VERSION ""

NS_ :

BS_:

BU_: ACC GW LAS BDC mADC FC APA HPP

BO_ 652 GW_28C: 8 GW
 SG_ GW_MFS_HODCalibratedStatus : 29|1@0+ (1,0) [0|1] ""  FC,mADC
 SG_ GW_MFS_HODLinStatus : 28|1@0+ (1,0) [0|1] ""  FC,mADC
 SG_ GW_MFS_HODAppStatus : 27|1@0+ (1,0) [0|1] ""  FC,mADC
 SG_ GW_MFS_HODSenserStatus : 47|1@0+ (1,0) [0|1] ""  FC,mADC
 SG_ GW_MFS_HODSystemStatus : 23|3@0+ (1,0) [0|7] ""  FC,mADC
 SG_ GW_MFS_handsoffAbilityDetect : 26|3@0+ (1,0) [0|7] ""  FC,mADC
 SG_ GW_MFS_handsoffDetectResult : 20|3@0+ (1,0) [0|7] ""  ACC,LAS,FC,mADC
 SG_ GW_MFS_CRCCheck_28C : 63|8@0+ (1,0) [0|255] ""  ACC,FC,LAS,mADC
 SG_ GW_MFS_RollingCounter_28C : 51|4@0+ (1,0) [0|15] ""  ACC,FC,LAS,mADC
 SG_ GW_MFS_DiagInfoSW_28C : 42|3@0+ (1,0) [0|7] ""  ACC,LAS,FC,mADC
 SG_ GW_MFS_GearshiftReduce_switch : 53|2@0+ (1,0) [0|3] "" Vector__XXX
 SG_ GW_MFS_GearshiftPlus_switch : 55|2@0+ (1,0) [0|3] "" Vector__XXX
 SG_ GW_MFS_EPS_switch : 15|2@0+ (1,0) [0|3] "" Vector__XXX
 SG_ GW_MFS_ERSReduce_switch : 46|2@0+ (1,0) [0|3] "" Vector__XXX
 SG_ GW_MFS_ERSPlus_switch : 44|2@0+ (1,0) [0|3] "" Vector__XXX
 SG_ GW_MFS_IACCenable_switch_signal : 13|2@0+ (1,0) [0|3] ""  ACC,FC,LAS,mADC
 SG_ GW_MFS_LIM_switch_signal : 11|2@0+ (1,0) [0|3] ""  FC,mADC
 SG_ GW_MFS_DIST_switch_signal : 9|2@0+ (1,0) [0|3] ""  ACC,LAS,FC,mADC
 SG_ GW_MFS_SETReduce_switch_signal : 7|2@0+ (1,0) [0|3] ""  ACC,LAS,FC,mADC
 SG_ GW_MFS_RESPlus_switch_signal : 5|2@0+ (1,0) [0|3] ""  ACC,LAS,FC,mADC
 SG_ GW_MFS_Cancle_switch_signal : 3|2@0+ (1,0) [0|3] ""  ACC,LAS,FC,mADC
 SG_ GW_MFS_Crusie_switch_signal : 1|2@0+ (1,0) [0|3] ""  ACC,LAS,FC,mADC
 SG_ GW_MFS_DISTReduce_switch_signal : 31|2@0+ (1,0) [0|3] ""  LAS,FC,ACC
 SG_ GW_MFS_DISTPlus_switch_signal : 17|2@0+ (1,0) [0|3] ""  LAS,FC,ACC

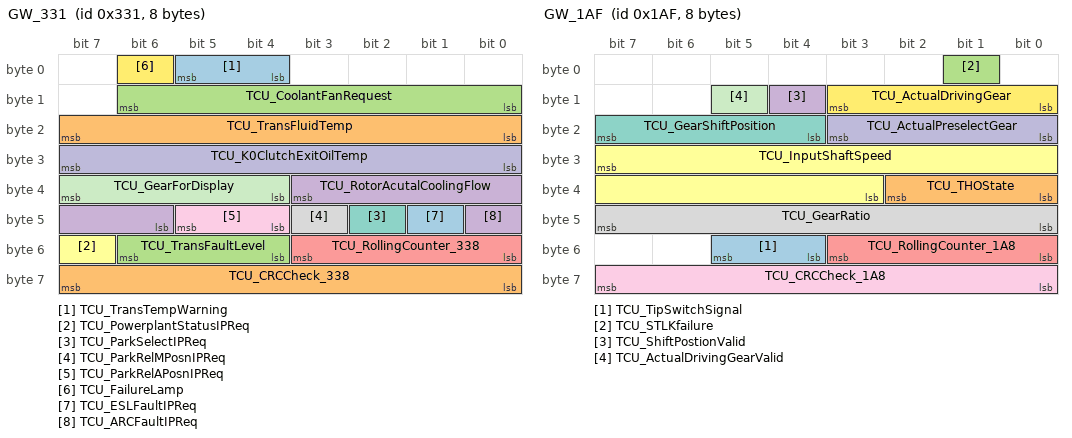
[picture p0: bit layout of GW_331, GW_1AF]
BO_ 817 GW_331: 8 GW
 SG_ TCU_TransTempWarning : 5|2@0+ (1,0) [0|3] "" Vector__XXX
 SG_ TCU_TransFluidTemp : 23|8@0+ (1,-40) [-40|214] "deg C" Vector__XXX
 SG_ TCU_TransFaultLevel : 54|3@0+ (1,0) [0|7] ""  ACC,LAS,APA,HPP
 SG_ TCU_RotorAcutalCoolingFlow : 35|6@0+ (0.1,0) [0|5] "L/min" Vector__XXX
 SG_ TCU_RollingCounter_338 : 51|4@0+ (1,0) [0|15] ""  APA
 SG_ TCU_PowerplantStatusIPReq : 55|1@0+ (1,0) [0|1] "" Vector__XXX
 SG_ TCU_ParkSelectIPReq : 42|1@0+ (1,0) [0|1] "" Vector__XXX
 SG_ TCU_ParkRelMPosnIPReq : 43|1@0+ (1,0) [0|1] "" Vector__XXX
 SG_ TCU_ParkRelAPosnIPReq : 45|2@0+ (1,0) [0|3] "" Vector__XXX
 SG_ TCU_K0ClutchExitOilTemp : 31|8@0+ (1,-40) [-40|214] "deg C" Vector__XXX
 SG_ TCU_GearForDisplay : 39|4@0+ (1,0) [0|15] "" Vector__XXX
 SG_ TCU_FailureLamp : 6|1@0+ (1,0) [0|1] "" Vector__XXX
 SG_ TCU_ESLFaultIPReq : 41|1@0+ (1,0) [0|1] "" Vector__XXX
 SG_ TCU_CRCCheck_338 : 63|8@0+ (1,0) [0|255] ""  APA
 SG_ TCU_CoolantFanRequest : 14|7@0+ (1,0) [0|100] "%" Vector__XXX
 SG_ TCU_ARCFaultIPReq : 40|1@0+ (1,0) [0|1] "" Vector__XXX

BO_ 431 GW_1AF: 8 GW
 SG_ TCU_TipSwitchSignal : 53|2@0+ (1,0) [0|3] "" Vector__XXX
 SG_ TCU_THOState : 34|3@0+ (1,0) [0|7] "" Vector__XXX
 SG_ TCU_STLKfailure : 1|1@0+ (1,0) [0|1] "" Vector__XXX
 SG_ TCU_ShiftPostionValid : 12|1@0+ (1,0) [0|1] ""  ACC,LAS,FC,APA,mADC
 SG_ TCU_RollingCounter_1A8 : 51|4@0+ (1,0) [0|15] ""  mADC,APA,ACC,LAS,FC,HPP
 SG_ TCU_InputShaftSpeed : 31|13@0+ (2.5,-10235) [-10235|10240] "Rpm" Vector__XXX
 SG_ TCU_GearShiftPosition : 23|4@0+ (1,0) [0|15] ""  APA,ACC,LAS,FC,HPP,mADC
 SG_ TCU_GearRatio : 47|8@0+ (0.1,0) [0|25.4] "" Vector__XXX
 SG_ TCU_CRCCheck_1A8 : 63|8@0+ (1,0) [0|255] ""  mADC,APA,ACC,LAS,FC,HPP
 SG_ TCU_ActualPreselectGear : 19|4@0+ (1,0) [0|15] "" Vector__XXX
 SG_ TCU_ActualDrivingGearValid : 13|1@0+ (1,0) [0|1] ""  APA,ACC,LAS,FC,HPP
 SG_ TCU_ActualDrivingGear : 11|4@0+ (1,0) [0|15] ""  APA,ACC,LAS,FC,HPP

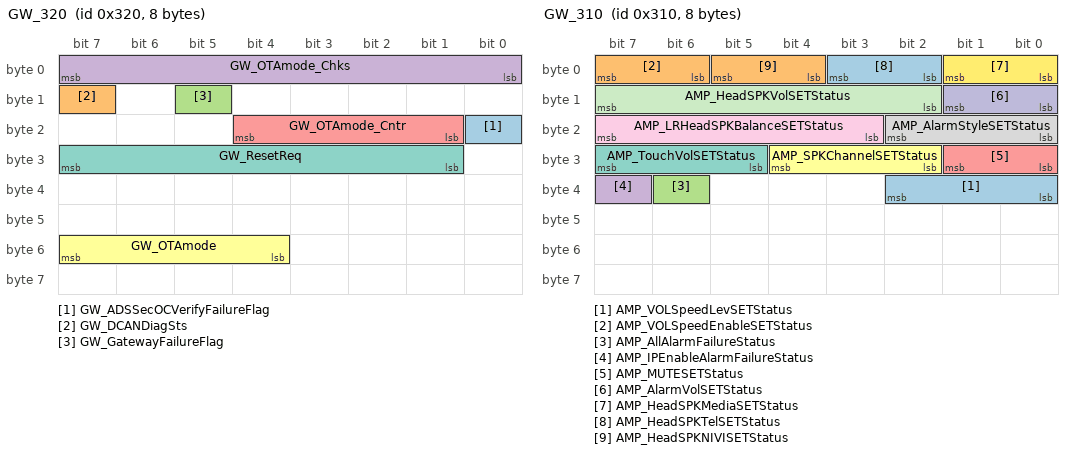
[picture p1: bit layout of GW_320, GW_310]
BO_ 800 GW_320: 8 GW
 SG_ GW_ADSSecOCVerifyFailureFlag : 16|1@0+ (1,0) [0|1] ""  mADC
 SG_ GW_DCANDiagSts : 15|1@0+ (1,0) [0|1] ""  mADC
 SG_ GW_GatewayFailureFlag : 13|1@0+ (1,0) [0|1] ""  mADC
 SG_ GW_OTAmode_Chks : 7|8@0+ (1,0) [0|255] ""  mADC
 SG_ GW_OTAmode_Cntr : 20|4@0+ (1,0) [0|15] ""  mADC
 SG_ GW_OTAmode : 55|4@0+ (1,0) [0|15] ""  mADC
 SG_ GW_ResetReq : 31|7@0+ (1,0) [0|127] ""  ACC,FC,LAS,APA,mADC

BO_ 922 LAS_39A: 64 LAS
 SG_ LAS_RoadFeature : 395|4@0+ (1,0) [0|15] ""  GW,mADC
 SG_ LAS_RD4LongDistence : 407|8@0+ (1,0) [0|255] ""  GW,mADC
 SG_ LAS_RD3LongDistence : 415|8@0+ (1,0) [0|255] ""  GW,mADC
 SG_ LAS_RD2LongDistence : 423|8@0+ (1,0) [0|255] ""  GW,mADC
 SG_ LAS_RD1LongDistence : 431|8@0+ (1,0) [0|255] ""  GW,mADC
 SG_ LAS_RD4RoadInforAvailable : 399|2@0+ (1,0) [0|3] ""  GW,mADC
 SG_ LAS_RD3RoadInforAvailable : 439|2@0+ (1,0) [0|3] ""  GW,mADC
 SG_ LAS_RD2RoadInforAvailable : 397|2@0+ (1,0) [0|3] ""  GW,mADC
 SG_ LAS_RD1RoadInforAvailable : 437|2@0+ (1,0) [0|3] ""  GW,mADC
 SG_ LAS_RollingCounter_579 : 435|4@0+ (1,0) [0|15] ""  GW,mADC
 SG_ LAS_CRCCheck_579 : 447|8@0+ (1,0) [0|255] ""  GW,mADC
 SG_ LAS_TSRSpeedLimitType : 7|2@0+ (1,0) [0|3] ""  GW
 SG_ ACC_RollingCounter_39A : 491|4@0+ (1,0) [0|15] ""  GW,mADC
 SG_ ACC_CRCCheck_39A : 503|16@0+ (1,0) [0|65535] ""  GW,mADC
 SG_ LAS_CRCCheck_3C0 : 191|8@0+ (1,0) [0|255] ""  GW,mADC
 SG_ LAS_RollingCounter_3C0 : 179|4@0+ (1,0) [0|15] ""  GW,mADC
 SG_ LAS_CRCCheck_3D4 : 127|8@0+ (1,0) [0|255] ""  GW,mADC
 SG_ LAS_RollingCounter_3D4 : 115|4@0+ (1,0) [0|15] ""  GW,mADC
 SG_ LAS_CRCCheck_332 : 63|8@0+ (1,0) [0|255] ""  GW,mADC
 SG_ LAS_RollingCounter_332 : 51|4@0+ (1,0) [0|15] ""  GW,mADC
 SG_ LAS_OverspeedSoundWarningEnSt : 27|1@0+ (1,0) [0|1] ""  GW,mADC
 SG_ LAS_TSREnable : 30|1@0+ (1,0) [0|1] ""  GW,mADC
 SG_ LAS_HMAEnableStatus : 22|1@0+ (1,0) [0|1] ""  GW,mADC
 SG_ LAS_HMALightDistribution : 8|1@0+ (1,0) [0|1] ""  GW,mADC
 SG_ LAS_HMAStatus : 44|2@0+ (1,0) [0|3] ""  GW,mADC
 SG_ LAS_TSRHostSpdLimitUnits : 41|2@0+ (1,0) [0|3] ""  GW,mADC
 SG_ LAS_TSRHostSpdLimit : 39|8@0+ (1,0) [0|255] ""  GW,mADC
 SG_ LAS_TSRStatus : 26|3@0+ (1,0) [0|7] ""  GW,mADC
 SG_ LAS_FrontCameraCalibrationStatus : 20|2@0+ (1,0) [0|3] ""  GW,mADC
 SG_ LAS_FrontCameraFailureStatus : 17|2@0+ (1,0) [0|3] ""  GW,mADC
 SG_ LAS_OverspeedWarningOffset : 14|6@0+ (1,-10) [-10|47] "km/h"  GW,mADC
 SG_ LAS_OverspeedWarningEnableStatus : 15|1@0+ (1,0) [0|1] ""  GW,mADC
 SG_ LAS_OverspeedSoundWarning : 2|1@0+ (1,0) [0|1] ""  GW,mADC
 SG_ LAS_OverspeedVisualWarning : 5|1@0+ (1,0) [0|1] ""  GW,mADC
 SG_ LAS_CRCCheck_37D : 255|8@0+ (1,0) [0|255] ""  GW,mADC
 SG_ LAS_RollingCounter_37D : 243|4@0+ (1,0) [0|15] ""  GW,mADC
 SG_ LAS_CrosswalkLngRange_HLane : 263|8@0+ (1,0) [0|255] ""  GW,mADC

BO_ 784 GW_310: 8 GW
 SG_ AMP_VOLSpeedLevSETStatus : 34|3@0+ (1,0) [0|7] "" Vector__XXX
 SG_ AMP_VOLSpeedEnableSETStatus : 7|2@0+ (1,0) [0|3] "" Vector__XXX
 SG_ AMP_AllAlarmFailureStatus : 38|1@0+ (1,0) [0|1] ""  ACC,LAS
 SG_ AMP_IPEnableAlarmFailureStatus : 39|1@0+ (1,0) [0|1] ""  ACC,LAS
 SG_ AMP_MUTESETStatus : 25|2@0+ (1,0) [0|3] "" Vector__XXX
 SG_ AMP_SPKChannelSETStatus : 28|3@0+ (1,0) [0|7] "" Vector__XXX
 SG_ AMP_TouchVolSETStatus : 31|3@0+ (1,0) [0|7] "" Vector__XXX
 SG_ AMP_AlarmStyleSETStatus : 18|3@0+ (1,0) [0|7] "" Vector__XXX
 SG_ AMP_LRHeadSPKBalanceSETStatus : 23|5@0+ (1,-16) [-16|15] "" Vector__XXX
 SG_ AMP_AlarmVolSETStatus : 9|2@0+ (1,0) [0|3] "" Vector__XXX
 SG_ AMP_HeadSPKVolSETStatus : 15|6@0+ (1,0) [0|63] "" Vector__XXX
 SG_ AMP_HeadSPKMediaSETStatus : 1|2@0+ (1,0) [0|3] "" Vector__XXX
 SG_ AMP_HeadSPKTelSETStatus : 3|2@0+ (1,0) [0|3] "" Vector__XXX
 SG_ AMP_HeadSPKNIVISETStatus : 5|2@0+ (1,0) [0|3] "" Vector__XXX

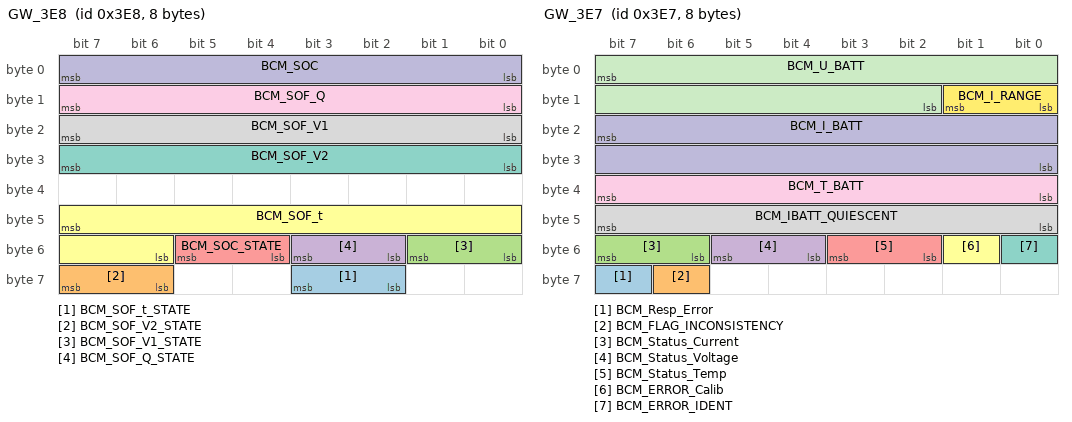
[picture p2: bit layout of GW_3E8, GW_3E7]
BO_ 1000 GW_3E8: 8 GW
 SG_ BCM_SOF_t_STATE : 59|2@0+ (1,0) [0|3] "" Vector__XXX
 SG_ BCM_SOF_V2_STATE : 63|2@0+ (1,0) [0|3] "" Vector__XXX
 SG_ BCM_SOF_V1_STATE : 49|2@0+ (1,0) [0|3] "" Vector__XXX
 SG_ BCM_SOF_Q_STATE : 51|2@0+ (1,0) [0|3] ""  ACC,LAS,FC
 SG_ BCM_SOC_STATE : 53|2@0+ (1,0) [0|3] "" Vector__XXX
 SG_ BCM_SOF_t : 47|10@0+ (1,0) [0|1023] "min" Vector__XXX
 SG_ BCM_SOF_V2 : 31|8@0+ (0.0625,0) [0|15.9375] "V" Vector__XXX
 SG_ BCM_SOF_V1 : 23|8@0+ (0.0625,0) [0|15.9375] "V" Vector__XXX
 SG_ BCM_SOF_Q : 15|8@0+ (0.5,0) [0|127.5] "Ah"  ACC,LAS,FC,APA
 SG_ BCM_SOC : 7|8@0+ (1,0) [0|255] "%"  APA

BO_ 999 GW_3E7: 8 GW
 SG_ BCM_Resp_Error : 63|1@0+ (1,0) [0|1] "" Vector__XXX
 SG_ BCM_FLAG_INCONSISTENCY : 62|1@0+ (1,0) [0|1] "" Vector__XXX
 SG_ BCM_Status_Current : 55|2@0+ (1,0) [0|3] "" Vector__XXX
 SG_ BCM_Status_Voltage : 53|2@0+ (1,0) [0|3] "" Vector__XXX
 SG_ BCM_Status_Temp : 51|2@0+ (1,0) [0|3] ""  ACC,LAS,FC
 SG_ BCM_ERROR_Calib : 49|1@0+ (1,0) [0|1] "" Vector__XXX
 SG_ BCM_ERROR_IDENT : 48|1@0+ (1,0) [0|1] "" Vector__XXX
 SG_ BCM_IBATT_QUIESCENT : 47|8@0+ (0.00390625,0) [0|0.99609375] "A" Vector__XXX
 SG_ BCM_T_BATT : 39|8@0+ (1,-40) [-40|215] "°C"  ACC,LAS,FC
 SG_ BCM_I_BATT : 23|16@0+ (1,0) [7168|65535] "A" Vector__XXX
 SG_ BCM_U_BATT : 7|14@0+ (0.0009765625,3) [3|18] "V" Vector__XXX
 SG_ BCM_I_RANGE : 9|2@0+ (1,0) [0|3] "" Vector__XXX

BO_ 906 GW_38A: 8 GW
 SG_ GW_MFS_WeChat_switch_signal : 39|2@0+ (1,0) [0|3] "" Vector__XXX
 SG_ GW_MFS_AVM_switch : 44|2@0+ (1,0) [0|3] ""  APA
 SG_ GW_MFS_DiagInfoSW_38A : 42|3@0+ (1,0) [0|7] "" Vector__XXX
 SG_ GW_MFS_Cust_switch : 17|2@0+ (1,0) [0|3] "" Vector__XXX
 SG_ GW_MFS_DVR_switch : 15|2@0+ (1,0) [0|3] ""  APA
 SG_ GW_MFS_Mode_switch : 13|2@0+ (1,0) [0|3] "" Vector__XXX
 SG_ GW_MFS_VolReduce_switch : 21|2@0+ (1,0) [0|3] ""  LAS,ACC
 SG_ GW_MFS_VolPlus_switch : 19|2@0+ (1,0) [0|3] ""  LAS,ACC
 SG_ GW_MFS_UP_switch : 5|2@0+ (1,0) [0|3] ""  LAS,ACC
 SG_ GW_MFS_Speech_switch : 11|2@0+ (1,0) [0|3] ""  LAS,ACC
 SG_ GW_MFS_SeekPlus_switch : 25|2@0+ (1,0) [0|3] ""  LAS,ACC
 SG_ GW_MFS_Right_switch : 3|2@0+ (1,0) [0|3] ""  LAS,ACC
 SG_ GW_MFS_OK_switch : 9|2@0+ (1,0) [0|3] ""  LAS,ACC
 SG_ GW_MFS_Mute_switch : 23|2@0+ (1,0) [0|3] ""  LAS,ACC
 SG_ GW_MFS_Left_switch : 1|2@0+ (1,0) [0|3] ""  LAS,ACC
 SG_ GW_MFS_Hungup_switch_signal : 29|2@0+ (1,0) [0|3] ""  LAS,ACC
 SG_ GW_MFS_Down_switch : 7|2@0+ (1,0) [0|3] ""  LAS,ACC
 SG_ GW_MFS_Answer_switch_signal : 31|2@0+ (1,0) [0|3] ""  LAS,ACC
 SG_ GW_MFS_SeekReduce_switch : 27|2@0+ (1,0) [0|3] ""  LAS,ACC

BO_ 585 GW_249: 8 GW

BO_ 610 GW_262: 8 GW
 SG_ PEPS_RemoteStartKeyStatus : 43|2@0+ (1,0) [0|3] ""  APA
 SG_ PEPS_APA_PowerMirrorFoldFeedback : 26|2@0+ (1,0) [0|3] ""  APA,mADC
 SG_ PEPS_APARemoteParkingOff : 53|1@0+ (1,0) [0|1] ""  APA,mADC
 SG_ PEPS_KeyStandbyPositionIndicator : 54|1@0+ (1,0) [0|1] "" Vector__XXX
 SG_ PEPS_CRCCheck_262 : 63|8@0+ (1,0) [0|255] ""  APA,mADC
 SG_ PEPS_RollingCounter_262 : 51|4@0+ (1,0) [0|15] ""  APA,mADC
 SG_ PEPS_PEPSFailStatus : 55|1@0+ (1,0) [0|1] ""  APA,mADC
 SG_ PEPS_PowerDistributionFaultBit : 47|1@0+ (1,0) [0|1] "" Vector__XXX
 SG_ PEPS_IMMOFeedback : 45|2@0+ (1,0) [0|3] "" Vector__XXX
 SG_ PEPS_EngineStartupInhibitFB : 46|1@0+ (1,0) [0|1] "" Vector__XXX
 SG_ PEPS_RemoteStartFeedback : 31|5@0+ (1,0) [0|31] ""  mADC
 SG_ PEPS_EngineStartupInhibitSts : 24|1@0+ (1,0) [0|1] "" Vector__XXX
 SG_ PEPS_PowerDistributionStatus : 23|2@0+ (1,0) [0|3] "" Vector__XXX
 SG_ PEPS_UnallowStartSignal_Not_PN : 19|1@0+ (1,0) [0|1] "" Vector__XXX
 SG_ PEPS_IMMOFailedAlarmsignal : 18|1@0+ (1,0) [0|1] "" Vector__XXX
 SG_ PEPS_UnallowStart_ESCL_LOCK : 21|1@0+ (1,0) [0|1] "" Vector__XXX
 SG_ PEPS_UnallowStart_ESCL_Error : 15|1@0+ (1,0) [0|1] "" Vector__XXX
 SG_ PEPS_StartIndicatorSignal : 7|1@0+ (1,0) [0|1] "" Vector__XXX
 SG_ PEPS_StartupButtonSignal : 17|2@0+ (1,0) [0|3] "" Vector__XXX
 SG_ PEPS_APA_CloseWinFeedback : 11|2@0+ (1,0) [0|3] ""  APA,mADC
 SG_ PEPS_RemoteControlACReq : 9|2@0+ (1,0) [0|3] "" Vector__XXX
 SG_ PEPS_RemoteAPADoneKeyOffReq : 6|2@0+ (1,0) [0|3] ""  APA,mADC
 SG_ PEPS_APA_Engine0ffFeedback : 4|2@0+ (1,0) [0|3] ""  APA,mADC
 SG_ PEPS_APA_LockFeedback : 2|2@0+ (1,0) [0|3] ""  APA,mADC
 SG_ PEPS_APARemoteParkingOn : 0|1@0+ (1,0) [0|1] ""  APA,mADC

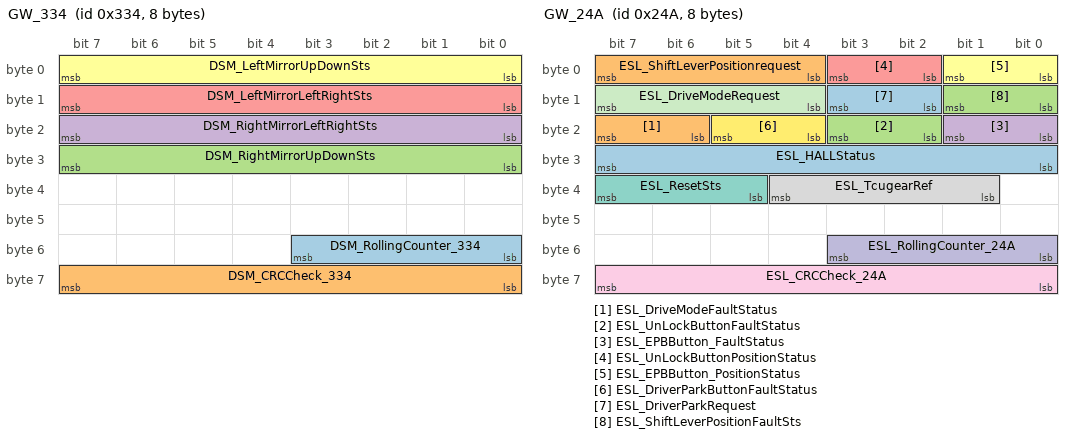
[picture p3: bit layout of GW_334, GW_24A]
BO_ 820 GW_334: 8 GW
 SG_ DSM_RollingCounter_334 : 51|4@0+ (1,0) [0|15] ""  APA
 SG_ DSM_CRCCheck_334 : 63|8@0+ (1,0) [0|255] ""  APA
 SG_ DSM_RightMirrorUpDownSts : 31|8@0+ (0.5,0) [0|127.5] "%"  APA
 SG_ DSM_RightMirrorLeftRightSts : 23|8@0+ (0.5,0) [0|127.5] "%"  APA
 SG_ DSM_LeftMirrorLeftRightSts : 15|8@0+ (0.5,0) [0|127.5] "%"  APA
 SG_ DSM_LeftMirrorUpDownSts : 7|8@0+ (0.5,0) [0|127.5] "%"  APA

BO_ 917 GW_395: 64 GW
 SG_ TBOX_EseUpdataHUWakeUpReq : 11|1@0+ (1,0) [0|1] "" Vector__XXX
 SG_ TBOX_RemoteInstallReq : 57|2@0+ (1,0) [0|3] "" Vector__XXX
 SG_ TBOX_RemotePaVentilatieReq : 60|3@0+ (1,0) [0|7] "" Vector__XXX
 SG_ TBOX_RemoteDrVentilatieReq : 63|3@0+ (1,0) [0|7] "" Vector__XXX
 SG_ TBOX_BCallStatus : 23|3@0+ (1,0) [0|7] "" Vector__XXX
 SG_ TBOX_AudioRequest : 14|2@0+ (1,0) [0|3] "" Vector__XXX
 SG_ TBOX_ChangePartStatus : 12|1@0+ (1,0) [0|1] "" Vector__XXX
 SG_ TBOX_CallStatus : 10|3@0+ (1,0) [0|7] "" Vector__XXX
 SG_ TBOX_RemoteAirCleanReq : 53|2@0+ (1,0) [0|3] "" Vector__XXX
 SG_ TBOX_RemoteAirQualityInquire : 49|2@0+ (1,0) [0|3] "" Vector__XXX
 SG_ TBOX_RemoteSteerWheelHotReq : 47|2@0+ (1,0) [0|3] "" Vector__XXX
 SG_ TBOX_RemoteDriverSeatHotReq : 45|3@0+ (1,0) [0|7] "" Vector__XXX
 SG_ TBOX_RemotePassangerSeatHotReq : 42|3@0+ (1,0) [0|7] "" Vector__XXX
 SG_ TBOX_SearchCarReq : 39|2@0+ (1,0) [0|3] "" Vector__XXX
 SG_ TBOX_RmoteTrunk : 37|2@0+ (1,0) [0|3] "" Vector__XXX
 SG_ TBOX_RmoteRoof : 35|2@0+ (1,0) [0|3] "" Vector__XXX
 SG_ TBOX_RemoteACStartupReq : 33|2@0+ (1,0) [0|3] "" Vector__XXX
 SG_ TBOX_VehicleStatusDemandReq : 31|1@0+ (1,0) [0|1] "" Vector__XXX
 SG_ TBOX_RemoteStartRunTime : 30|3@0+ (1,0) [0|7] "" Vector__XXX
 SG_ TBOX_VINMatchStatus : 27|2@0+ (1,0) [0|3] "" Vector__XXX
 SG_ TBOX_VINReq : 25|2@0+ (1,0) [0|3] "" Vector__XXX
 SG_ TBOX_ACTempValueReq : 20|5@0+ (1,0) [0|31] "degreeC" Vector__XXX
 SG_ TBOX_CarRemind : 15|1@0+ (1,0) [0|1] "" Vector__XXX
 SG_ TBOX_RemoteEngineStartupReq : 7|2@0+ (1,0) [0|3] "" Vector__XXX
 SG_ TBOX_EngineStartupInhibit : 5|2@0+ (1,0) [0|3] "" Vector__XXX
 SG_ TBOX_LockCommand : 3|2@0+ (1,0) [0|3] "" Vector__XXX
 SG_ TBox_ResetFlag_395 : 489|2@0+ (1,0) [0|3] ""  APA
 SG_ TBox_MesssageCounter_395 : 495|6@0+ (1,0) [0|63] ""  APA
 SG_ TBox_Authenticator_395 : 503|16@0+ (1,0) [0|0] ""  APA
 SG_ TBOX_APARemoteDriveReq : 95|3@0+ (1,0) [0|7] ""  APA
 SG_ TBOX_HZPFunctionReq : 102|3@0+ (1,0) [0|7] ""  APA
 SG_ TBOX_HZPControlEnable : 99|4@0+ (1,0) [0|15] ""  APA
 SG_ TBOX_SignalStrength : 89|3@0+ (1,0) [0|7] ""  APA,mADC
 SG_ TBOX_SignalType : 92|3@0+ (1,0) [0|7] ""  APA,mADC
 SG_ TBOX_APA_SignalDelay : 87|4@0+ (1,0) [0|15] ""  APA,mADC
 SG_ TBOX_APA_VideoDelay : 75|4@0+ (1,0) [0|15] ""  APA
 SG_ TBOX_AVM_DisplayForm : 111|3@0+ (1,0) [0|7] ""  APA
 SG_ TBOX_TurnRight : 81|1@0+ (1,0) [0|1] ""  APA
 SG_ TBOX_TurnLeft : 80|1@0+ (1,0) [0|1] ""  APA
 SG_ TBOX_Verticalforward : 76|1@0+ (1,0) [0|1] ""  APA
 SG_ TBOX_Verticalbackward : 77|1@0+ (1,0) [0|1] ""  APA
 SG_ TBOX_APAPOCModeSelect : 66|3@0+ (1,0) [0|7] ""  APA
 SG_ TBOX_APAFuctionSelection : 79|2@0+ (1,0) [0|3] ""  APA
 SG_ TBOX_APAManeuverSuspend : 67|1@0+ (1,0) [0|1] ""  APA
 SG_ TBOX_APAManeuverStart : 68|1@0+ (1,0) [0|1] ""  APA
 SG_ TBOX_APAManeuverCancel : 69|1@0+ (1,0) [0|1] ""  APA
 SG_ TBOX_APAmoduleEnable : 71|2@0+ (1,0) [0|3] ""  APA,mADC
 SG_ TBOX_RemoteDisReq : 50|1@0+ (1,0) [0|1] ""  APA,mADC
 SG_ TBOX_VehicleVedioDetectReq : 1|2@0+ (1,0) [0|3] ""  APA,mADC
 SG_ TBOX_RemoteDetectReq : 55|2@0+ (1,0) [0|3] ""  APA,mADC

BO_ 394 GW_18A: 8 GW
 SG_ TCU_APAShiftGearRequestEnable : 2|2@0+ (1,0) [0|3] ""  APA,BDC
 SG_ TCU_APAdriverInterruption : 4|2@0+ (1,0) [0|3] ""  APA,mADC

BO_ 586 GW_24A: 8 GW
 SG_ ESL_HALLStatus : 31|8@0+ (1,0) [0|255] ""  BDC
 SG_ ESL_DriveModeFaultStatus : 23|2@0+ (1,0) [0|3] ""  BDC
 SG_ ESL_UnLockButtonFaultStatus : 19|2@0+ (1,0) [0|3] ""  BDC
 SG_ ESL_EPBButton_FaultStatus : 17|2@0+ (1,0) [0|3] ""  BDC
 SG_ ESL_UnLockButtonPositionStatus : 3|2@0+ (1,0) [0|3] ""  BDC
 SG_ ESL_EPBButton_PositionStatus : 1|2@0+ (1,0) [0|3] ""  BDC
 SG_ ESL_ResetSts : 39|3@0+ (1,0) [0|7] ""  BDC
 SG_ ESL_TcugearRef : 36|4@0+ (1,0) [0|15] ""  BDC
 SG_ ESL_CRCCheck_24A : 63|8@0+ (1,0) [0|255] ""  BDC,APA,mADC
 SG_ ESL_RollingCounter_24A : 51|4@0+ (1,0) [0|15] ""  BDC,APA,mADC
 SG_ ESL_DriveModeRequest : 15|4@0+ (1,0) [0|15] ""  BDC,APA,mADC
 SG_ ESL_DriverParkButtonFaultStatus : 21|2@0+ (1,0) [0|3] ""  BDC,APA,mADC
 SG_ ESL_DriverParkRequest : 11|2@0+ (1,0) [0|3] ""  BDC,APA,mADC
 SG_ ESL_ShiftLeverPositionrequest : 7|4@0+ (1,0) [0|15] ""  BDC,APA,ACC,LAS,mADC
 SG_ ESL_ShiftLeverPositionFaultSts : 9|2@0+ (1,0) [0|3] ""  BDC,APA,ACC,LAS,mADC

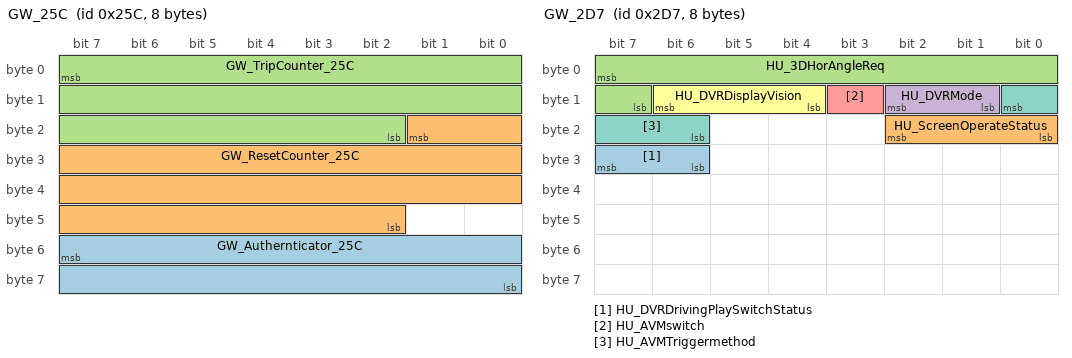
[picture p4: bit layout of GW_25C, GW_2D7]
BO_ 604 GW_25C: 8 GW
 SG_ GW_Authernticator_25C : 55|16@0+ (1,0) [0|65535] ""  APA,mADC
 SG_ GW_ResetCounter_25C : 17|24@0+ (1,0) [0|16777215] ""  APA,mADC
 SG_ GW_TripCounter_25C : 7|22@0+ (1,0) [0|4194303] ""  APA,mADC

BO_ 727 GW_2D7: 8 GW
 SG_ HU_DVRDrivingPlaySwitchStatus : 31|2@0+ (1,0) [0|3] ""  APA
 SG_ HU_ScreenOperateStatus : 18|3@0+ (1,0) [0|7] ""  APA
 SG_ HU_3DHorAngleReq : 7|9@0+ (1,0) [0|360] "°"  APA
 SG_ HU_DVRMode : 10|2@0+ (1,0) [0|3] ""  APA
 SG_ HU_AVMswitch : 11|1@0+ (1,0) [0|1] ""  APA
 SG_ HU_DVRDisplayVision : 14|3@0+ (1,0) [0|7] ""  APA
 SG_ HU_AVMTriggermethod : 8|3@0+ (1,0) [0|7] ""  APA

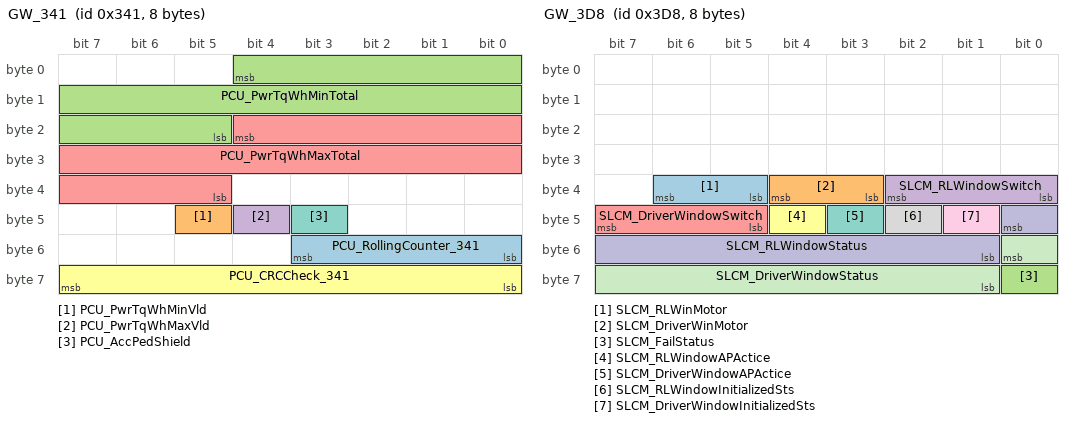
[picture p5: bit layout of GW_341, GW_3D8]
BO_ 833 GW_341: 8 GW
 SG_ PCU_RollingCounter_341 : 51|4@0+ (1,0) [0|15] ""  APA
 SG_ PCU_PwrTqWhMinVld : 45|1@0+ (1,0) [0|1] ""  APA,ACC,LAS,FC,mADC
 SG_ PCU_PwrTqWhMinTotal : 4|16@0+ (1,-32768) [-32768|32767] "Nm"  APA,ACC,LAS,FC,mADC
 SG_ PCU_PwrTqWhMaxVld : 44|1@0+ (1,0) [0|1] ""  APA,ACC,LAS,FC,mADC
 SG_ PCU_PwrTqWhMaxTotal : 20|16@0+ (1,-32768) [-32768|32767] "Nm"  APA,ACC,LAS,FC,mADC
 SG_ PCU_CRCCheck_341 : 63|8@0+ (1,0) [0|255] ""  APA
 SG_ PCU_AccPedShield : 43|1@0+ (1,0) [0|1] ""  mADC,APA

BO_ 982 GW_3D6: 8 GW
 SG_ SLCM_RRWindowStatus : 40|8@0+ (0.5,0) [0|127.5] "%"  APA,mADC
 SG_ SLCM_FRWindowStatus : 48|8@0+ (0.5,0) [0|127.5] "%"  APA,mADC

BO_ 984 GW_3D8: 8 GW
 SG_ SLCM_RLWinMotor : 38|2@0+ (1,0) [0|3] "" Vector__XXX
 SG_ SLCM_DriverWinMotor : 36|2@0+ (1,0) [0|3] "" Vector__XXX
 SG_ SLCM_FailStatus : 56|1@0+ (1,0) [0|1] "" Vector__XXX
 SG_ SLCM_RLWindowSwitch : 34|3@0+ (1,0) [0|7] "" Vector__XXX
 SG_ SLCM_DriverWindowSwitch : 47|3@0+ (1,0) [0|7] "" Vector__XXX
 SG_ SLCM_RLWindowAPActice : 44|1@0+ (1,0) [0|1] "" Vector__XXX
 SG_ SLCM_DriverWindowAPActice : 43|1@0+ (1,0) [0|1] "" Vector__XXX
 SG_ SLCM_RLWindowInitializedSts : 42|1@0+ (1,0) [0|1] "" Vector__XXX
 SG_ SLCM_DriverWindowInitializedSts : 41|1@0+ (1,0) [0|1] "" Vector__XXX
 SG_ SLCM_RLWindowStatus : 40|8@0+ (0.5,0) [0|127.5] "%"  APA,mADC
 SG_ SLCM_DriverWindowStatus : 48|8@0+ (0.5,0) [0|127.5] "%"  APA,mADC

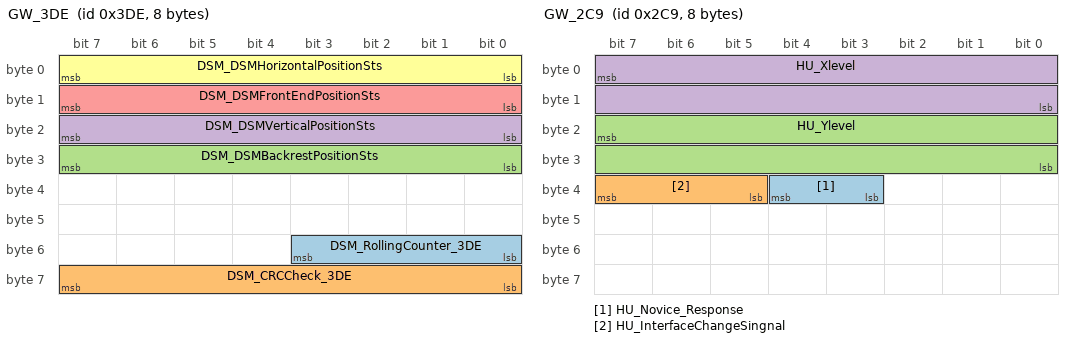
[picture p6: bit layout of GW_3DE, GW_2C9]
BO_ 990 GW_3DE: 8 GW
 SG_ DSM_RollingCounter_3DE : 51|4@0+ (1,0) [0|15] ""  APA
 SG_ DSM_CRCCheck_3DE : 63|8@0+ (1,0) [0|255] ""  APA
 SG_ DSM_DSMBackrestPositionSts : 31|8@0+ (0.5,0) [0|127.5] "%"  APA
 SG_ DSM_DSMVerticalPositionSts : 23|8@0+ (0.5,0) [0|127.5] "%"  APA
 SG_ DSM_DSMFrontEndPositionSts : 15|8@0+ (0.5,0) [0|127.5] "%"  APA
 SG_ DSM_DSMHorizontalPositionSts : 7|8@0+ (0.5,0) [0|127.5] "%"  APA

BO_ 1006 GW_3EE: 8 GW
 SG_ GW_SafCertSts : 7|2@0+ (1,0) [0|3] ""  APA

BO_ 1712 GW_6B0: 8 GW
 SG_ GW_APA_AuthenticationStatus : 7|64@0+ (1,0) [0|0] ""  APA

BO_ 723 ACC_2D3: 64 ACC
 SG_ ACC_CRCCheck_283 : 127|8@0+ (1,0) [0|255] ""  GW,ACC,LAS
 SG_ ACC_RollingCounter_283 : 115|4@0+ (1,0) [0|15] ""  GW,ACC,LAS
 SG_ ACC_AEBTargetLatRelSpeed_for_SRS : 77|10@0+ (0.125,-64) [-64|63.875] "m/s"  GW,ACC,LAS,mADC
 SG_ ACC_AEBTargetLatRange_for_SRS : 71|10@0+ (0.1,-50) [-50|50] "m"  GW,ACC,LAS,mADC
 SG_ ACC_CRCCheckr_282 : 63|8@0+ (1,0) [0|255] ""  GW,ACC,LAS
 SG_ ACC_RollingCounter_282 : 51|4@0+ (1,0) [0|15] ""  GW,ACC,LAS
 SG_ ACC_AEBTargetProb_for_SRS : 38|7@0+ (1,0) [0|100] "%"  GW,ACC,LAS,mADC
 SG_ ACC_AEBTargetType_for_SRS : 26|4@0+ (1,0) [0|15] ""  GW,ACC,LAS,mADC
 SG_ ACC_AEBTargetTTC_for_SRS : 18|8@0+ (0.01,0.01) [0.01|2.5] "s"  GW,ACC,LAS,mADC
 SG_ ACC_AEBTargetRelSpeed_for_SRS : 11|9@0+ (1,-250) [-250|250] "km/h"  GW,ACC,LAS,mADC
 SG_ ACC_AEBTargetLngRange_for_SRS : 4|9@0+ (0.5,-70) [-70|180] "m"  GW,ACC,LAS,mADC
 SG_ ACC_AEBActive_for_SRS : 5|1@0+ (1,0) [0|1] ""  GW,ACC,LAS,mADC
 SG_ ACC_AEBStatus_for_SRS : 7|2@0+ (1,0) [0|3] ""  GW,ACC,LAS,mADC

BO_ 769 ACC_301: 8 ACC
 SG_ ACC_ResetSts : 7|3@0+ (1,0) [0|7] ""  GW

BO_ 780 LAS_30C: 8 LAS
 SG_ LAS_ResetSts : 7|3@0+ (1,0) [0|7] ""  FC,GW

BO_ 738 GW_2E2: 64 GW
 SG_ RLR_CRCCheck_2E2 : 503|16@0+ (1,0) [0|65535] ""  LAS
 SG_ RLR_RollingCounter_2E2 : 491|4@0+ (1,0) [0|15] ""  LAS
 SG_ RLR_ElkOBJ2_Measured : 313|2@0+ (1,0) [0|3] ""  LAS
 SG_ RLR_ElkOBJ2_ExistProb : 319|6@0+ (2,0) [0|100] "%"  LAS
 SG_ RLR_ElkOBJ2_Location : 305|2@0+ (1,0) [0|3] ""  LAS
 SG_ RLR_ElkOBJ2_RelAx : 298|9@0+ (0.0625,-16) [-16|15.9375] "m/s2"  LAS
 SG_ RLR_ElkOBJ2_RelAy : 292|10@0+ (0.03125,-16) [-16|15.9688] "m/s2"  LAS
 SG_ RLR_ElkOBJ2_RelVx : 272|12@0+ (0.0625,-128) [-128|127.938] "m/s"  LAS
 SG_ RLR_ElkOBJ2_RelVy : 266|10@0+ (0.125,-64) [-64|63.875] "m/s"  LAS
 SG_ RLR_ElkOBJ2_Dx : 263|13@0+ (0.0625,-256) [-256|255.938] "m"  LAS
 SG_ RLR_ElkOBJ2_RefPointLoc : 251|3@0+ (1,0) [0|7] ""  LAS
 SG_ RLR_ElkOBJ2_Dy : 246|11@0+ (0.125,-128) [-128|127.875] "m"  LAS
 SG_ RLR_ElkOBJ2_HeadingAngle : 224|10@0+ (0.01,-3.14) [-3.14|3.14] "rad"  LAS
 SG_ RLR_ElkOBJ2_Length : 217|9@0+ (0.05,0) [0|25.5] "m"  LAS
 SG_ RLR_ElkOBJ2_Height : 210|9@0+ (0.01,0) [0|5.11] "m"  LAS
 SG_ RLR_ElkOBJ2_Width : 205|11@0+ (0.01,0) [0|12] "m"  LAS
 SG_ RLR_ElkOBJ2_Type : 192|3@0+ (1,0) [0|7] ""  LAS
 SG_ RLR_ElkOBJ2_Track_ID : 199|7@0+ (1,0) [0|127] ""  LAS
 SG_ RLR_ElkOBJ2_RefPointDx : 168|13@0+ (0.0625,-256) [-256|255.938] "m"  LAS
 SG_ RLR_ElkOBJ2_RefPointDy : 163|11@0+ (0.125,-128) [-128|127.875] "m"  LAS
 SG_ RLR_ElkOBJ2_ObstacleProb : 153|6@0+ (2,0) [0|100] "%"  LAS
 SG_ RLR_ElkOBJ1_RefPointDx : 150|13@0+ (0.0625,-256) [-256|255.938] "m"  LAS
 SG_ RLR_ElkOBJ1_RefPointDy : 129|11@0+ (0.125,-128) [-128|127.875] "m"  LAS
 SG_ RLR_ElkOBJ1_ObstacleProb : 135|6@0+ (2,0) [0|100] "%"  LAS
 SG_ RLR_ElkOBJ1_Measured : 121|2@0+ (1,0) [0|3] ""  LAS
 SG_ RLR_ElkOBJ1_ExistProb : 127|6@0+ (2,0) [0|100] "%"  LAS
 SG_ RLR_ElkOBJ1_Location : 113|2@0+ (1,0) [0|3] ""  LAS
 SG_ RLR_ElkOBJ1_RelAx : 106|9@0+ (0.0625,-16) [-16|15.9375] "m/s2"  LAS
 SG_ RLR_ElkOBJ1_RelAy : 100|10@0+ (0.03125,-16) [-16|15.9688] "m/s2"  LAS
 SG_ RLR_ElkOBJ1_RelVx : 80|12@0+ (0.0625,-128) [-128|127.938] "m/s"  LAS
 SG_ RLR_ElkOBJ1_RelVy : 74|10@0+ (0.125,-64) [-64|63.875] "m/s"  LAS
 SG_ RLR_ElkOBJ1_Dx : 71|13@0+ (0.0625,-256) [-256|255.938] "m"  LAS
 SG_ RLR_ElkOBJ1_RefPointLoc : 59|3@0+ (1,0) [0|7] ""  LAS
 SG_ RLR_ElkOBJ1_Dy : 54|11@0+ (0.125,-128) [-128|127.875] "m"  LAS
 SG_ RLR_ElkOBJ1_HeadingAngle : 32|10@0+ (0.01,-3.14) [-3.14|3.14] "rad"  LAS
 SG_ RLR_ElkOBJ1_Length : 25|9@0+ (0.05,0) [0|25.5] "m"  LAS
 SG_ RLR_ElkOBJ1_Height : 18|9@0+ (0.01,0) [0|5.11] "m"  LAS
 SG_ RLR_ElkOBJ1_Width : 13|11@0+ (0.01,0) [0|12] "m"  LAS
 SG_ RLR_ElkOBJ1_Type : 0|3@0+ (1,0) [0|7] ""  LAS
 SG_ RLR_ElkOBJ1_Track_ID : 7|7@0+ (1,0) [0|127] ""  LAS

BO_ 739 GW_2E3: 64 GW
 SG_ RLR_CRCCheck_2E3 : 503|16@0+ (1,0) [0|65535] ""  LAS
 SG_ RLR_RollingCounter_2E3 : 491|4@0+ (1,0) [0|15] ""  LAS
 SG_ RLR_ElkOBJ4_Measured : 313|2@0+ (1,0) [0|3] ""  LAS
 SG_ RLR_ElkOBJ4_ExistProb : 319|6@0+ (2,0) [0|100] "%"  LAS
 SG_ RLR_ElkOBJ4_Location : 305|2@0+ (1,0) [0|3] ""  LAS
 SG_ RLR_ElkOBJ4_RelAx : 298|9@0+ (0.0625,-16) [-16|15.9375] "m/s2"  LAS
 SG_ RLR_ElkOBJ4_RelAy : 292|10@0+ (0.03125,-16) [-16|15.9688] "m/s2"  LAS
 SG_ RLR_ElkOBJ4_RelVx : 272|12@0+ (0.0625,-128) [-128|127.938] "m/s"  LAS
 SG_ RLR_ElkOBJ4_RelVy : 266|10@0+ (0.125,-64) [-64|63.875] "m/s"  LAS
 SG_ RLR_ElkOBJ4_Dx : 263|13@0+ (0.0625,-256) [-256|255.938] "m"  LAS
 SG_ RLR_ElkOBJ4_RefPointLoc : 251|3@0+ (1,0) [0|7] ""  LAS
 SG_ RLR_ElkOBJ4_Dy : 246|11@0+ (0.125,-128) [-128|127.875] "m"  LAS
 SG_ RLR_ElkOBJ4_HeadingAngle : 224|10@0+ (0.01,-3.14) [-3.14|3.14] "rad"  LAS
 SG_ RLR_ElkOBJ4_Length : 217|9@0+ (0.05,0) [0|25.5] "m"  LAS
 SG_ RLR_ElkOBJ4_Height : 210|9@0+ (0.01,0) [0|5.11] "m"  LAS
 SG_ RLR_ElkOBJ4_Width : 205|11@0+ (0.01,0) [0|12] "m"  LAS
 SG_ RLR_ElkOBJ4_Type : 192|3@0+ (1,0) [0|7] ""  LAS
 SG_ RLR_ElkOBJ4_Track_ID : 199|7@0+ (1,0) [0|127] ""  LAS
 SG_ RLR_ElkOBJ4_RefPointDx : 168|13@0+ (0.0625,-256) [-256|255.938] "m"  LAS
 SG_ RLR_ElkOBJ4_RefPointDy : 163|11@0+ (0.125,-128) [-128|127.875] "m"  LAS
 SG_ RLR_ElkOBJ4_ObstacleProb : 153|6@0+ (2,0) [0|100] "%"  LAS
 SG_ RLR_ElkOBJ3_RefPointDx : 150|13@0+ (0.0625,-256) [-256|255.938] "m"  LAS
 SG_ RLR_ElkOBJ3_RefPointDy : 129|11@0+ (0.125,-128) [-128|127.875] "m"  LAS
 SG_ RLR_ElkOBJ3_ObstacleProb : 135|6@0+ (2,0) [0|100] "%"  LAS
 SG_ RLR_ElkOBJ3_Measured : 121|2@0+ (1,0) [0|3] ""  LAS
 SG_ RLR_ElkOBJ3_ExistProb : 127|6@0+ (2,0) [0|100] "%"  LAS
 SG_ RLR_ElkOBJ3_Location : 113|2@0+ (1,0) [0|3] ""  LAS
 SG_ RLR_ElkOBJ3_RelAx : 106|9@0+ (0.0625,-16) [-16|15.9375] "m/s2"  LAS
 SG_ RLR_ElkOBJ3_RelAy : 100|10@0+ (0.03125,-16) [-16|15.9688] "m/s2"  LAS
 SG_ RLR_ElkOBJ3_RelVx : 80|12@0+ (0.0625,-128) [-128|127.938] "m/s"  LAS
 SG_ RLR_ElkOBJ3_RelVy : 74|10@0+ (0.125,-64) [-64|63.875] "m/s"  LAS
 SG_ RLR_ElkOBJ3_Dx : 71|13@0+ (0.0625,-256) [-256|255.938] "m"  LAS
 SG_ RLR_ElkOBJ3_RefPointLoc : 59|3@0+ (1,0) [0|7] ""  LAS
 SG_ RLR_ElkOBJ3_Dy : 54|11@0+ (0.125,-128) [-128|127.875] "m"  LAS
 SG_ RLR_ElkOBJ3_HeadingAngle : 32|10@0+ (0.01,-3.14) [-3.14|3.14] "rad"  LAS
 SG_ RLR_ElkOBJ3_Length : 25|9@0+ (0.05,0) [0|25.5] "m"  LAS
 SG_ RLR_ElkOBJ3_Height : 18|9@0+ (0.01,0) [0|5.11] "m"  LAS
 SG_ RLR_ElkOBJ3_Width : 13|11@0+ (0.01,0) [0|12] "m"  LAS
 SG_ RLR_ElkOBJ3_Type : 0|3@0+ (1,0) [0|7] ""  LAS
 SG_ RLR_ElkOBJ3_Track_ID : 7|7@0+ (1,0) [0|127] ""  LAS

BO_ 713 GW_2C9: 8 GW
 SG_ HU_Novice_Response : 36|2@0+ (1,0) [0|3] ""  APA
 SG_ HU_InterfaceChangeSingnal : 39|3@0+ (1,0) [0|7] ""  APA
 SG_ HU_Ylevel : 23|16@0+ (1,0) [0|1920] ""  APA,mADC
 SG_ HU_Xlevel : 7|16@0+ (1,0) [0|1920] ""  APA,mADC

BO_ 1889 GW_761: 64 GW
 SG_ Diagnose_message761 : 0|1@0+ (1,0) [1|1] ""  APA

BO_ 1405 GW_57D: 8 GW
 SG_ HU_APAOnOff : 1|2@0+ (1,0) [0|3] ""  APA

BO_ 1304 GW_518: 8 GW
 SG_ BCM_CarMode : 11|2@0+ (1,0) [0|3] ""  ACC,LAS,APA,FC

BO_ 686 GW_2AE: 8 GW
 SG_ LCDAL_SystemStatus : 6|3@0+ (1,0) [0|7] ""  LAS,FC

BO_ 985 LAS_3D9: 64 LAS
 SG_ ACC_ObsTarget10ID : 306|5@0+ (1,0) [0|31] ""  FC,GW
 SG_ ACC_ObsTarget10Type : 309|3@0+ (1,0) [0|7] ""  FC,GW
 SG_ ACC_ObsTarget10LatRange : 303|10@0+ (0.1,-50) [-50|50] "m"  FC,GW
 SG_ ACC_ObsTarget10LngRange : 282|11@0+ (0.1,-20) [-20|120] "m"  FC,GW
 SG_ ACC_ObsTarget9ID : 287|5@0+ (1,0) [0|31] ""  FC,GW
 SG_ ACC_ObsTarget9Type : 274|3@0+ (1,0) [0|7] ""  FC,GW
 SG_ ACC_ObsTarget9LatRange : 268|10@0+ (0.1,-50) [-50|50] "m"  FC,GW
 SG_ ACC_ObsTarget9LngRange : 263|11@0+ (0.1,-20) [-20|120] "m"  FC,GW
 SG_ ACC_ObsTarget8ID : 242|5@0+ (1,0) [0|31] ""  FC,GW
 SG_ ACC_ObsTarget8Type : 245|3@0+ (1,0) [0|7] ""  FC,GW
 SG_ ACC_ObsTarget8LatRange : 239|10@0+ (0.1,-50) [-50|50] "m"  FC,GW
 SG_ ACC_ObsTarget8LngRange : 218|11@0+ (0.1,-20) [-20|120] "m"  FC,GW
 SG_ ACC_ObsTarget7ID : 223|5@0+ (1,0) [0|31] ""  FC,GW
 SG_ ACC_ObsTarget7Type : 210|3@0+ (1,0) [0|7] ""  FC,GW
 SG_ ACC_ObsTarget7LatRange : 204|10@0+ (0.1,-50) [-50|50] "m"  FC,GW
 SG_ ACC_ObsTarget7LngRange : 199|11@0+ (0.1,-20) [-20|120] "m"  FC,GW
 SG_ ACC_ObsTarget6ID : 178|5@0+ (1,0) [0|31] ""  FC,GW
 SG_ ACC_ObsTarget6Type : 181|3@0+ (1,0) [0|7] ""  FC,GW
 SG_ ACC_ObsTarget6LatRange : 175|10@0+ (0.1,-50) [-50|50] "m"  FC,GW
 SG_ ACC_ObsTarget6LngRange : 154|11@0+ (0.1,-20) [-20|120] "m"  FC,GW
 SG_ ACC_ObsTarget5ID : 159|5@0+ (1,0) [0|31] ""  FC,GW
 SG_ ACC_ObsTarget5Type : 146|3@0+ (1,0) [0|7] ""  FC,GW
 SG_ ACC_ObsTarget5LatRange : 140|10@0+ (0.1,-50) [-50|50] "m"  FC,GW
 SG_ ACC_ObsTarget5LngRange : 135|11@0+ (0.1,-20) [-20|120] "m"  FC,GW
 SG_ ACC_ObsTarget4ID : 114|5@0+ (1,0) [0|31] ""  FC,GW
 SG_ ACC_ObsTarget4Type : 117|3@0+ (1,0) [0|7] ""  FC,GW
 SG_ ACC_ObsTarget4LatRange : 111|10@0+ (0.1,-50) [-50|50] "m"  FC,GW
 SG_ ACC_ObsTarget4LngRange : 90|11@0+ (0.1,-20) [-20|120] "m"  FC,GW
 SG_ ACC_ObsTarget3ID : 95|5@0+ (1,0) [0|31] ""  FC,GW
 SG_ ACC_ObsTarget3Type : 82|3@0+ (1,0) [0|7] ""  FC,GW
 SG_ ACC_ObsTarget3LatRange : 76|10@0+ (0.1,-50) [-50|50] "m"  FC,GW
 SG_ ACC_ObsTarget3LngRange : 71|11@0+ (0.1,-20) [-20|120] "m"  FC,GW
 SG_ ACC_ObsTarget2ID : 50|5@0+ (1,0) [0|31] ""  FC,GW
 SG_ ACC_ObsTarget2Type : 53|3@0+ (1,0) [0|7] ""  FC,GW
 SG_ ACC_ObsTarget2LatRange : 47|10@0+ (0.1,-50) [-50|50] "m"  FC,GW
 SG_ ACC_ObsTarget2LngRange : 26|11@0+ (0.1,-20) [-20|120] "m"  FC,GW
 SG_ ACC_ObsTarget1ID : 31|5@0+ (1,0) [0|31] ""  FC,GW
 SG_ ACC_ObsTarget1Type : 18|3@0+ (1,0) [0|7] ""  FC,GW
 SG_ ACC_ObsTarget1LatRange : 12|10@0+ (0.1,-50) [-50|50] "m"  FC,GW
 SG_ ACC_ObsTarget1LngRange : 7|11@0+ (0.1,-20) [-20|120] "m"  FC,GW

BO_ 987 LAS_3DB: 64 LAS
 SG_ ACC_ObsTarget20ID : 306|5@0+ (1,0) [0|31] ""  FC,GW
 SG_ ACC_ObsTarget20Type : 309|3@0+ (1,0) [0|7] ""  FC,GW
 SG_ ACC_ObsTarget20LatRange : 303|10@0+ (0.1,-50) [-50|50] "m"  FC,GW
 SG_ ACC_ObsTarget20LngRange : 282|11@0+ (0.1,-20) [-20|120] "m"  FC,GW
 SG_ ACC_ObsTarget19ID : 287|5@0+ (1,0) [0|31] ""  FC,GW
 SG_ ACC_ObsTarget19Type : 274|3@0+ (1,0) [0|7] ""  FC,GW
 SG_ ACC_ObsTarget19LatRange : 268|10@0+ (0.1,-50) [-50|50] "m"  FC,GW
 SG_ ACC_ObsTarget19LngRange : 263|11@0+ (0.1,-20) [-20|120] "m"  FC,GW
 SG_ ACC_ObsTarget18ID : 242|5@0+ (1,0) [0|31] ""  FC,GW
 SG_ ACC_ObsTarget18Type : 245|3@0+ (1,0) [0|7] ""  FC,GW
 SG_ ACC_ObsTarget18LatRange : 239|10@0+ (0.1,-50) [-50|50] "m"  FC,GW
 SG_ ACC_ObsTarget18LngRange : 218|11@0+ (0.1,-20) [-20|120] "m"  FC,GW
 SG_ ACC_ObsTarget17ID : 223|5@0+ (1,0) [0|31] ""  FC,GW
 SG_ ACC_ObsTarget17Type : 210|3@0+ (1,0) [0|7] ""  FC,GW
 SG_ ACC_ObsTarget17LatRange : 204|10@0+ (0.1,-50) [-50|50] "m"  FC,GW
 SG_ ACC_ObsTarget17LngRange : 199|11@0+ (0.1,-20) [-20|120] "m"  FC,GW
 SG_ ACC_ObsTarget16ID : 178|5@0+ (1,0) [0|31] ""  FC,GW
 SG_ ACC_ObsTarget16Type : 181|3@0+ (1,0) [0|7] ""  FC,GW
 SG_ ACC_ObsTarget16LatRange : 175|10@0+ (0.1,-50) [-50|50] "m"  FC,GW
 SG_ ACC_ObsTarget16LngRange : 154|11@0+ (0.1,-20) [-20|120] "m"  FC,GW
 SG_ ACC_ObsTarget15ID : 159|5@0+ (1,0) [0|31] ""  FC,GW
 SG_ ACC_ObsTarget15Type : 146|3@0+ (1,0) [0|7] ""  FC,GW
 SG_ ACC_ObsTarget15LatRange : 140|10@0+ (0.1,-50) [-50|50] "m"  FC,GW
 SG_ ACC_ObsTarget15LngRange : 135|11@0+ (0.1,-20) [-20|120] "m"  FC,GW
 SG_ ACC_ObsTarget14ID : 114|5@0+ (1,0) [0|31] ""  FC,GW
 SG_ ACC_ObsTarget14Type : 117|3@0+ (1,0) [0|7] ""  FC,GW
 SG_ ACC_ObsTarget14LatRange : 111|10@0+ (0.1,-50) [-50|50] "m"  FC,GW
 SG_ ACC_ObsTarget14LngRange : 90|11@0+ (0.1,-20) [-20|120] "m"  FC,GW
 SG_ ACC_ObsTarget13ID : 95|5@0+ (1,0) [0|31] ""  FC,GW
 SG_ ACC_ObsTarget13Type : 82|3@0+ (1,0) [0|7] ""  FC,GW
 SG_ ACC_ObsTarget13LatRange : 76|10@0+ (0.1,-50) [-50|50] "m"  FC,GW
 SG_ ACC_ObsTarget13LngRange : 71|11@0+ (0.1,-20) [-20|120] "m"  FC,GW
 SG_ ACC_ObsTarget12ID : 50|5@0+ (1,0) [0|31] ""  FC,GW
 SG_ ACC_ObsTarget12Type : 53|3@0+ (1,0) [0|7] ""  FC,GW
 SG_ ACC_ObsTarget12LatRange : 47|10@0+ (0.1,-50) [-50|50] "m"  FC,GW
 SG_ ACC_ObsTarget12LngRange : 26|11@0+ (0.1,-20) [-20|120] "m"  FC,GW
 SG_ ACC_ObsTarget11ID : 31|5@0+ (1,0) [0|31] ""  FC,GW
 SG_ ACC_ObsTarget11Type : 18|3@0+ (1,0) [0|7] ""  FC,GW
 SG_ ACC_ObsTarget11LatRange : 12|10@0+ (0.1,-50) [-50|50] "m"  FC,GW
 SG_ ACC_ObsTarget11LngRange : 7|11@0+ (0.1,-20) [-20|120] "m"  FC,GW

BO_ 881 GW_371: 8 GW
 SG_ PCU_DrvMod2 : 31|3@0+ (1,0) [0|7] ""  ACC,LAS,mADC
 SG_ PCU_SpecialModeSetFB : 25|3@0+ (1,0) [0|7] ""  ACC,LAS,FC,APA

BO_ 796 GW_31C: 8 GW
 SG_ PCU_VcuRdySts : 16|1@0+ (1,0) [0|1] ""  APA,ACC,LAS,mADC
 SG_ PCU_PowerOutputSts : 19|3@0+ (1,0) [0|7] ""  ACC,LAS

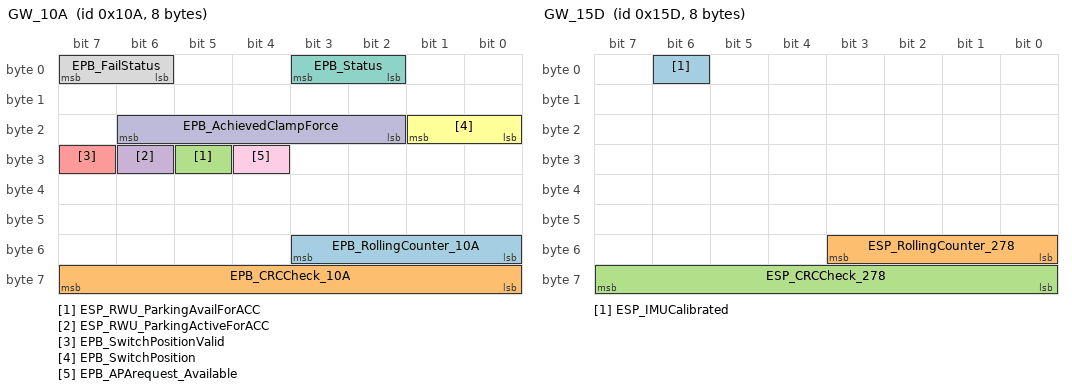
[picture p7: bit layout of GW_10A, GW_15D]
BO_ 266 GW_10A: 8 GW
 SG_ EPB_RollingCounter_10A : 51|4@0+ (1,0) [0|15] ""  mADC,ACC,APA
 SG_ EPB_CRCCheck_10A : 63|8@0+ (1,0) [0|255] ""  mADC,ACC,APA
 SG_ ESP_RWU_ParkingAvailForACC : 29|1@0+ (1,0) [0|1] "" Vector__XXX
 SG_ ESP_RWU_ParkingActiveForACC : 30|1@0+ (1,0) [0|1] "" Vector__XXX
 SG_ EPB_SwitchPositionValid : 31|1@0+ (1,0) [0|1] ""  ACC,LAS,APA,mADC
 SG_ EPB_SwitchPosition : 17|2@0+ (1,0) [0|3] ""  ACC,LAS,APA,mADC
 SG_ EPB_Status : 3|2@0+ (1,0) [0|3] ""  ACC,LAS,APA,mADC
 SG_ EPB_FailStatus : 7|2@0+ (1,0) [0|3] ""  ACC,LAS,APA,mADC
 SG_ EPB_APArequest_Available : 28|1@0+ (1,0) [0|1] ""  APA,mADC
 SG_ EPB_AchievedClampForce : 22|5@0+ (1,0) [0|31] "KN"  ACC,LAS,APA,mADC

BO_ 1024 BDC_400: 8 BDC
 SG_ NM_message400 : 0|1@0+ (1,0) [1|1] ""  GW

BO_ 1107 ACC_453: 8 ACC
 SG_ NM_message453 : 0|1@0+ (1,0) [1|1] ""  GW,BDC

BO_ 2015 GW_7DF: 8 GW
 SG_ Diagnose_message7DF : 0|1@0+ (1,0) [1|1] "" Vector__XXX

BO_ 349 GW_15D: 8 GW
 SG_ ESP_IMUCalibrated : 6|1@0+ (1,0) [0|1] ""  mADC
 SG_ ESP_RollingCounter_278 : 51|4@0+ (1,0) [0|15] ""  mADC
 SG_ ESP_CRCCheck_278 : 63|8@0+ (1,0) [0|255] ""  mADC

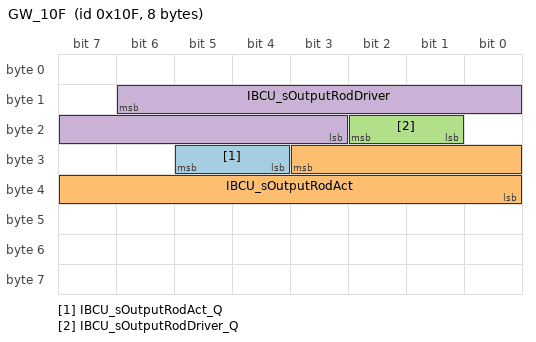
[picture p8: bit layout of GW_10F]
BO_ 271 GW_10F: 8 GW
 SG_ IBCU_sOutputRodAct_Q : 29|2@0+ (1,0) [0|3] ""  ACC,LAS,FC,mADC
 SG_ IBCU_sOutputRodAct : 27|12@0+ (0.015625,-5) [-5|47] "mm"  ACC,LAS,FC,mADC
 SG_ IBCU_sOutputRodDriver_Q : 18|2@0+ (1,0) [0|2] ""  ACC,LAS,FC
 SG_ IBCU_sOutputRodDriver : 14|12@0+ (0.015625,-5) [-5|47] "mm"  ACC,LAS,FC

BO_ 810 GW_32A: 8 GW
 SG_ TRM_ConnectSts : 52|1@0+ (1,0) [0|1] ""  ACC,LAS

BO_ 958 GW_3BE: 8 GW
 SG_ ATS_CurrentDrivingMode : 34|3@0+ (1,0) [0|6] ""  ACC,LAS,mADC

BO_ 890 GW_37A: 64 GW
 SG_ VMC_RollingCounter_37A : 491|4@0+ (1,0) [0|15] ""  ACC,LAS,mADC
 SG_ VMC_CRCCheck_37A : 503|16@0+ (1,0) [0|65535] ""  ACC,LAS,mADC
 SG_ VMC_CtrlLevelRRValid : 115|1@0+ (1,0) [0|1] ""  ACC,LAS,mADC
 SG_ VMC_CtrlLevelRLyValid : 114|1@0+ (1,0) [0|1] ""  ACC,LAS,mADC
 SG_ VMC_CtrlLevelFRValid : 111|1@0+ (1,0) [0|1] ""  ACC,LAS,mADC
 SG_ VMC_CtrlLevelFLValid : 110|1@0+ (1,0) [0|1] ""  ACC,LAS,mADC
 SG_ VMC_LvlTarRR : 183|16@0+ (0.01,-327.67) [-327.67|327.67] ""  ACC,LAS,mADC
 SG_ VMC_LvlTarRL : 167|16@0+ (0.01,-327.67) [-327.67|327.67] ""  ACC,LAS,mADC
 SG_ VMC_LvlTarFR : 247|16@0+ (0.01,-327.67) [-327.67|327.67] ""  ACC,LAS,mADC
 SG_ VMC_LvlTarFL : 231|16@0+ (0.01,-327.67) [-327.67|327.67] ""  ACC,LAS,mADC
 SG_ VMC_EcasModeRELSts : 106|2@0+ (1,0) [0|3] ""  ACC,LAS,mADC
 SG_ VMC_EcasModeFRTSts : 108|2@0+ (1,0) [0|3] ""  ACC,LAS,mADC
 SG_ VMC_EcasModeCHASts : 9|2@0+ (1,0) [0|3] ""  ACC,LAS,mADC
 SG_ VMC_CtrlLevelRR : 215|16@0+ (0.01,-327.67) [-327.67|327.67] "mm"  ACC,LAS,mADC
 SG_ VMC_CtrlLevelRL : 199|16@0+ (0.01,-327.67) [-327.67|327.67] "mm"  ACC,LAS,mADC
 SG_ VMC_CtrlLevelFR : 151|16@0+ (0.01,-327.67) [-327.67|327.67] "mm"  ACC,LAS,mADC
 SG_ VMC_CtrlLevelFL : 135|16@0+ (0.01,-327.67) [-327.67|327.67] "mm"  ACC,LAS,mADC
 SG_ VMC_EcasModeVal : 15|1@0+ (1,0) [0|1] ""  ACC,LAS,mADC
 SG_ VMC_EcdcMode : 3|3@0+ (1,0) [0|4] ""  ACC,LAS,mADC
 SG_ VMC_EcasMode : 7|4@0+ (1,0) [0|9] ""  ACC,LAS,mADC

CM_ BO_ 652 "GW自发MFS_LIN_2 ";
CM_ SG_ 652 GW_MFS_CRCCheck_28C "GW对LIN的CRC重新计算并发出 ";
CM_ BO_ 817 " ";
CM_ SG_ 817 TCU_TransTempWarning "Not used for A phase ";
CM_ SG_ 817 TCU_TransFluidTemp "Transmission sump oil temperature
PEU uses it for rotor temperature estimation ";
CM_ SG_ 817 TCU_TransFaultLevel "1、Normal= transmission works will;Fault level1(just store DTC)=Transmission some functions are fault but don't need to inform the driver;Fault level2(store DTC&warning)=Transmission some functions are fault and it should inform the driver;Fault level3(Limphome)=Transmission some functions are fault and will limit the torque;Fault level4(No DCT Shaft)= Transmission some functions are fault and it will lead to freeze shaft; Fault level5(Drive open)；Transmission fully broken and it will lead clutchs fully open.
2、P2特有
3、APA配置接收方无BDC ";
CM_ SG_ 817 TCU_RotorAcutalCoolingFlow "0x0-0x32=0-5；0x33-0x3E=Reserved；0x3F=Invalid. This signal is for PEU to estimate rotar temperater. ";
CM_ SG_ 817 TCU_PowerplantStatusIPReq " ";
CM_ SG_ 817 TCU_ParkSelectIPReq "TCU communication to IP when driver does not follow Park Engagement procedure  correctly ";
CM_ SG_ 817 TCU_ParkRelMPosnIPReq "TCU communication to IP when driver is unable to get drive , when Park is engaged in M Gate ";
CM_ SG_ 817 TCU_ParkRelAPosnIPReq "TCU communication to IP when driver does not follow release park procedure  correctly when Park is engaged in Auto position ";
CM_ SG_ 817 TCU_K0ClutchExitOilTemp "1、Used for rotor temperature estimation in PEU. This signal is for PEU to estimate rotar temperater.
2、P2特有 ";
CM_ SG_ 817 TCU_GearForDisplay "This difinition comes from platform team ";
CM_ SG_ 817 TCU_FailureLamp "Indicates whether there is a failure or not ";
CM_ SG_ 817 TCU_ESLFaultIPReq " ";
CM_ SG_ 817 TCU_CRCCheck_338 "CRCCheck_SAE_J1850_2001,multinomial is X8+X4+X3+X2+1 ";
CM_ SG_ 817 TCU_CoolantFanRequest "1、TCU sends this information when transmission sump oil temperature is overheated - 0x0-0x64=0%-100%；0x65-0x7E= no use；0x7F=Invalid；
2、P2特有 ";
CM_ BO_ 431 " ";
CM_ SG_ 431 TCU_TipSwitchSignal "Manual mode switch signal ";
CM_ SG_ 431 TCU_THOState " ";
CM_ SG_ 431 TCU_STLKfailure "PEPS need this signal to control engine start. When gear box in P/N, TCU contrl the pin to LSD. If detected not to low in P/N or to low in D/R/S/M ";
CM_ SG_ 431 TCU_ShiftPostionValid "APA配置接收方无BDC ";
CM_ SG_ 431 TCU_InputShaftSpeed "PCU uses it for regen, engine start while moving, etc.
PEU uses it for correlation check of resolver ";
CM_ SG_ 431 TCU_GearShiftPosition "TCU receives driver demands gear from ESL and make decisition of actual drive mode based on current vehicle/transmission status.
PCU receives this signals to understand actual drive mode and estimate target gear ";
CM_ SG_ 431 TCU_GearRatio " ";
CM_ SG_ 431 TCU_CRCCheck_1A8 "CRCCheck_SAE_J1850_2001,multinomial is X8+X4+X3+X2+1 ";
CM_ SG_ 431 TCU_ActualPreselectGear "Used for preselect gear estimation ";
CM_ SG_ 431 TCU_ActualDrivingGearValid "APA配置接收方无BDC ";
CM_ SG_ 431 TCU_ActualDrivingGear "RMU法规要求
Message relaying what the current engaged gear is (On DCT this will also be the gear on the shaft with the engaged clutch). ";
CM_ BO_ 800 "GW自发 ";
CM_ SG_ 800 GW_DCANDiagSts " ";
CM_ SG_ 800 GW_OTAmode_Chks "与GW_OTAmode分配到一个ID的相邻字节 ";
CM_ SG_ 800 GW_OTAmode_Cntr "与GW_OTAmode分配到1个字节 ";
CM_ SG_ 800 GW_OTAmode "与GW_OTAmode_Cntr分配到1个字节 ";
CM_ SG_ 800 GW_ResetReq " ";
CM_ BO_ 922 " ";
CM_ SG_ 922 LAS_CRCCheck_3C0 "
 ";
CM_ SG_ 922 LAS_RollingCounter_3C0 "rolling counter ";
CM_ SG_ 922 LAS_CRCCheck_3D4 "
 ";
CM_ SG_ 922 LAS_RollingCounter_3D4 "rolling counter ";
CM_ SG_ 922 LAS_CRCCheck_332 "
 ";
CM_ SG_ 922 LAS_RollingCounter_332 "rolling counter ";
CM_ SG_ 922 LAS_HMALightDistribution "GW报文转发 ";
CM_ SG_ 922 LAS_HMAStatus "GW报文转发 ";
CM_ SG_ 922 LAS_TSRHostSpdLimitUnits "GW报文转发 ";
CM_ SG_ 922 LAS_TSRStatus "GW报文转发 ";
CM_ SG_ 922 LAS_FrontCameraCalibrationStatus "有LAS时由LAS发送，其余由APA或AVM发送 ";
CM_ SG_ 922 LAS_FrontCameraFailureStatus "有LAS时由LAS发送，其余由APA或AVM发送 ";
CM_ SG_ 922 LAS_CRCCheck_37D " ";
CM_ SG_ 922 LAS_RollingCounter_37D "rolling counter ";
CM_ BO_ 784 "源端INFO_AMP_30E,1 ";
CM_ BO_ 1000 " ";
CM_ SG_ 1000 BCM_SOF_t_STATE "GW报文转发 ";
CM_ SG_ 1000 BCM_SOF_V2_STATE "GW报文转发 ";
CM_ SG_ 1000 BCM_SOF_V1_STATE "GW报文转发 ";
CM_ SG_ 1000 BCM_SOF_Q_STATE "GW报文转发 ";
CM_ SG_ 1000 BCM_SOC_STATE "GW报文转发 ";
CM_ SG_ 1000 BCM_SOF_t "GW报文转发 ";
CM_ SG_ 1000 BCM_SOF_V2 "GW报文转发 ";
CM_ SG_ 1000 BCM_SOF_V1 "GW报文转发 ";
CM_ SG_ 1000 BCM_SOF_Q "GW报文转发 ";
CM_ SG_ 1000 BCM_SOC "GW报文转发 ";
CM_ BO_ 999 " ";
CM_ SG_ 999 BCM_Resp_Error "GW报文转发 ";
CM_ SG_ 999 BCM_FLAG_INCONSISTENCY "GW报文转发 ";
CM_ SG_ 999 BCM_Status_Current "GW报文转发 ";
CM_ SG_ 999 BCM_Status_Voltage "GW报文转发 ";
CM_ SG_ 999 BCM_Status_Temp "GW报文转发 ";
CM_ SG_ 999 BCM_ERROR_Calib "GW报文转发 ";
CM_ SG_ 999 BCM_ERROR_IDENT "GW报文转发 ";
CM_ SG_ 999 BCM_IBATT_QUIESCENT "GW报文转发 ";
CM_ SG_ 999 BCM_T_BATT "GW报文转发 ";
CM_ SG_ 999 BCM_I_BATT "GW报文转发 ";
CM_ SG_ 999 BCM_U_BATT "GW报文转发 ";
CM_ SG_ 999 BCM_I_RANGE "GW报文转发 ";
CM_ BO_ 906 "GW自发 ";
CM_ BO_ 585 " ";
CM_ BO_ 610 " ";
CM_ BO_ 820 " ";
CM_ SG_ 820 DSM_RollingCounter_334 " ";
CM_ SG_ 820 DSM_CRCCheck_334 " ";
CM_ SG_ 820 DSM_RightMirrorUpDownSts " ";
CM_ SG_ 820 DSM_RightMirrorLeftRightSts " ";
CM_ SG_ 820 DSM_LeftMirrorLeftRightSts " ";
CM_ SG_ 820 DSM_LeftMirrorUpDownSts " ";
CM_ BO_ 917 " ";
CM_ SG_ 917 TBOX_EseUpdataHUWakeUpReq "GW报文转发 ";
CM_ SG_ 917 TBOX_RemoteInstallReq "GW报文转发 ";
CM_ SG_ 917 TBOX_RemotePaVentilatieReq "GW报文转发 ";
CM_ SG_ 917 TBOX_RemoteDrVentilatieReq "GW报文转发 ";
CM_ SG_ 917 TBOX_BCallStatus "GW报文转发 ";
CM_ SG_ 917 TBOX_AudioRequest "GW报文转发 ";
CM_ SG_ 917 TBOX_ChangePartStatus "GW报文转发 4GTBOX不发送 ";
CM_ SG_ 917 TBOX_CallStatus "GW报文转发 ";
CM_ SG_ 917 TBOX_RemoteAirCleanReq "GW报文转发 ";
CM_ SG_ 917 TBOX_RemoteAirQualityInquire "GW报文转发 ";
CM_ SG_ 917 TBOX_RemoteSteerWheelHotReq "GW报文转发 ";
CM_ SG_ 917 TBOX_RemoteDriverSeatHotReq "GW报文转发 ";
CM_ SG_ 917 TBOX_RemotePassangerSeatHotReq "GW报文转发 ";
CM_ SG_ 917 TBOX_SearchCarReq "GW报文转发 ";
CM_ SG_ 917 TBOX_RmoteTrunk "GW报文转发 ";
CM_ SG_ 917 TBOX_RmoteRoof "GW报文转发 ";
CM_ SG_ 917 TBOX_RemoteACStartupReq "GW报文转发 ";
CM_ SG_ 917 TBOX_VehicleStatusDemandReq "GW报文转发
4GTBOX不发送 ";
CM_ SG_ 917 TBOX_RemoteStartRunTime "GW报文转发 ";
CM_ SG_ 917 TBOX_VINMatchStatus "GW报文转发 ";
CM_ SG_ 917 TBOX_VINReq "GW报文转发 ";
CM_ SG_ 917 TBOX_ACTempValueReq "GW报文转发 ";
CM_ SG_ 917 TBOX_CarRemind "GW报文转发（用于2GTBOX） ";
CM_ SG_ 917 TBOX_RemoteEngineStartupReq "GW报文转发 ";
CM_ SG_ 917 TBOX_EngineStartupInhibit "GW报文转发 ";
CM_ SG_ 917 TBOX_LockCommand "GW报文转发 ";
CM_ SG_ 917 TBox_ResetFlag_395 " ";
CM_ SG_ 917 TBox_MesssageCounter_395 " ";
CM_ SG_ 917 TBox_Authenticator_395 " ";
CM_ SG_ 917 TBOX_APARemoteDriveReq " ";
CM_ SG_ 917 TBOX_HZPFunctionReq " ";
CM_ SG_ 917 TBOX_HZPControlEnable " ";
CM_ SG_ 917 TBOX_SignalStrength " ";
CM_ SG_ 917 TBOX_SignalType " ";
CM_ SG_ 917 TBOX_APA_SignalDelay " ";
CM_ SG_ 917 TBOX_APA_VideoDelay " ";
CM_ SG_ 917 TBOX_AVM_DisplayForm " ";
CM_ SG_ 917 TBOX_TurnRight " ";
CM_ SG_ 917 TBOX_TurnLeft " ";
CM_ SG_ 917 TBOX_Verticalforward " ";
CM_ SG_ 917 TBOX_Verticalbackward " ";
CM_ SG_ 917 TBOX_APAPOCModeSelect " ";
CM_ SG_ 917 TBOX_APAFuctionSelection " ";
CM_ SG_ 917 TBOX_APAManeuverSuspend " ";
CM_ SG_ 917 TBOX_APAManeuverStart " ";
CM_ SG_ 917 TBOX_APAManeuverCancel " ";
CM_ SG_ 917 TBOX_APAmoduleEnable " ";
CM_ SG_ 917 TBOX_RemoteDisReq "GW报文转发 ";
CM_ SG_ 917 TBOX_VehicleVedioDetectReq "GW报文转发 ";
CM_ SG_ 917 TBOX_RemoteDetectReq "GW报文转发 ";
CM_ BO_ 394 " ";
CM_ SG_ 394 TCU_APAShiftGearRequestEnable "APA配置接收方无BDC ";
CM_ SG_ 394 TCU_APAdriverInterruption "APA配置接收方无BDC ";
CM_ BO_ 586 " ";
CM_ SG_ 586 ESL_HALLStatus "GW报文转发 ";
CM_ SG_ 586 ESL_DriveModeFaultStatus "TCU接收为DCT专用
ACM接收为AT专用
原信号名称ESL_DriveModeStatus，CD569、S202DA使用 ";
CM_ SG_ 586 ESL_UnLockButtonFaultStatus "TCU接收为DCT专用
ACM接收为AT专用
原信号名称ESL_UnLockButtonStatus，CD569、S202DA使用 ";
CM_ SG_ 586 ESL_EPBButton_FaultStatus " ";
CM_ SG_ 586 ESL_UnLockButtonPositionStatus "TCU接收为DCT专用
ACM接收为AT专用
原信号名称ESL_UnLockButtonPosition，CD569、S202DA使用 ";
CM_ SG_ 586 ESL_EPBButton_PositionStatus " ";
CM_ SG_ 586 ESL_TcugearRef "根据TCU需求新增（HF140） ";
CM_ SG_ 586 ESL_CRCCheck_24A "ACM接收为AT专用 ";
CM_ SG_ 586 ESL_RollingCounter_24A "ACM接收为AT专用 ";
CM_ SG_ 586 ESL_DriveModeRequest "ACM接收为AT专用
原信号名称ESL_DriveModePosition，CD569、S202DA使用 ";
CM_ SG_ 586 ESL_DriverParkButtonFaultStatus "TCU接收为DCT专用
ACM接收为AT专用
原信号名称ESL_DriverParkButtonStatus，CD569、S202DA使用 ";
CM_ SG_ 586 ESL_DriverParkRequest "TCU接收为DCT专用
ACM接收为AT专用 ";
CM_ SG_ 586 ESL_ShiftLeverPositionrequest "ACM接收为AT专用
原信号名称ESL_ShiftLeverPositon，CD569、S202DA使用 ";
CM_ SG_ 586 ESL_ShiftLeverPositionFaultSts "TCU接收为DCT专用
ACM接收为AT专用
原信号名称ESL_ShiftLeverStatus，CD569、S202DA使用 ";
CM_ BO_ 604 "GW自发 ";
CM_ SG_ 604 GW_Authernticator_25C " ";
CM_ SG_ 604 GW_ResetCounter_25C " ";
CM_ SG_ 604 GW_TripCounter_25C " ";
CM_ BO_ 727 " ";
CM_ SG_ 727 HU_ScreenOperateStatus "GW报文转发 ";
CM_ SG_ 727 HU_3DHorAngleReq "GW报文转发 ";
CM_ BO_ 833 "源端HybridA_PCU_33B,1 ";
CM_ SG_ 833 PCU_PwrTqWhMinVld "ACC 主控则ACC接收，LAS 主控则LAS接收 ";
CM_ SG_ 833 PCU_PwrTqWhMinTotal "ACC 主控则ACC接收，LAS 主控则LAS接收 ";
CM_ SG_ 833 PCU_PwrTqWhMaxVld "ACC 主控则ACC接收，LAS 主控则LAS接收 ";
CM_ SG_ 833 PCU_PwrTqWhMaxTotal "ACC 主控则ACC接收，LAS 主控则LAS接收 ";
CM_ SG_ 833 PCU_AccPedShield "APA配置接收方无BDC ";
CM_ BO_ 982 " ";
CM_ SG_ 982 SLCM_RRWindowStatus "纹波防夹 ";
CM_ SG_ 982 SLCM_FRWindowStatus "纹波防夹 ";
CM_ BO_ 984 " ";
CM_ SG_ 984 SLCM_RLWinMotor "纹波防夹 ";
CM_ SG_ 984 SLCM_DriverWinMotor "纹波防夹 ";
CM_ SG_ 984 SLCM_FailStatus "纹波防夹 ";
CM_ SG_ 984 SLCM_RLWindowSwitch "纹波防夹 ";
CM_ SG_ 984 SLCM_DriverWindowSwitch "纹波防夹 ";
CM_ SG_ 984 SLCM_RLWindowAPActice "纹波防夹 ";
CM_ SG_ 984 SLCM_DriverWindowAPActice "纹波防夹 ";
CM_ SG_ 984 SLCM_RLWindowInitializedSts "纹波防夹 ";
CM_ SG_ 984 SLCM_DriverWindowInitializedSts "纹波防夹 ";
CM_ SG_ 984 SLCM_RLWindowStatus "纹波防夹 ";
CM_ SG_ 984 SLCM_DriverWindowStatus "纹波防夹 ";
CM_ BO_ 990 " ";
CM_ SG_ 990 DSM_RollingCounter_3DE " ";
CM_ SG_ 990 DSM_CRCCheck_3DE " ";
CM_ SG_ 990 DSM_DSMBackrestPositionSts " ";
CM_ SG_ 990 DSM_DSMVerticalPositionSts " ";
CM_ SG_ 990 DSM_DSMFrontEndPositionSts " ";
CM_ SG_ 990 DSM_DSMHorizontalPositionSts " ";
CM_ BO_ 1006 " ";
CM_ BO_ 1712 " ";
CM_ SG_ 1712 GW_APA_AuthenticationStatus "最大值是为转DBC使用 ";
CM_ BO_ 723 " ";
CM_ SG_ 723 ACC_CRCCheck_283 " ";
CM_ SG_ 723 ACC_RollingCounter_283 " ";
CM_ SG_ 723 ACC_AEBTargetLatRelSpeed_for_SRS "向左为正，向右为 ";
CM_ SG_ 723 ACC_AEBTargetLatRange_for_SRS "向左为正，向右为 ";
CM_ SG_ 723 ACC_CRCCheckr_282 " ";
CM_ SG_ 723 ACC_RollingCounter_282 " ";
CM_ SG_ 723 ACC_AEBTargetProb_for_SRS " ";
CM_ SG_ 723 ACC_AEBTargetType_for_SRS " ";
CM_ SG_ 723 ACC_AEBTargetTTC_for_SRS "碰撞时刻为0 ";
CM_ SG_ 723 ACC_AEBTargetRelSpeed_for_SRS "前方目标比本车快为正，前方目标比本车慢为负 ";
CM_ SG_ 723 ACC_AEBTargetLngRange_for_SRS "负数代表向后，正数代表向前，原点为前雷达波束发射 ";
CM_ SG_ 723 ACC_AEBActive_for_SRS " ";
CM_ SG_ 723 ACC_AEBStatus_for_SRS " ";
CM_ BO_ 769 " ";
CM_ BO_ 780 " ";
CM_ BO_ 738 " ";
CM_ BO_ 739 " ";
CM_ BO_ 713 " ";
CM_ SG_ 713 HU_Novice_Response " ";
CM_ SG_ 713 HU_InterfaceChangeSingnal "513(周期)和514(事件)，当前多数项目使用514(事件)报文。 ";
CM_ SG_ 713 HU_Ylevel "513(周期)和514(事件)，当前多数项目使用514(事件)报文。 ";
CM_ SG_ 713 HU_Xlevel "513(周期)和514(事件)，当前多数项目使用514(事件)报文。 ";
CM_ BO_ 1889 "CANFD诊断仪使用 ";
CM_ BO_ 1405 " ";
CM_ BO_ 1304 " ";
CM_ SG_ 1304 BCM_CarMode "无效值是为转DBC ";
CM_ BO_ 686 "源端ADASB_RLR/LCDAL_2AD,0 ";
CM_ SG_ 686 LCDAL_SystemStatus " ";
CM_ BO_ 985 " ";
CM_ SG_ 985 ACC_ObsTarget10ID "800W摄像头使用 ";
CM_ SG_ 985 ACC_ObsTarget10Type "800W摄像头使用 ";
CM_ SG_ 985 ACC_ObsTarget10LatRange "横向距离向左为负，向右为正
800W摄像头使用 ";
CM_ SG_ 985 ACC_ObsTarget10LngRange "纵向距离向前为正，向后为负
800W摄像头使用 ";
CM_ SG_ 985 ACC_ObsTarget9ID "800W摄像头使用 ";
CM_ SG_ 985 ACC_ObsTarget9Type "800W摄像头使用 ";
CM_ SG_ 985 ACC_ObsTarget9LatRange "横向距离向左为负，向右为正
800W摄像头使用 ";
CM_ SG_ 985 ACC_ObsTarget9LngRange "纵向距离向前为正，向后为负
800W摄像头使用 ";
CM_ SG_ 985 ACC_ObsTarget8ID "800W摄像头使用 ";
CM_ SG_ 985 ACC_ObsTarget8Type "800W摄像头使用 ";
CM_ SG_ 985 ACC_ObsTarget8LatRange "横向距离向左为负，向右为正
800W摄像头使用 ";
CM_ SG_ 985 ACC_ObsTarget8LngRange "纵向距离向前为正，向后为负
800W摄像头使用 ";
CM_ SG_ 985 ACC_ObsTarget7ID "800W摄像头使用 ";
CM_ SG_ 985 ACC_ObsTarget7Type "800W摄像头使用 ";
CM_ SG_ 985 ACC_ObsTarget7LatRange "横向距离向左为负，向右为正
800W摄像头使用 ";
CM_ SG_ 985 ACC_ObsTarget7LngRange "纵向距离向前为正，向后为负
800W摄像头使用 ";
CM_ SG_ 985 ACC_ObsTarget6ID "800W摄像头使用 ";
CM_ SG_ 985 ACC_ObsTarget6Type "800W摄像头使用 ";
CM_ SG_ 985 ACC_ObsTarget6LatRange "横向距离向左为负，向右为正
800W摄像头使用 ";
CM_ SG_ 985 ACC_ObsTarget6LngRange "纵向距离向前为正，向后为负
800W摄像头使用 ";
CM_ SG_ 985 ACC_ObsTarget5ID "800W摄像头使用 ";
CM_ SG_ 985 ACC_ObsTarget5Type "800W摄像头使用 ";
CM_ SG_ 985 ACC_ObsTarget5LatRange "横向距离向左为负，向右为正
800W摄像头使用 ";
CM_ SG_ 985 ACC_ObsTarget5LngRange "纵向距离向前为正，向后为负
800W摄像头使用 ";
CM_ SG_ 985 ACC_ObsTarget4ID "800W摄像头使用 ";
CM_ SG_ 985 ACC_ObsTarget4Type "800W摄像头使用 ";
CM_ SG_ 985 ACC_ObsTarget4LatRange "横向距离向左为负，向右为正
800W摄像头使用 ";
CM_ SG_ 985 ACC_ObsTarget4LngRange "纵向距离向前为正，向后为负
800W摄像头使用 ";
CM_ SG_ 985 ACC_ObsTarget3ID "800W摄像头使用 ";
CM_ SG_ 985 ACC_ObsTarget3Type "800W摄像头使用 ";
CM_ SG_ 985 ACC_ObsTarget3LatRange "横向距离向左为负，向右为正
800W摄像头使用 ";
CM_ SG_ 985 ACC_ObsTarget3LngRange "纵向距离向前为正，向后为负
800W摄像头使用 ";
CM_ SG_ 985 ACC_ObsTarget2ID "800W摄像头使用 ";
CM_ SG_ 985 ACC_ObsTarget2Type "800W摄像头使用 ";
CM_ SG_ 985 ACC_ObsTarget2LatRange "横向距离向左为负，向右为正
800W摄像头使用 ";
CM_ SG_ 985 ACC_ObsTarget2LngRange "纵向距离向前为正，向后为负
800W摄像头使用 ";
CM_ SG_ 985 ACC_ObsTarget1ID "800W摄像头使用 ";
CM_ SG_ 985 ACC_ObsTarget1Type "800W摄像头使用 ";
CM_ SG_ 985 ACC_ObsTarget1LatRange "横向距离向左为负，向右为正
800W摄像头使用 ";
CM_ SG_ 985 ACC_ObsTarget1LngRange "纵向距离向前为正，向后为负
800W摄像头使用 ";
CM_ BO_ 987 " ";
CM_ SG_ 987 ACC_ObsTarget20ID "800W摄像头使用 ";
CM_ SG_ 987 ACC_ObsTarget20Type "800W摄像头使用 ";
CM_ SG_ 987 ACC_ObsTarget20LatRange "横向距离向左为负，向右为正
800W摄像头使用 ";
CM_ SG_ 987 ACC_ObsTarget20LngRange "纵向距离向前为正，向后为负
800W摄像头使用 ";
CM_ SG_ 987 ACC_ObsTarget19ID "800W摄像头使用 ";
CM_ SG_ 987 ACC_ObsTarget19Type "800W摄像头使用 ";
CM_ SG_ 987 ACC_ObsTarget19LatRange "横向距离向左为负，向右为正
800W摄像头使用 ";
CM_ SG_ 987 ACC_ObsTarget19LngRange "纵向距离向前为正，向后为负
800W摄像头使用 ";
CM_ SG_ 987 ACC_ObsTarget18ID "800W摄像头使用 ";
CM_ SG_ 987 ACC_ObsTarget18Type "800W摄像头使用 ";
CM_ SG_ 987 ACC_ObsTarget18LatRange "横向距离向左为负，向右为正
800W摄像头使用 ";
CM_ SG_ 987 ACC_ObsTarget18LngRange "纵向距离向前为正，向后为负
800W摄像头使用 ";
CM_ SG_ 987 ACC_ObsTarget17ID "800W摄像头使用 ";
CM_ SG_ 987 ACC_ObsTarget17Type "800W摄像头使用 ";
CM_ SG_ 987 ACC_ObsTarget17LatRange "横向距离向左为负，向右为正
800W摄像头使用 ";
CM_ SG_ 987 ACC_ObsTarget17LngRange "纵向距离向前为正，向后为负
800W摄像头使用 ";
CM_ SG_ 987 ACC_ObsTarget16ID "800W摄像头使用 ";
CM_ SG_ 987 ACC_ObsTarget16Type "800W摄像头使用 ";
CM_ SG_ 987 ACC_ObsTarget16LatRange "横向距离向左为负，向右为正
800W摄像头使用 ";
CM_ SG_ 987 ACC_ObsTarget16LngRange "纵向距离向前为正，向后为负
800W摄像头使用 ";
CM_ SG_ 987 ACC_ObsTarget15ID "800W摄像头使用 ";
CM_ SG_ 987 ACC_ObsTarget15Type "800W摄像头使用 ";
CM_ SG_ 987 ACC_ObsTarget15LatRange "横向距离向左为负，向右为正
800W摄像头使用 ";
CM_ SG_ 987 ACC_ObsTarget15LngRange "纵向距离向前为正，向后为负
800W摄像头使用 ";
CM_ SG_ 987 ACC_ObsTarget14ID "800W摄像头使用 ";
CM_ SG_ 987 ACC_ObsTarget14Type "800W摄像头使用 ";
CM_ SG_ 987 ACC_ObsTarget14LatRange "横向距离向左为负，向右为正
800W摄像头使用 ";
CM_ SG_ 987 ACC_ObsTarget14LngRange "纵向距离向前为正，向后为负
800W摄像头使用 ";
CM_ SG_ 987 ACC_ObsTarget13ID "800W摄像头使用 ";
CM_ SG_ 987 ACC_ObsTarget13Type "800W摄像头使用 ";
CM_ SG_ 987 ACC_ObsTarget13LatRange "横向距离向左为负，向右为正
800W摄像头使用 ";
CM_ SG_ 987 ACC_ObsTarget13LngRange "纵向距离向前为正，向后为负
800W摄像头使用 ";
CM_ SG_ 987 ACC_ObsTarget12ID "800W摄像头使用 ";
CM_ SG_ 987 ACC_ObsTarget12Type "800W摄像头使用 ";
CM_ SG_ 987 ACC_ObsTarget12LatRange "横向距离向左为负，向右为正
800W摄像头使用 ";
CM_ SG_ 987 ACC_ObsTarget12LngRange "纵向距离向前为正，向后为负
800W摄像头使用 ";
CM_ SG_ 987 ACC_ObsTarget11ID "800W摄像头使用 ";
CM_ SG_ 987 ACC_ObsTarget11Type "800W摄像头使用 ";
CM_ SG_ 987 ACC_ObsTarget11LatRange "横向距离向左为负，向右为正
800W摄像头使用 ";
CM_ SG_ 987 ACC_ObsTarget11LngRange "纵向距离向前为正，向后为负
800W摄像头使用 ";
CM_ BO_ 881 " ";
CM_ BO_ 796 "源端HybridA_PCU/PDCU_3FC.6 ";
CM_ SG_ 796 PCU_VcuRdySts "APA配置接收方无BDC ";
CM_ BO_ 266 " ";
CM_ SG_ 266 EPB_RollingCounter_10A " ";
CM_ SG_ 266 EPB_CRCCheck_10A " ";
CM_ SG_ 266 ESP_RWU_ParkingAvailForACC " ";
CM_ SG_ 266 ESP_RWU_ParkingActiveForACC " ";
CM_ SG_ 266 EPB_Status "APA配置接收方无BDC ";
CM_ SG_ 266 EPB_FailStatus "APA配置接收方无BDC ";
CM_ SG_ 266 EPB_APArequest_Available "APA配置接收方无BDC ";
CM_ BO_ 1024 "Diag--VDC--I/O ";
CM_ BO_ 1107 "Diag--VDC--ADAS1 ";
CM_ BO_ 2015 " ";
CM_ BO_ 349 " ";
CM_ BO_ 271 "源端CHS_IBCU_1CB,0 ";
CM_ BO_ 810 " ";
CM_ BO_ 958 " ";
CM_ BO_ 890 " ";
CM_ SG_ 890 VMC_EcasModeCHASts " ";
CM_ SG_ 890 VMC_CtrlLevelRR " ";
CM_ SG_ 890 VMC_CtrlLevelRL " ";
CM_ SG_ 890 VMC_CtrlLevelFR " ";
CM_ SG_ 890 VMC_CtrlLevelFL " ";
CM_ SG_ 890 VMC_EcasModeVal " ";
CM_ SG_ 890 VMC_EcdcMode " ";
CM_ SG_ 890 VMC_EcasMode " ";
BA_DEF_ SG_  "GenSigStartValue" INT 0 0;
BA_DEF_ SG_  "GenSigInvalidValue" STRING ;
BA_DEF_ SG_  "GenSigCycleTime" INT 0 0;
BA_DEF_ SG_  "GenSigSendType" ENUM  "Cyclic","OnWrite","OnWriteWithRepetition","OnChange","OnChangeWithRepetition","IfActive","IfActiveWithRepetition","NoSigSendType","NotUsed","NotUsed","NotUsed","NotUsed","NotUsed";
BA_DEF_ BO_  "GenMsgSendType" ENUM  "Cyclic","Event","NotUsed","NotUsed","NotUsed","Cyclic","NotUsed","IfActive","NoMsgSendType","NotUsed";
BA_DEF_ BO_  "GenMsgILSupport" ENUM  "No","Yes";
BA_DEF_ BO_  "GenMsgCycleTime" INT 0 65535;
BA_DEF_ BO_  "CANFD_BRS" ENUM  "0","1";
BA_DEF_ BO_  "VFrameFormat" ENUM  "StandardCAN","ExtendedCAN","reserved","reserved","reserved","reserved","reserved","reserved","reserved","reserved","reserved","reserved","reserved","reserved","StandardCAN_FD","ExtendedCAN_FD";
BA_DEF_DEF_  "GenSigStartValue" 0;
BA_DEF_DEF_  "GenSigInvalidValue" "/";
BA_DEF_DEF_  "GenSigCycleTime" 0;
BA_DEF_DEF_  "GenSigSendType" "Cyclic";
BA_DEF_DEF_  "GenMsgSendType" "NoMsgSendType";
BA_DEF_DEF_  "GenMsgILSupport" "Yes";
BA_DEF_DEF_  "GenMsgCycleTime" 0;
BA_DEF_DEF_  "CANFD_BRS" "1";
BA_DEF_DEF_  "VFrameFormat" "StandardCAN";
BA_ "GenMsgSendType" BO_ 652 0;
BA_ "GenMsgCycleTime" BO_ 652 40;
BA_ "VFrameFormat" BO_ 652 14;
BA_ "GenMsgSendType" BO_ 817 0;
BA_ "GenMsgCycleTime" BO_ 817 100;
BA_ "VFrameFormat" BO_ 817 14;
BA_ "GenMsgSendType" BO_ 431 0;
BA_ "GenMsgCycleTime" BO_ 431 10;
BA_ "VFrameFormat" BO_ 431 14;
BA_ "GenMsgSendType" BO_ 800 0;
BA_ "GenMsgCycleTime" BO_ 800 100;
BA_ "VFrameFormat" BO_ 800 14;
BA_ "GenMsgSendType" BO_ 922 0;
BA_ "GenMsgCycleTime" BO_ 922 100;
BA_ "VFrameFormat" BO_ 922 14;
BA_ "GenMsgSendType" BO_ 784 0;
BA_ "GenMsgCycleTime" BO_ 784 100;
BA_ "VFrameFormat" BO_ 784 14;
BA_ "GenMsgSendType" BO_ 1000 0;
BA_ "GenMsgCycleTime" BO_ 1000 100;
BA_ "VFrameFormat" BO_ 1000 14;
BA_ "GenMsgSendType" BO_ 999 0;
BA_ "GenMsgCycleTime" BO_ 999 100;
BA_ "VFrameFormat" BO_ 999 14;
BA_ "GenMsgSendType" BO_ 906 0;
BA_ "GenMsgCycleTime" BO_ 906 40;
BA_ "VFrameFormat" BO_ 906 14;
BA_ "GenMsgSendType" BO_ 585 0;
BA_ "GenMsgCycleTime" BO_ 585 20;
BA_ "VFrameFormat" BO_ 585 14;
BA_ "GenMsgSendType" BO_ 610 0;
BA_ "GenMsgCycleTime" BO_ 610 40;
BA_ "VFrameFormat" BO_ 610 14;
BA_ "GenMsgSendType" BO_ 820 0;
BA_ "GenMsgCycleTime" BO_ 820 100;
BA_ "VFrameFormat" BO_ 820 14;
BA_ "GenMsgSendType" BO_ 917 0;
BA_ "GenMsgCycleTime" BO_ 917 100;
BA_ "VFrameFormat" BO_ 917 14;
BA_ "GenMsgSendType" BO_ 394 0;
BA_ "GenMsgCycleTime" BO_ 394 10;
BA_ "VFrameFormat" BO_ 394 14;
BA_ "GenMsgSendType" BO_ 586 0;
BA_ "GenMsgCycleTime" BO_ 586 20;
BA_ "VFrameFormat" BO_ 586 14;
BA_ "GenMsgSendType" BO_ 604 1;
BA_ "VFrameFormat" BO_ 604 14;
BA_ "GenMsgSendType" BO_ 727 0;
BA_ "GenMsgCycleTime" BO_ 727 50;
BA_ "VFrameFormat" BO_ 727 14;
BA_ "GenMsgSendType" BO_ 833 0;
BA_ "GenMsgCycleTime" BO_ 833 100;
BA_ "VFrameFormat" BO_ 833 14;
BA_ "GenMsgSendType" BO_ 982 0;
BA_ "GenMsgCycleTime" BO_ 982 100;
BA_ "VFrameFormat" BO_ 982 14;
BA_ "GenMsgSendType" BO_ 984 0;
BA_ "GenMsgCycleTime" BO_ 984 100;
BA_ "VFrameFormat" BO_ 984 14;
BA_ "GenMsgSendType" BO_ 990 0;
BA_ "GenMsgCycleTime" BO_ 990 100;
BA_ "VFrameFormat" BO_ 990 14;
BA_ "GenMsgSendType" BO_ 1006 0;
BA_ "GenMsgCycleTime" BO_ 1006 100;
BA_ "VFrameFormat" BO_ 1006 14;
BA_ "GenMsgSendType" BO_ 1712 1;
BA_ "VFrameFormat" BO_ 1712 14;
BA_ "GenMsgSendType" BO_ 723 0;
BA_ "GenMsgCycleTime" BO_ 723 40;
BA_ "VFrameFormat" BO_ 723 14;
BA_ "GenMsgSendType" BO_ 769 0;
BA_ "GenMsgCycleTime" BO_ 769 100;
BA_ "VFrameFormat" BO_ 769 14;
BA_ "GenMsgSendType" BO_ 780 0;
BA_ "GenMsgCycleTime" BO_ 780 100;
BA_ "VFrameFormat" BO_ 780 14;
BA_ "GenMsgSendType" BO_ 738 0;
BA_ "GenMsgCycleTime" BO_ 738 50;
BA_ "VFrameFormat" BO_ 738 14;
BA_ "GenMsgSendType" BO_ 739 0;
BA_ "GenMsgCycleTime" BO_ 739 50;
BA_ "VFrameFormat" BO_ 739 14;
BA_ "GenMsgSendType" BO_ 713 0;
BA_ "GenMsgCycleTime" BO_ 713 40;
BA_ "VFrameFormat" BO_ 713 14;
BA_ "GenMsgSendType" BO_ 1889 1;
BA_ "VFrameFormat" BO_ 1889 14;
BA_ "GenMsgSendType" BO_ 1405 1;
BA_ "VFrameFormat" BO_ 1405 14;
BA_ "GenMsgSendType" BO_ 1304 0;
BA_ "GenMsgCycleTime" BO_ 1304 500;
BA_ "VFrameFormat" BO_ 1304 14;
BA_ "GenMsgSendType" BO_ 686 0;
BA_ "GenMsgCycleTime" BO_ 686 50;
BA_ "VFrameFormat" BO_ 686 14;
BA_ "GenMsgSendType" BO_ 985 0;
BA_ "GenMsgCycleTime" BO_ 985 100;
BA_ "VFrameFormat" BO_ 985 14;
BA_ "GenMsgSendType" BO_ 987 0;
BA_ "GenMsgCycleTime" BO_ 987 100;
BA_ "VFrameFormat" BO_ 987 14;
BA_ "GenMsgSendType" BO_ 881 0;
BA_ "GenMsgCycleTime" BO_ 881 100;
BA_ "VFrameFormat" BO_ 881 14;
BA_ "GenMsgSendType" BO_ 796 0;
BA_ "GenMsgCycleTime" BO_ 796 100;
BA_ "VFrameFormat" BO_ 796 14;
BA_ "GenMsgSendType" BO_ 266 0;
BA_ "GenMsgCycleTime" BO_ 266 10;
BA_ "VFrameFormat" BO_ 266 14;
BA_ "GenMsgSendType" BO_ 1024 1;
BA_ "GenMsgSendType" BO_ 1107 1;
BA_ "GenMsgSendType" BO_ 2015 1;
BA_ "GenMsgSendType" BO_ 349 0;
BA_ "GenMsgCycleTime" BO_ 349 20;
BA_ "VFrameFormat" BO_ 349 14;
BA_ "GenMsgSendType" BO_ 271 0;
BA_ "GenMsgCycleTime" BO_ 271 20;
BA_ "VFrameFormat" BO_ 271 14;
BA_ "GenMsgSendType" BO_ 810 0;
BA_ "GenMsgCycleTime" BO_ 810 100;
BA_ "VFrameFormat" BO_ 810 14;
BA_ "GenMsgSendType" BO_ 958 0;
BA_ "GenMsgCycleTime" BO_ 958 100;
BA_ "VFrameFormat" BO_ 958 14;
BA_ "GenMsgSendType" BO_ 890 0;
BA_ "GenMsgCycleTime" BO_ 890 100;
BA_ "VFrameFormat" BO_ 890 14;
BA_ "GenSigStartValue" SG_ 652 GW_MFS_HODCalibratedStatus 1;
BA_ "GenSigCycleTime" SG_ 652 GW_MFS_HODCalibratedStatus 40;
BA_ "GenSigCycleTime" SG_ 652 GW_MFS_HODLinStatus 40;
BA_ "GenSigCycleTime" SG_ 652 GW_MFS_HODAppStatus 40;
BA_ "GenSigCycleTime" SG_ 652 GW_MFS_HODSenserStatus 40;
BA_ "GenSigCycleTime" SG_ 652 GW_MFS_HODSystemStatus 40;
BA_ "GenSigCycleTime" SG_ 652 GW_MFS_handsoffAbilityDetect 40;
BA_ "GenSigCycleTime" SG_ 652 GW_MFS_handsoffDetectResult 40;
BA_ "GenSigCycleTime" SG_ 652 GW_MFS_CRCCheck_28C 40;
BA_ "GenSigCycleTime" SG_ 652 GW_MFS_RollingCounter_28C 40;
BA_ "GenSigInvalidValue" SG_ 652 GW_MFS_DiagInfoSW_28C "7";
BA_ "GenSigCycleTime" SG_ 652 GW_MFS_DiagInfoSW_28C 40;
BA_ "GenSigInvalidValue" SG_ 652 GW_MFS_GearshiftReduce_switch "3";
BA_ "GenSigCycleTime" SG_ 652 GW_MFS_GearshiftReduce_switch 40;
BA_ "GenSigInvalidValue" SG_ 652 GW_MFS_GearshiftPlus_switch "3";
BA_ "GenSigCycleTime" SG_ 652 GW_MFS_GearshiftPlus_switch 40;
BA_ "GenSigInvalidValue" SG_ 652 GW_MFS_EPS_switch "3";
BA_ "GenSigCycleTime" SG_ 652 GW_MFS_EPS_switch 40;
BA_ "GenSigInvalidValue" SG_ 652 GW_MFS_ERSReduce_switch "3";
BA_ "GenSigCycleTime" SG_ 652 GW_MFS_ERSReduce_switch 40;
BA_ "GenSigInvalidValue" SG_ 652 GW_MFS_ERSPlus_switch "3";
BA_ "GenSigCycleTime" SG_ 652 GW_MFS_ERSPlus_switch 40;
BA_ "GenSigInvalidValue" SG_ 652 GW_MFS_IACCenable_switch_signal "3";
BA_ "GenSigCycleTime" SG_ 652 GW_MFS_IACCenable_switch_signal 40;
BA_ "GenSigInvalidValue" SG_ 652 GW_MFS_LIM_switch_signal "3";
BA_ "GenSigCycleTime" SG_ 652 GW_MFS_LIM_switch_signal 40;
BA_ "GenSigInvalidValue" SG_ 652 GW_MFS_DIST_switch_signal "3";
BA_ "GenSigCycleTime" SG_ 652 GW_MFS_DIST_switch_signal 40;
BA_ "GenSigInvalidValue" SG_ 652 GW_MFS_SETReduce_switch_signal "3";
BA_ "GenSigCycleTime" SG_ 652 GW_MFS_SETReduce_switch_signal 40;
BA_ "GenSigInvalidValue" SG_ 652 GW_MFS_RESPlus_switch_signal "3";
BA_ "GenSigCycleTime" SG_ 652 GW_MFS_RESPlus_switch_signal 40;
BA_ "GenSigInvalidValue" SG_ 652 GW_MFS_Cancle_switch_signal "3";
BA_ "GenSigCycleTime" SG_ 652 GW_MFS_Cancle_switch_signal 40;
BA_ "GenSigInvalidValue" SG_ 652 GW_MFS_Crusie_switch_signal "3";
BA_ "GenSigCycleTime" SG_ 652 GW_MFS_Crusie_switch_signal 40;
BA_ "GenSigCycleTime" SG_ 652 GW_MFS_DISTReduce_switch_signal 40;
BA_ "GenSigCycleTime" SG_ 652 GW_MFS_DISTPlus_switch_signal 40;
BA_ "GenSigCycleTime" SG_ 817 TCU_TransTempWarning 100;
BA_ "GenSigInvalidValue" SG_ 817 TCU_TransFluidTemp "255";
BA_ "GenSigCycleTime" SG_ 817 TCU_TransFluidTemp 100;
BA_ "GenSigInvalidValue" SG_ 817 TCU_TransFaultLevel "7";
BA_ "GenSigCycleTime" SG_ 817 TCU_TransFaultLevel 100;
BA_ "GenSigInvalidValue" SG_ 817 TCU_RotorAcutalCoolingFlow "63";
BA_ "GenSigCycleTime" SG_ 817 TCU_RotorAcutalCoolingFlow 100;
BA_ "GenSigCycleTime" SG_ 817 TCU_RollingCounter_338 100;
BA_ "GenSigCycleTime" SG_ 817 TCU_PowerplantStatusIPReq 100;
BA_ "GenSigCycleTime" SG_ 817 TCU_ParkSelectIPReq 100;
BA_ "GenSigCycleTime" SG_ 817 TCU_ParkRelMPosnIPReq 100;
BA_ "GenSigCycleTime" SG_ 817 TCU_ParkRelAPosnIPReq 100;
BA_ "GenSigInvalidValue" SG_ 817 TCU_K0ClutchExitOilTemp "255";
BA_ "GenSigCycleTime" SG_ 817 TCU_K0ClutchExitOilTemp 100;
BA_ "GenSigInvalidValue" SG_ 817 TCU_GearForDisplay "15";
BA_ "GenSigCycleTime" SG_ 817 TCU_GearForDisplay 100;
BA_ "GenSigCycleTime" SG_ 817 TCU_FailureLamp 100;
BA_ "GenSigCycleTime" SG_ 817 TCU_ESLFaultIPReq 100;
BA_ "GenSigCycleTime" SG_ 817 TCU_CRCCheck_338 100;
BA_ "GenSigInvalidValue" SG_ 817 TCU_CoolantFanRequest "127";
BA_ "GenSigCycleTime" SG_ 817 TCU_CoolantFanRequest 100;
BA_ "GenSigCycleTime" SG_ 817 TCU_ARCFaultIPReq 100;
BA_ "GenSigInvalidValue" SG_ 431 TCU_TipSwitchSignal "3";
BA_ "GenSigCycleTime" SG_ 431 TCU_TipSwitchSignal 10;
BA_ "GenSigCycleTime" SG_ 431 TCU_THOState 10;
BA_ "GenSigInvalidValue" SG_ 431 TCU_STLKfailure "1";
BA_ "GenSigCycleTime" SG_ 431 TCU_STLKfailure 10;
BA_ "GenSigInvalidValue" SG_ 431 TCU_ShiftPostionValid "1";
BA_ "GenSigCycleTime" SG_ 431 TCU_ShiftPostionValid 10;
BA_ "GenSigCycleTime" SG_ 431 TCU_RollingCounter_1A8 10;
BA_ "GenSigInvalidValue" SG_ 431 TCU_InputShaftSpeed "8191";
BA_ "GenSigCycleTime" SG_ 431 TCU_InputShaftSpeed 10;
BA_ "GenSigInvalidValue" SG_ 431 TCU_GearShiftPosition "15";
BA_ "GenSigStartValue" SG_ 431 TCU_GearShiftPosition 13;
BA_ "GenSigCycleTime" SG_ 431 TCU_GearShiftPosition 10;
BA_ "GenSigInvalidValue" SG_ 431 TCU_GearRatio "255";
BA_ "GenSigCycleTime" SG_ 431 TCU_GearRatio 10;
BA_ "GenSigCycleTime" SG_ 431 TCU_CRCCheck_1A8 10;
BA_ "GenSigInvalidValue" SG_ 431 TCU_ActualPreselectGear "15";
BA_ "GenSigCycleTime" SG_ 431 TCU_ActualPreselectGear 10;
BA_ "GenSigInvalidValue" SG_ 431 TCU_ActualDrivingGearValid "1";
BA_ "GenSigCycleTime" SG_ 431 TCU_ActualDrivingGearValid 10;
BA_ "GenSigInvalidValue" SG_ 431 TCU_ActualDrivingGear "15";
BA_ "GenSigCycleTime" SG_ 431 TCU_ActualDrivingGear 10;
BA_ "GenSigInvalidValue" SG_ 800 GW_ADSSecOCVerifyFailureFlag "1";
BA_ "GenSigCycleTime" SG_ 800 GW_ADSSecOCVerifyFailureFlag 100;
BA_ "GenSigInvalidValue" SG_ 800 GW_DCANDiagSts "NA";
BA_ "GenSigCycleTime" SG_ 800 GW_DCANDiagSts 100;
BA_ "GenSigInvalidValue" SG_ 800 GW_GatewayFailureFlag "0";
BA_ "GenSigCycleTime" SG_ 800 GW_GatewayFailureFlag 100;
BA_ "GenSigInvalidValue" SG_ 800 GW_OTAmode_Chks "0";
BA_ "GenSigCycleTime" SG_ 800 GW_OTAmode_Chks 100;
BA_ "GenSigInvalidValue" SG_ 800 GW_OTAmode_Cntr "0";
BA_ "GenSigCycleTime" SG_ 800 GW_OTAmode_Cntr 100;
BA_ "GenSigInvalidValue" SG_ 800 GW_OTAmode "0";
BA_ "GenSigCycleTime" SG_ 800 GW_OTAmode 100;
BA_ "GenSigInvalidValue" SG_ 800 GW_ResetReq "127";
BA_ "GenSigCycleTime" SG_ 800 GW_ResetReq 100;
BA_ "GenSigInvalidValue" SG_ 922 LAS_RoadFeature "15";
BA_ "GenSigStartValue" SG_ 922 LAS_RoadFeature 15;
BA_ "GenSigCycleTime" SG_ 922 LAS_RoadFeature 100;
BA_ "GenSigInvalidValue" SG_ 922 LAS_RD4LongDistence "255";
BA_ "GenSigStartValue" SG_ 922 LAS_RD4LongDistence 255;
BA_ "GenSigCycleTime" SG_ 922 LAS_RD4LongDistence 100;
BA_ "GenSigInvalidValue" SG_ 922 LAS_RD3LongDistence "255";
BA_ "GenSigStartValue" SG_ 922 LAS_RD3LongDistence 255;
BA_ "GenSigCycleTime" SG_ 922 LAS_RD3LongDistence 100;
BA_ "GenSigInvalidValue" SG_ 922 LAS_RD2LongDistence "255";
BA_ "GenSigStartValue" SG_ 922 LAS_RD2LongDistence 255;
BA_ "GenSigCycleTime" SG_ 922 LAS_RD2LongDistence 100;
BA_ "GenSigInvalidValue" SG_ 922 LAS_RD1LongDistence "255";
BA_ "GenSigStartValue" SG_ 922 LAS_RD1LongDistence 255;
BA_ "GenSigCycleTime" SG_ 922 LAS_RD1LongDistence 100;
BA_ "GenSigInvalidValue" SG_ 922 LAS_RD4RoadInforAvailable "1";
BA_ "GenSigCycleTime" SG_ 922 LAS_RD4RoadInforAvailable 100;
BA_ "GenSigInvalidValue" SG_ 922 LAS_RD3RoadInforAvailable "1";
BA_ "GenSigCycleTime" SG_ 922 LAS_RD3RoadInforAvailable 100;
BA_ "GenSigInvalidValue" SG_ 922 LAS_RD2RoadInforAvailable "1";
BA_ "GenSigCycleTime" SG_ 922 LAS_RD2RoadInforAvailable 100;
BA_ "GenSigInvalidValue" SG_ 922 LAS_RD1RoadInforAvailable "1";
BA_ "GenSigCycleTime" SG_ 922 LAS_RD1RoadInforAvailable 100;
BA_ "GenSigCycleTime" SG_ 922 LAS_RollingCounter_579 100;
BA_ "GenSigCycleTime" SG_ 922 LAS_CRCCheck_579 100;
BA_ "GenSigInvalidValue" SG_ 922 LAS_TSRSpeedLimitType "0";
BA_ "GenSigCycleTime" SG_ 922 LAS_TSRSpeedLimitType 100;
BA_ "GenSigCycleTime" SG_ 922 ACC_RollingCounter_39A 100;
BA_ "GenSigCycleTime" SG_ 922 ACC_CRCCheck_39A 100;
BA_ "GenSigCycleTime" SG_ 922 LAS_CRCCheck_3C0 100;
BA_ "GenSigCycleTime" SG_ 922 LAS_RollingCounter_3C0 100;
BA_ "GenSigCycleTime" SG_ 922 LAS_CRCCheck_3D4 100;
BA_ "GenSigCycleTime" SG_ 922 LAS_RollingCounter_3D4 100;
BA_ "GenSigCycleTime" SG_ 922 LAS_CRCCheck_332 100;
BA_ "GenSigCycleTime" SG_ 922 LAS_RollingCounter_332 100;
BA_ "GenSigCycleTime" SG_ 922 LAS_OverspeedSoundWarningEnSt 100;
BA_ "GenSigCycleTime" SG_ 922 LAS_TSREnable 100;
BA_ "GenSigCycleTime" SG_ 922 LAS_HMAEnableStatus 100;
BA_ "GenSigCycleTime" SG_ 922 LAS_HMALightDistribution 100;
BA_ "GenSigInvalidValue" SG_ 922 LAS_HMAStatus "3";
BA_ "GenSigCycleTime" SG_ 922 LAS_HMAStatus 100;
BA_ "GenSigInvalidValue" SG_ 922 LAS_TSRHostSpdLimitUnits "0";
BA_ "GenSigCycleTime" SG_ 922 LAS_TSRHostSpdLimitUnits 100;
BA_ "GenSigInvalidValue" SG_ 922 LAS_TSRHostSpdLimit "254";
BA_ "GenSigCycleTime" SG_ 922 LAS_TSRHostSpdLimit 100;
BA_ "GenSigInvalidValue" SG_ 922 LAS_TSRStatus "7";
BA_ "GenSigCycleTime" SG_ 922 LAS_TSRStatus 100;
BA_ "GenSigInvalidValue" SG_ 922 LAS_FrontCameraCalibrationStatus "3";
BA_ "GenSigCycleTime" SG_ 922 LAS_FrontCameraCalibrationStatus 100;
BA_ "GenSigInvalidValue" SG_ 922 LAS_FrontCameraFailureStatus "3";
BA_ "GenSigCycleTime" SG_ 922 LAS_FrontCameraFailureStatus 100;
BA_ "GenSigStartValue" SG_ 922 LAS_OverspeedWarningOffset 10;
BA_ "GenSigCycleTime" SG_ 922 LAS_OverspeedWarningOffset 100;
BA_ "GenSigCycleTime" SG_ 922 LAS_OverspeedWarningEnableStatus 100;
BA_ "GenSigCycleTime" SG_ 922 LAS_OverspeedSoundWarning 100;
BA_ "GenSigCycleTime" SG_ 922 LAS_OverspeedVisualWarning 100;
BA_ "GenSigCycleTime" SG_ 922 LAS_CRCCheck_37D 100;
BA_ "GenSigCycleTime" SG_ 922 LAS_RollingCounter_37D 100;
BA_ "GenSigStartValue" SG_ 922 LAS_CrosswalkLngRange_HLane 255;
BA_ "GenSigCycleTime" SG_ 922 LAS_CrosswalkLngRange_HLane 100;
BA_ "GenSigCycleTime" SG_ 784 AMP_VOLSpeedLevSETStatus 100;
BA_ "GenSigCycleTime" SG_ 784 AMP_VOLSpeedEnableSETStatus 100;
BA_ "GenSigCycleTime" SG_ 784 AMP_AllAlarmFailureStatus 100;
BA_ "GenSigCycleTime" SG_ 784 AMP_IPEnableAlarmFailureStatus 100;
BA_ "GenSigCycleTime" SG_ 784 AMP_MUTESETStatus 100;
BA_ "GenSigCycleTime" SG_ 784 AMP_SPKChannelSETStatus 100;
BA_ "GenSigCycleTime" SG_ 784 AMP_TouchVolSETStatus 100;
BA_ "GenSigCycleTime" SG_ 784 AMP_AlarmStyleSETStatus 100;
BA_ "GenSigCycleTime" SG_ 784 AMP_LRHeadSPKBalanceSETStatus 100;
BA_ "GenSigCycleTime" SG_ 784 AMP_AlarmVolSETStatus 100;
BA_ "GenSigCycleTime" SG_ 784 AMP_HeadSPKVolSETStatus 100;
BA_ "GenSigCycleTime" SG_ 784 AMP_HeadSPKMediaSETStatus 100;
BA_ "GenSigCycleTime" SG_ 784 AMP_HeadSPKTelSETStatus 100;
BA_ "GenSigCycleTime" SG_ 784 AMP_HeadSPKNIVISETStatus 100;
BA_ "GenSigInvalidValue" SG_ 1000 BCM_SOF_t_STATE "3";
BA_ "GenSigStartValue" SG_ 1000 BCM_SOF_t_STATE 3;
BA_ "GenSigCycleTime" SG_ 1000 BCM_SOF_t_STATE 100;
BA_ "GenSigInvalidValue" SG_ 1000 BCM_SOF_V2_STATE "3";
BA_ "GenSigStartValue" SG_ 1000 BCM_SOF_V2_STATE 3;
BA_ "GenSigCycleTime" SG_ 1000 BCM_SOF_V2_STATE 100;
BA_ "GenSigInvalidValue" SG_ 1000 BCM_SOF_V1_STATE "3";
BA_ "GenSigStartValue" SG_ 1000 BCM_SOF_V1_STATE 3;
BA_ "GenSigCycleTime" SG_ 1000 BCM_SOF_V1_STATE 100;
BA_ "GenSigInvalidValue" SG_ 1000 BCM_SOF_Q_STATE "3";
BA_ "GenSigStartValue" SG_ 1000 BCM_SOF_Q_STATE 3;
BA_ "GenSigCycleTime" SG_ 1000 BCM_SOF_Q_STATE 100;
BA_ "GenSigInvalidValue" SG_ 1000 BCM_SOC_STATE "3";
BA_ "GenSigStartValue" SG_ 1000 BCM_SOC_STATE 3;
BA_ "GenSigCycleTime" SG_ 1000 BCM_SOC_STATE 100;
BA_ "GenSigInvalidValue" SG_ 1000 BCM_SOF_t "1023";
BA_ "GenSigStartValue" SG_ 1000 BCM_SOF_t 1023;
BA_ "GenSigCycleTime" SG_ 1000 BCM_SOF_t 100;
BA_ "GenSigInvalidValue" SG_ 1000 BCM_SOF_V2 "255";
BA_ "GenSigStartValue" SG_ 1000 BCM_SOF_V2 255;
BA_ "GenSigCycleTime" SG_ 1000 BCM_SOF_V2 100;
BA_ "GenSigInvalidValue" SG_ 1000 BCM_SOF_V1 "255";
BA_ "GenSigStartValue" SG_ 1000 BCM_SOF_V1 255;
BA_ "GenSigCycleTime" SG_ 1000 BCM_SOF_V1 100;
BA_ "GenSigInvalidValue" SG_ 1000 BCM_SOF_Q "255";
BA_ "GenSigStartValue" SG_ 1000 BCM_SOF_Q 255;
BA_ "GenSigCycleTime" SG_ 1000 BCM_SOF_Q 100;
BA_ "GenSigInvalidValue" SG_ 1000 BCM_SOC "255";
BA_ "GenSigStartValue" SG_ 1000 BCM_SOC 255;
BA_ "GenSigCycleTime" SG_ 1000 BCM_SOC 100;
BA_ "GenSigInvalidValue" SG_ 999 BCM_Resp_Error "0";
BA_ "GenSigCycleTime" SG_ 999 BCM_Resp_Error 100;
BA_ "GenSigInvalidValue" SG_ 999 BCM_FLAG_INCONSISTENCY "0";
BA_ "GenSigCycleTime" SG_ 999 BCM_FLAG_INCONSISTENCY 100;
BA_ "GenSigInvalidValue" SG_ 999 BCM_Status_Current "0";
BA_ "GenSigCycleTime" SG_ 999 BCM_Status_Current 100;
BA_ "GenSigInvalidValue" SG_ 999 BCM_Status_Voltage "0";
BA_ "GenSigCycleTime" SG_ 999 BCM_Status_Voltage 100;
BA_ "GenSigInvalidValue" SG_ 999 BCM_Status_Temp "0";
BA_ "GenSigCycleTime" SG_ 999 BCM_Status_Temp 100;
BA_ "GenSigInvalidValue" SG_ 999 BCM_ERROR_Calib "0";
BA_ "GenSigCycleTime" SG_ 999 BCM_ERROR_Calib 100;
BA_ "GenSigInvalidValue" SG_ 999 BCM_ERROR_IDENT "0";
BA_ "GenSigCycleTime" SG_ 999 BCM_ERROR_IDENT 100;
BA_ "GenSigInvalidValue" SG_ 999 BCM_IBATT_QUIESCENT "255";
BA_ "GenSigStartValue" SG_ 999 BCM_IBATT_QUIESCENT 255;
BA_ "GenSigCycleTime" SG_ 999 BCM_IBATT_QUIESCENT 100;
BA_ "GenSigInvalidValue" SG_ 999 BCM_T_BATT "255";
BA_ "GenSigStartValue" SG_ 999 BCM_T_BATT 255;
BA_ "GenSigCycleTime" SG_ 999 BCM_T_BATT 100;
BA_ "GenSigInvalidValue" SG_ 999 BCM_I_BATT "65535";
BA_ "GenSigStartValue" SG_ 999 BCM_I_BATT 65535;
BA_ "GenSigCycleTime" SG_ 999 BCM_I_BATT 100;
BA_ "GenSigInvalidValue" SG_ 999 BCM_U_BATT "16383";
BA_ "GenSigStartValue" SG_ 999 BCM_U_BATT 16383;
BA_ "GenSigCycleTime" SG_ 999 BCM_U_BATT 100;
BA_ "GenSigInvalidValue" SG_ 999 BCM_I_RANGE "3";
BA_ "GenSigStartValue" SG_ 999 BCM_I_RANGE 3;
BA_ "GenSigCycleTime" SG_ 999 BCM_I_RANGE 100;
BA_ "GenSigInvalidValue" SG_ 906 GW_MFS_WeChat_switch_signal "3";
BA_ "GenSigCycleTime" SG_ 906 GW_MFS_WeChat_switch_signal 40;
BA_ "GenSigInvalidValue" SG_ 906 GW_MFS_AVM_switch "3";
BA_ "GenSigCycleTime" SG_ 906 GW_MFS_AVM_switch 40;
BA_ "GenSigInvalidValue" SG_ 906 GW_MFS_DiagInfoSW_38A "7";
BA_ "GenSigCycleTime" SG_ 906 GW_MFS_DiagInfoSW_38A 40;
BA_ "GenSigInvalidValue" SG_ 906 GW_MFS_Cust_switch "3";
BA_ "GenSigCycleTime" SG_ 906 GW_MFS_Cust_switch 40;
BA_ "GenSigInvalidValue" SG_ 906 GW_MFS_DVR_switch "3";
BA_ "GenSigCycleTime" SG_ 906 GW_MFS_DVR_switch 40;
BA_ "GenSigInvalidValue" SG_ 906 GW_MFS_Mode_switch "3";
BA_ "GenSigCycleTime" SG_ 906 GW_MFS_Mode_switch 40;
BA_ "GenSigInvalidValue" SG_ 906 GW_MFS_VolReduce_switch "3";
BA_ "GenSigCycleTime" SG_ 906 GW_MFS_VolReduce_switch 40;
BA_ "GenSigInvalidValue" SG_ 906 GW_MFS_VolPlus_switch "3";
BA_ "GenSigCycleTime" SG_ 906 GW_MFS_VolPlus_switch 40;
BA_ "GenSigInvalidValue" SG_ 906 GW_MFS_UP_switch "3";
BA_ "GenSigCycleTime" SG_ 906 GW_MFS_UP_switch 40;
BA_ "GenSigInvalidValue" SG_ 906 GW_MFS_Speech_switch "3";
BA_ "GenSigCycleTime" SG_ 906 GW_MFS_Speech_switch 40;
BA_ "GenSigInvalidValue" SG_ 906 GW_MFS_SeekPlus_switch "3";
BA_ "GenSigCycleTime" SG_ 906 GW_MFS_SeekPlus_switch 40;
BA_ "GenSigInvalidValue" SG_ 906 GW_MFS_Right_switch "3";
BA_ "GenSigCycleTime" SG_ 906 GW_MFS_Right_switch 40;
BA_ "GenSigInvalidValue" SG_ 906 GW_MFS_OK_switch "3";
BA_ "GenSigCycleTime" SG_ 906 GW_MFS_OK_switch 40;
BA_ "GenSigInvalidValue" SG_ 906 GW_MFS_Mute_switch "3";
BA_ "GenSigCycleTime" SG_ 906 GW_MFS_Mute_switch 40;
BA_ "GenSigInvalidValue" SG_ 906 GW_MFS_Left_switch "3";
BA_ "GenSigCycleTime" SG_ 906 GW_MFS_Left_switch 40;
BA_ "GenSigInvalidValue" SG_ 906 GW_MFS_Hungup_switch_signal "3";
BA_ "GenSigCycleTime" SG_ 906 GW_MFS_Hungup_switch_signal 40;
BA_ "GenSigInvalidValue" SG_ 906 GW_MFS_Down_switch "3";
BA_ "GenSigCycleTime" SG_ 906 GW_MFS_Down_switch 40;
BA_ "GenSigInvalidValue" SG_ 906 GW_MFS_Answer_switch_signal "3";
BA_ "GenSigCycleTime" SG_ 906 GW_MFS_Answer_switch_signal 40;
BA_ "GenSigInvalidValue" SG_ 906 GW_MFS_SeekReduce_switch "3";
BA_ "GenSigCycleTime" SG_ 906 GW_MFS_SeekReduce_switch 40;
BA_ "GenSigInvalidValue" SG_ 610 PEPS_RemoteStartKeyStatus "0";
BA_ "GenSigCycleTime" SG_ 610 PEPS_RemoteStartKeyStatus 40;
BA_ "GenSigCycleTime" SG_ 610 PEPS_APA_PowerMirrorFoldFeedback 40;
BA_ "GenSigCycleTime" SG_ 610 PEPS_APARemoteParkingOff 40;
BA_ "GenSigInvalidValue" SG_ 610 PEPS_KeyStandbyPositionIndicator "0";
BA_ "GenSigCycleTime" SG_ 610 PEPS_KeyStandbyPositionIndicator 40;
BA_ "GenSigCycleTime" SG_ 610 PEPS_CRCCheck_262 40;
BA_ "GenSigCycleTime" SG_ 610 PEPS_RollingCounter_262 40;
BA_ "GenSigCycleTime" SG_ 610 PEPS_PEPSFailStatus 40;
BA_ "GenSigCycleTime" SG_ 610 PEPS_PowerDistributionFaultBit 40;
BA_ "GenSigCycleTime" SG_ 610 PEPS_IMMOFeedback 40;
BA_ "GenSigCycleTime" SG_ 610 PEPS_EngineStartupInhibitFB 40;
BA_ "GenSigCycleTime" SG_ 610 PEPS_RemoteStartFeedback 40;
BA_ "GenSigCycleTime" SG_ 610 PEPS_EngineStartupInhibitSts 40;
BA_ "GenSigInvalidValue" SG_ 610 PEPS_PowerDistributionStatus "3";
BA_ "GenSigCycleTime" SG_ 610 PEPS_PowerDistributionStatus 40;
BA_ "GenSigCycleTime" SG_ 610 PEPS_UnallowStartSignal_Not_PN 40;
BA_ "GenSigCycleTime" SG_ 610 PEPS_IMMOFailedAlarmsignal 40;
BA_ "GenSigCycleTime" SG_ 610 PEPS_UnallowStart_ESCL_LOCK 40;
BA_ "GenSigCycleTime" SG_ 610 PEPS_UnallowStart_ESCL_Error 40;
BA_ "GenSigCycleTime" SG_ 610 PEPS_StartIndicatorSignal 40;
BA_ "GenSigInvalidValue" SG_ 610 PEPS_StartupButtonSignal "3";
BA_ "GenSigCycleTime" SG_ 610 PEPS_StartupButtonSignal 40;
BA_ "GenSigInvalidValue" SG_ 610 PEPS_APA_CloseWinFeedback "0";
BA_ "GenSigCycleTime" SG_ 610 PEPS_APA_CloseWinFeedback 40;
BA_ "GenSigCycleTime" SG_ 610 PEPS_RemoteControlACReq 40;
BA_ "GenSigInvalidValue" SG_ 610 PEPS_RemoteAPADoneKeyOffReq "0";
BA_ "GenSigCycleTime" SG_ 610 PEPS_RemoteAPADoneKeyOffReq 40;
BA_ "GenSigInvalidValue" SG_ 610 PEPS_APA_Engine0ffFeedback "0";
BA_ "GenSigCycleTime" SG_ 610 PEPS_APA_Engine0ffFeedback 40;
BA_ "GenSigInvalidValue" SG_ 610 PEPS_APA_LockFeedback "0";
BA_ "GenSigCycleTime" SG_ 610 PEPS_APA_LockFeedback 40;
BA_ "GenSigCycleTime" SG_ 610 PEPS_APARemoteParkingOn 40;
BA_ "GenSigCycleTime" SG_ 820 DSM_RollingCounter_334 100;
BA_ "GenSigCycleTime" SG_ 820 DSM_CRCCheck_334 100;
BA_ "GenSigInvalidValue" SG_ 820 DSM_RightMirrorUpDownSts "255";
BA_ "GenSigCycleTime" SG_ 820 DSM_RightMirrorUpDownSts 100;
BA_ "GenSigInvalidValue" SG_ 820 DSM_RightMirrorLeftRightSts "255";
BA_ "GenSigCycleTime" SG_ 820 DSM_RightMirrorLeftRightSts 100;
BA_ "GenSigInvalidValue" SG_ 820 DSM_LeftMirrorLeftRightSts "255";
BA_ "GenSigCycleTime" SG_ 820 DSM_LeftMirrorLeftRightSts 100;
BA_ "GenSigInvalidValue" SG_ 820 DSM_LeftMirrorUpDownSts "255";
BA_ "GenSigCycleTime" SG_ 820 DSM_LeftMirrorUpDownSts 100;
BA_ "GenSigCycleTime" SG_ 917 TBOX_EseUpdataHUWakeUpReq 100;
BA_ "GenSigCycleTime" SG_ 917 TBOX_RemoteInstallReq 100;
BA_ "GenSigInvalidValue" SG_ 917 TBOX_RemotePaVentilatieReq "0";
BA_ "GenSigCycleTime" SG_ 917 TBOX_RemotePaVentilatieReq 100;
BA_ "GenSigInvalidValue" SG_ 917 TBOX_RemoteDrVentilatieReq "0";
BA_ "GenSigCycleTime" SG_ 917 TBOX_RemoteDrVentilatieReq 100;
BA_ "GenSigInvalidValue" SG_ 917 TBOX_BCallStatus "7";
BA_ "GenSigCycleTime" SG_ 917 TBOX_BCallStatus 100;
BA_ "GenSigInvalidValue" SG_ 917 TBOX_AudioRequest "3";
BA_ "GenSigCycleTime" SG_ 917 TBOX_AudioRequest 100;
BA_ "GenSigInvalidValue" SG_ 917 TBOX_ChangePartStatus "0";
BA_ "GenSigCycleTime" SG_ 917 TBOX_ChangePartStatus 100;
BA_ "GenSigInvalidValue" SG_ 917 TBOX_CallStatus "7";
BA_ "GenSigCycleTime" SG_ 917 TBOX_CallStatus 100;
BA_ "GenSigInvalidValue" SG_ 917 TBOX_RemoteAirCleanReq "3";
BA_ "GenSigCycleTime" SG_ 917 TBOX_RemoteAirCleanReq 100;
BA_ "GenSigInvalidValue" SG_ 917 TBOX_RemoteAirQualityInquire "3";
BA_ "GenSigCycleTime" SG_ 917 TBOX_RemoteAirQualityInquire 100;
BA_ "GenSigInvalidValue" SG_ 917 TBOX_RemoteSteerWheelHotReq "3";
BA_ "GenSigCycleTime" SG_ 917 TBOX_RemoteSteerWheelHotReq 100;
BA_ "GenSigInvalidValue" SG_ 917 TBOX_RemoteDriverSeatHotReq "0";
BA_ "GenSigCycleTime" SG_ 917 TBOX_RemoteDriverSeatHotReq 100;
BA_ "GenSigInvalidValue" SG_ 917 TBOX_RemotePassangerSeatHotReq "0";
BA_ "GenSigCycleTime" SG_ 917 TBOX_RemotePassangerSeatHotReq 100;
BA_ "GenSigInvalidValue" SG_ 917 TBOX_SearchCarReq "0";
BA_ "GenSigCycleTime" SG_ 917 TBOX_SearchCarReq 100;
BA_ "GenSigInvalidValue" SG_ 917 TBOX_RmoteTrunk "0";
BA_ "GenSigCycleTime" SG_ 917 TBOX_RmoteTrunk 100;
BA_ "GenSigInvalidValue" SG_ 917 TBOX_RmoteRoof "0";
BA_ "GenSigCycleTime" SG_ 917 TBOX_RmoteRoof 100;
BA_ "GenSigInvalidValue" SG_ 917 TBOX_RemoteACStartupReq "0";
BA_ "GenSigCycleTime" SG_ 917 TBOX_RemoteACStartupReq 100;
BA_ "GenSigInvalidValue" SG_ 917 TBOX_VehicleStatusDemandReq "0";
BA_ "GenSigCycleTime" SG_ 917 TBOX_VehicleStatusDemandReq 100;
BA_ "GenSigInvalidValue" SG_ 917 TBOX_RemoteStartRunTime "0";
BA_ "GenSigCycleTime" SG_ 917 TBOX_RemoteStartRunTime 100;
BA_ "GenSigInvalidValue" SG_ 917 TBOX_VINMatchStatus "3";
BA_ "GenSigCycleTime" SG_ 917 TBOX_VINMatchStatus 100;
BA_ "GenSigInvalidValue" SG_ 917 TBOX_VINReq "3";
BA_ "GenSigCycleTime" SG_ 917 TBOX_VINReq 100;
BA_ "GenSigInvalidValue" SG_ 917 TBOX_ACTempValueReq "0";
BA_ "GenSigCycleTime" SG_ 917 TBOX_ACTempValueReq 100;
BA_ "GenSigInvalidValue" SG_ 917 TBOX_CarRemind "0";
BA_ "GenSigCycleTime" SG_ 917 TBOX_CarRemind 100;
BA_ "GenSigInvalidValue" SG_ 917 TBOX_RemoteEngineStartupReq "3";
BA_ "GenSigCycleTime" SG_ 917 TBOX_RemoteEngineStartupReq 100;
BA_ "GenSigInvalidValue" SG_ 917 TBOX_EngineStartupInhibit "3";
BA_ "GenSigCycleTime" SG_ 917 TBOX_EngineStartupInhibit 100;
BA_ "GenSigInvalidValue" SG_ 917 TBOX_LockCommand "3";
BA_ "GenSigCycleTime" SG_ 917 TBOX_LockCommand 100;
BA_ "GenSigCycleTime" SG_ 917 TBox_ResetFlag_395 100;
BA_ "GenSigCycleTime" SG_ 917 TBox_MesssageCounter_395 100;
BA_ "GenSigCycleTime" SG_ 917 TBox_Authenticator_395 100;
BA_ "GenSigCycleTime" SG_ 917 TBOX_APARemoteDriveReq 100;
BA_ "GenSigCycleTime" SG_ 917 TBOX_HZPFunctionReq 100;
BA_ "GenSigCycleTime" SG_ 917 TBOX_HZPControlEnable 100;
BA_ "GenSigCycleTime" SG_ 917 TBOX_SignalStrength 100;
BA_ "GenSigCycleTime" SG_ 917 TBOX_SignalType 100;
BA_ "GenSigCycleTime" SG_ 917 TBOX_APA_SignalDelay 100;
BA_ "GenSigCycleTime" SG_ 917 TBOX_APA_VideoDelay 100;
BA_ "GenSigCycleTime" SG_ 917 TBOX_AVM_DisplayForm 100;
BA_ "GenSigCycleTime" SG_ 917 TBOX_TurnRight 100;
BA_ "GenSigCycleTime" SG_ 917 TBOX_TurnLeft 100;
BA_ "GenSigCycleTime" SG_ 917 TBOX_Verticalforward 100;
BA_ "GenSigCycleTime" SG_ 917 TBOX_Verticalbackward 100;
BA_ "GenSigCycleTime" SG_ 917 TBOX_APAPOCModeSelect 100;
BA_ "GenSigCycleTime" SG_ 917 TBOX_APAFuctionSelection 100;
BA_ "GenSigCycleTime" SG_ 917 TBOX_APAManeuverSuspend 100;
BA_ "GenSigCycleTime" SG_ 917 TBOX_APAManeuverStart 100;
BA_ "GenSigCycleTime" SG_ 917 TBOX_APAManeuverCancel 100;
BA_ "GenSigCycleTime" SG_ 917 TBOX_APAmoduleEnable 100;
BA_ "GenSigCycleTime" SG_ 917 TBOX_RemoteDisReq 100;
BA_ "GenSigInvalidValue" SG_ 917 TBOX_VehicleVedioDetectReq "0";
BA_ "GenSigCycleTime" SG_ 917 TBOX_VehicleVedioDetectReq 100;
BA_ "GenSigInvalidValue" SG_ 917 TBOX_RemoteDetectReq "3";
BA_ "GenSigCycleTime" SG_ 917 TBOX_RemoteDetectReq 100;
BA_ "GenSigInvalidValue" SG_ 394 TCU_APAShiftGearRequestEnable "3";
BA_ "GenSigCycleTime" SG_ 394 TCU_APAShiftGearRequestEnable 10;
BA_ "GenSigInvalidValue" SG_ 394 TCU_APAdriverInterruption "3";
BA_ "GenSigCycleTime" SG_ 394 TCU_APAdriverInterruption 10;
BA_ "GenSigCycleTime" SG_ 586 ESL_HALLStatus 100;
BA_ "GenSigCycleTime" SG_ 586 ESL_DriveModeFaultStatus 100;
BA_ "GenSigCycleTime" SG_ 586 ESL_UnLockButtonFaultStatus 100;
BA_ "GenSigInvalidValue" SG_ 586 ESL_EPBButton_FaultStatus "2";
BA_ "GenSigCycleTime" SG_ 586 ESL_EPBButton_FaultStatus 100;
BA_ "GenSigCycleTime" SG_ 586 ESL_UnLockButtonPositionStatus 100;
BA_ "GenSigInvalidValue" SG_ 586 ESL_EPBButton_PositionStatus "3";
BA_ "GenSigCycleTime" SG_ 586 ESL_EPBButton_PositionStatus 100;
BA_ "GenSigInvalidValue" SG_ 586 ESL_ResetSts "7";
BA_ "GenSigCycleTime" SG_ 586 ESL_ResetSts 100;
BA_ "GenSigCycleTime" SG_ 586 ESL_TcugearRef 20;
BA_ "GenSigCycleTime" SG_ 586 ESL_CRCCheck_24A 20;
BA_ "GenSigCycleTime" SG_ 586 ESL_RollingCounter_24A 20;
BA_ "GenSigInvalidValue" SG_ 586 ESL_DriveModeRequest "15";
BA_ "GenSigCycleTime" SG_ 586 ESL_DriveModeRequest 20;
BA_ "GenSigCycleTime" SG_ 586 ESL_DriverParkButtonFaultStatus 20;
BA_ "GenSigInvalidValue" SG_ 586 ESL_DriverParkRequest "3";
BA_ "GenSigCycleTime" SG_ 586 ESL_DriverParkRequest 20;
BA_ "GenSigInvalidValue" SG_ 586 ESL_ShiftLeverPositionrequest "15";
BA_ "GenSigCycleTime" SG_ 586 ESL_ShiftLeverPositionrequest 20;
BA_ "GenSigCycleTime" SG_ 586 ESL_ShiftLeverPositionFaultSts 20;
BA_ "GenSigSendType" SG_ 604 GW_Authernticator_25C 1;
BA_ "GenSigSendType" SG_ 604 GW_ResetCounter_25C 1;
BA_ "GenSigSendType" SG_ 604 GW_TripCounter_25C 1;
BA_ "GenSigCycleTime" SG_ 727 HU_DVRDrivingPlaySwitchStatus 50;
BA_ "GenSigCycleTime" SG_ 727 HU_ScreenOperateStatus 50;
BA_ "GenSigInvalidValue" SG_ 727 HU_3DHorAngleReq "511";
BA_ "GenSigCycleTime" SG_ 727 HU_3DHorAngleReq 50;
BA_ "GenSigCycleTime" SG_ 727 HU_DVRMode 50;
BA_ "GenSigInvalidValue" SG_ 727 HU_AVMswitch "0";
BA_ "GenSigCycleTime" SG_ 727 HU_AVMswitch 50;
BA_ "GenSigInvalidValue" SG_ 727 HU_DVRDisplayVision "7";
BA_ "GenSigCycleTime" SG_ 727 HU_DVRDisplayVision 50;
BA_ "GenSigInvalidValue" SG_ 727 HU_AVMTriggermethod "0";
BA_ "GenSigCycleTime" SG_ 727 HU_AVMTriggermethod 50;
BA_ "GenSigCycleTime" SG_ 833 PCU_RollingCounter_341 100;
BA_ "GenSigCycleTime" SG_ 833 PCU_PwrTqWhMinVld 100;
BA_ "GenSigCycleTime" SG_ 833 PCU_PwrTqWhMinTotal 100;
BA_ "GenSigCycleTime" SG_ 833 PCU_PwrTqWhMaxVld 100;
BA_ "GenSigCycleTime" SG_ 833 PCU_PwrTqWhMaxTotal 100;
BA_ "GenSigCycleTime" SG_ 833 PCU_CRCCheck_341 100;
BA_ "GenSigCycleTime" SG_ 833 PCU_AccPedShield 100;
BA_ "GenSigInvalidValue" SG_ 982 SLCM_RRWindowStatus "255";
BA_ "GenSigCycleTime" SG_ 982 SLCM_RRWindowStatus 100;
BA_ "GenSigInvalidValue" SG_ 982 SLCM_FRWindowStatus "255";
BA_ "GenSigCycleTime" SG_ 982 SLCM_FRWindowStatus 100;
BA_ "GenSigCycleTime" SG_ 984 SLCM_RLWinMotor 100;
BA_ "GenSigCycleTime" SG_ 984 SLCM_DriverWinMotor 100;
BA_ "GenSigCycleTime" SG_ 984 SLCM_FailStatus 100;
BA_ "GenSigCycleTime" SG_ 984 SLCM_RLWindowSwitch 100;
BA_ "GenSigCycleTime" SG_ 984 SLCM_DriverWindowSwitch 100;
BA_ "GenSigCycleTime" SG_ 984 SLCM_RLWindowAPActice 100;
BA_ "GenSigCycleTime" SG_ 984 SLCM_DriverWindowAPActice 100;
BA_ "GenSigCycleTime" SG_ 984 SLCM_RLWindowInitializedSts 100;
BA_ "GenSigCycleTime" SG_ 984 SLCM_DriverWindowInitializedSts 100;
BA_ "GenSigInvalidValue" SG_ 984 SLCM_RLWindowStatus "255";
BA_ "GenSigCycleTime" SG_ 984 SLCM_RLWindowStatus 100;
BA_ "GenSigInvalidValue" SG_ 984 SLCM_DriverWindowStatus "255";
BA_ "GenSigCycleTime" SG_ 984 SLCM_DriverWindowStatus 100;
BA_ "GenSigCycleTime" SG_ 990 DSM_RollingCounter_3DE 100;
BA_ "GenSigCycleTime" SG_ 990 DSM_CRCCheck_3DE 100;
BA_ "GenSigInvalidValue" SG_ 990 DSM_DSMBackrestPositionSts "255";
BA_ "GenSigCycleTime" SG_ 990 DSM_DSMBackrestPositionSts 100;
BA_ "GenSigInvalidValue" SG_ 990 DSM_DSMVerticalPositionSts "255";
BA_ "GenSigCycleTime" SG_ 990 DSM_DSMVerticalPositionSts 100;
BA_ "GenSigInvalidValue" SG_ 990 DSM_DSMFrontEndPositionSts "255";
BA_ "GenSigCycleTime" SG_ 990 DSM_DSMFrontEndPositionSts 100;
BA_ "GenSigInvalidValue" SG_ 990 DSM_DSMHorizontalPositionSts "255";
BA_ "GenSigCycleTime" SG_ 990 DSM_DSMHorizontalPositionSts 100;
BA_ "GenSigInvalidValue" SG_ 1006 GW_SafCertSts "3";
BA_ "GenSigCycleTime" SG_ 1006 GW_SafCertSts 100;
BA_ "GenSigSendType" SG_ 1712 GW_APA_AuthenticationStatus 1;
BA_ "GenSigCycleTime" SG_ 723 ACC_CRCCheck_283 40;
BA_ "GenSigCycleTime" SG_ 723 ACC_RollingCounter_283 40;
BA_ "GenSigCycleTime" SG_ 723 ACC_AEBTargetLatRelSpeed_for_SRS 40;
BA_ "GenSigStartValue" SG_ 723 ACC_AEBTargetLatRange_for_SRS 500;
BA_ "GenSigCycleTime" SG_ 723 ACC_AEBTargetLatRange_for_SRS 40;
BA_ "GenSigCycleTime" SG_ 723 ACC_CRCCheckr_282 40;
BA_ "GenSigCycleTime" SG_ 723 ACC_RollingCounter_282 40;
BA_ "GenSigCycleTime" SG_ 723 ACC_AEBTargetProb_for_SRS 40;
BA_ "GenSigStartValue" SG_ 723 ACC_AEBTargetType_for_SRS 15;
BA_ "GenSigCycleTime" SG_ 723 ACC_AEBTargetType_for_SRS 40;
BA_ "GenSigInvalidValue" SG_ 723 ACC_AEBTargetTTC_for_SRS "254";
BA_ "GenSigStartValue" SG_ 723 ACC_AEBTargetTTC_for_SRS 251;
BA_ "GenSigCycleTime" SG_ 723 ACC_AEBTargetTTC_for_SRS 40;
BA_ "GenSigStartValue" SG_ 723 ACC_AEBTargetRelSpeed_for_SRS 250;
BA_ "GenSigCycleTime" SG_ 723 ACC_AEBTargetRelSpeed_for_SRS 40;
BA_ "GenSigStartValue" SG_ 723 ACC_AEBTargetLngRange_for_SRS 500;
BA_ "GenSigCycleTime" SG_ 723 ACC_AEBTargetLngRange_for_SRS 40;
BA_ "GenSigCycleTime" SG_ 723 ACC_AEBActive_for_SRS 40;
BA_ "GenSigInvalidValue" SG_ 723 ACC_AEBStatus_for_SRS "3";
BA_ "GenSigCycleTime" SG_ 723 ACC_AEBStatus_for_SRS 40;
BA_ "GenSigInvalidValue" SG_ 769 ACC_ResetSts "7";
BA_ "GenSigCycleTime" SG_ 769 ACC_ResetSts 100;
BA_ "GenSigInvalidValue" SG_ 780 LAS_ResetSts "7";
BA_ "GenSigCycleTime" SG_ 780 LAS_ResetSts 100;
BA_ "GenSigCycleTime" SG_ 738 RLR_CRCCheck_2E2 50;
BA_ "GenSigCycleTime" SG_ 738 RLR_RollingCounter_2E2 50;
BA_ "GenSigInvalidValue" SG_ 738 RLR_ElkOBJ2_Measured "0";
BA_ "GenSigCycleTime" SG_ 738 RLR_ElkOBJ2_Measured 50;
BA_ "GenSigInvalidValue" SG_ 738 RLR_ElkOBJ2_ExistProb "0";
BA_ "GenSigCycleTime" SG_ 738 RLR_ElkOBJ2_ExistProb 50;
BA_ "GenSigInvalidValue" SG_ 738 RLR_ElkOBJ2_Location "0";
BA_ "GenSigCycleTime" SG_ 738 RLR_ElkOBJ2_Location 50;
BA_ "GenSigCycleTime" SG_ 738 RLR_ElkOBJ2_RelAx 50;
BA_ "GenSigCycleTime" SG_ 738 RLR_ElkOBJ2_RelAy 50;
BA_ "GenSigCycleTime" SG_ 738 RLR_ElkOBJ2_RelVx 50;
BA_ "GenSigCycleTime" SG_ 738 RLR_ElkOBJ2_RelVy 50;
BA_ "GenSigCycleTime" SG_ 738 RLR_ElkOBJ2_Dx 50;
BA_ "GenSigCycleTime" SG_ 738 RLR_ElkOBJ2_RefPointLoc 50;
BA_ "GenSigCycleTime" SG_ 738 RLR_ElkOBJ2_Dy 50;
BA_ "GenSigCycleTime" SG_ 738 RLR_ElkOBJ2_HeadingAngle 50;
BA_ "GenSigCycleTime" SG_ 738 RLR_ElkOBJ2_Length 50;
BA_ "GenSigCycleTime" SG_ 738 RLR_ElkOBJ2_Height 50;
BA_ "GenSigCycleTime" SG_ 738 RLR_ElkOBJ2_Width 50;
BA_ "GenSigInvalidValue" SG_ 738 RLR_ElkOBJ2_Type "0";
BA_ "GenSigCycleTime" SG_ 738 RLR_ElkOBJ2_Type 50;
BA_ "GenSigCycleTime" SG_ 738 RLR_ElkOBJ2_Track_ID 50;
BA_ "GenSigCycleTime" SG_ 738 RLR_ElkOBJ2_RefPointDx 50;
BA_ "GenSigCycleTime" SG_ 738 RLR_ElkOBJ2_RefPointDy 50;
BA_ "GenSigCycleTime" SG_ 738 RLR_ElkOBJ2_ObstacleProb 50;
BA_ "GenSigCycleTime" SG_ 738 RLR_ElkOBJ1_RefPointDx 50;
BA_ "GenSigCycleTime" SG_ 738 RLR_ElkOBJ1_RefPointDy 50;
BA_ "GenSigCycleTime" SG_ 738 RLR_ElkOBJ1_ObstacleProb 50;
BA_ "GenSigInvalidValue" SG_ 738 RLR_ElkOBJ1_Measured "0";
BA_ "GenSigCycleTime" SG_ 738 RLR_ElkOBJ1_Measured 50;
BA_ "GenSigInvalidValue" SG_ 738 RLR_ElkOBJ1_ExistProb "0";
BA_ "GenSigCycleTime" SG_ 738 RLR_ElkOBJ1_ExistProb 50;
BA_ "GenSigInvalidValue" SG_ 738 RLR_ElkOBJ1_Location "0";
BA_ "GenSigCycleTime" SG_ 738 RLR_ElkOBJ1_Location 50;
BA_ "GenSigCycleTime" SG_ 738 RLR_ElkOBJ1_RelAx 50;
BA_ "GenSigCycleTime" SG_ 738 RLR_ElkOBJ1_RelAy 50;
BA_ "GenSigCycleTime" SG_ 738 RLR_ElkOBJ1_RelVx 50;
BA_ "GenSigCycleTime" SG_ 738 RLR_ElkOBJ1_RelVy 50;
BA_ "GenSigCycleTime" SG_ 738 RLR_ElkOBJ1_Dx 50;
BA_ "GenSigCycleTime" SG_ 738 RLR_ElkOBJ1_RefPointLoc 50;
BA_ "GenSigCycleTime" SG_ 738 RLR_ElkOBJ1_Dy 50;
BA_ "GenSigCycleTime" SG_ 738 RLR_ElkOBJ1_HeadingAngle 50;
BA_ "GenSigCycleTime" SG_ 738 RLR_ElkOBJ1_Length 50;
BA_ "GenSigCycleTime" SG_ 738 RLR_ElkOBJ1_Height 50;
BA_ "GenSigCycleTime" SG_ 738 RLR_ElkOBJ1_Width 50;
BA_ "GenSigInvalidValue" SG_ 738 RLR_ElkOBJ1_Type "0";
BA_ "GenSigCycleTime" SG_ 738 RLR_ElkOBJ1_Type 50;
BA_ "GenSigCycleTime" SG_ 738 RLR_ElkOBJ1_Track_ID 50;
BA_ "GenSigCycleTime" SG_ 739 RLR_CRCCheck_2E3 50;
BA_ "GenSigCycleTime" SG_ 739 RLR_RollingCounter_2E3 50;
BA_ "GenSigInvalidValue" SG_ 739 RLR_ElkOBJ4_Measured "0";
BA_ "GenSigCycleTime" SG_ 739 RLR_ElkOBJ4_Measured 50;
BA_ "GenSigInvalidValue" SG_ 739 RLR_ElkOBJ4_ExistProb "0";
BA_ "GenSigCycleTime" SG_ 739 RLR_ElkOBJ4_ExistProb 50;
BA_ "GenSigInvalidValue" SG_ 739 RLR_ElkOBJ4_Location "0";
BA_ "GenSigCycleTime" SG_ 739 RLR_ElkOBJ4_Location 50;
BA_ "GenSigCycleTime" SG_ 739 RLR_ElkOBJ4_RelAx 50;
BA_ "GenSigCycleTime" SG_ 739 RLR_ElkOBJ4_RelAy 50;
BA_ "GenSigCycleTime" SG_ 739 RLR_ElkOBJ4_RelVx 50;
BA_ "GenSigCycleTime" SG_ 739 RLR_ElkOBJ4_RelVy 50;
BA_ "GenSigCycleTime" SG_ 739 RLR_ElkOBJ4_Dx 50;
BA_ "GenSigCycleTime" SG_ 739 RLR_ElkOBJ4_RefPointLoc 50;
BA_ "GenSigCycleTime" SG_ 739 RLR_ElkOBJ4_Dy 50;
BA_ "GenSigCycleTime" SG_ 739 RLR_ElkOBJ4_HeadingAngle 50;
BA_ "GenSigCycleTime" SG_ 739 RLR_ElkOBJ4_Length 50;
BA_ "GenSigCycleTime" SG_ 739 RLR_ElkOBJ4_Height 50;
BA_ "GenSigCycleTime" SG_ 739 RLR_ElkOBJ4_Width 50;
BA_ "GenSigInvalidValue" SG_ 739 RLR_ElkOBJ4_Type "0";
BA_ "GenSigCycleTime" SG_ 739 RLR_ElkOBJ4_Type 50;
BA_ "GenSigCycleTime" SG_ 739 RLR_ElkOBJ4_Track_ID 50;
BA_ "GenSigCycleTime" SG_ 739 RLR_ElkOBJ4_RefPointDx 50;
BA_ "GenSigCycleTime" SG_ 739 RLR_ElkOBJ4_RefPointDy 50;
BA_ "GenSigCycleTime" SG_ 739 RLR_ElkOBJ4_ObstacleProb 50;
BA_ "GenSigCycleTime" SG_ 739 RLR_ElkOBJ3_RefPointDx 50;
BA_ "GenSigCycleTime" SG_ 739 RLR_ElkOBJ3_RefPointDy 50;
BA_ "GenSigCycleTime" SG_ 739 RLR_ElkOBJ3_ObstacleProb 50;
BA_ "GenSigInvalidValue" SG_ 739 RLR_ElkOBJ3_Measured "0";
BA_ "GenSigCycleTime" SG_ 739 RLR_ElkOBJ3_Measured 50;
BA_ "GenSigInvalidValue" SG_ 739 RLR_ElkOBJ3_ExistProb "0";
BA_ "GenSigCycleTime" SG_ 739 RLR_ElkOBJ3_ExistProb 50;
BA_ "GenSigInvalidValue" SG_ 739 RLR_ElkOBJ3_Location "0";
BA_ "GenSigCycleTime" SG_ 739 RLR_ElkOBJ3_Location 50;
BA_ "GenSigCycleTime" SG_ 739 RLR_ElkOBJ3_RelAx 50;
BA_ "GenSigCycleTime" SG_ 739 RLR_ElkOBJ3_RelAy 50;
BA_ "GenSigCycleTime" SG_ 739 RLR_ElkOBJ3_RelVx 50;
BA_ "GenSigCycleTime" SG_ 739 RLR_ElkOBJ3_RelVy 50;
BA_ "GenSigCycleTime" SG_ 739 RLR_ElkOBJ3_Dx 50;
BA_ "GenSigCycleTime" SG_ 739 RLR_ElkOBJ3_RefPointLoc 50;
BA_ "GenSigCycleTime" SG_ 739 RLR_ElkOBJ3_Dy 50;
BA_ "GenSigCycleTime" SG_ 739 RLR_ElkOBJ3_HeadingAngle 50;
BA_ "GenSigCycleTime" SG_ 739 RLR_ElkOBJ3_Length 50;
BA_ "GenSigCycleTime" SG_ 739 RLR_ElkOBJ3_Height 50;
BA_ "GenSigCycleTime" SG_ 739 RLR_ElkOBJ3_Width 50;
BA_ "GenSigInvalidValue" SG_ 739 RLR_ElkOBJ3_Type "0";
BA_ "GenSigCycleTime" SG_ 739 RLR_ElkOBJ3_Type 50;
BA_ "GenSigCycleTime" SG_ 739 RLR_ElkOBJ3_Track_ID 50;
BA_ "GenSigInvalidValue" SG_ 713 HU_Novice_Response "0";
BA_ "GenSigCycleTime" SG_ 713 HU_Novice_Response 40;
BA_ "GenSigCycleTime" SG_ 713 HU_InterfaceChangeSingnal 40;
BA_ "GenSigInvalidValue" SG_ 713 HU_Ylevel "65535";
BA_ "GenSigCycleTime" SG_ 713 HU_Ylevel 40;
BA_ "GenSigInvalidValue" SG_ 713 HU_Xlevel "65535";
BA_ "GenSigCycleTime" SG_ 713 HU_Xlevel 40;
BA_ "GenSigSendType" SG_ 1889 Diagnose_message761 1;
BA_ "GenSigInvalidValue" SG_ 1405 HU_APAOnOff "0";
BA_ "GenSigStartValue" SG_ 1405 HU_APAOnOff 1;
BA_ "GenSigSendType" SG_ 1405 HU_APAOnOff 1;
BA_ "GenSigInvalidValue" SG_ 1304 BCM_CarMode "0";
BA_ "GenSigCycleTime" SG_ 1304 BCM_CarMode 500;
BA_ "GenSigInvalidValue" SG_ 686 LCDAL_SystemStatus "7";
BA_ "GenSigStartValue" SG_ 686 LCDAL_SystemStatus 1;
BA_ "GenSigCycleTime" SG_ 686 LCDAL_SystemStatus 50;
BA_ "GenSigCycleTime" SG_ 985 ACC_ObsTarget10ID 100;
BA_ "GenSigCycleTime" SG_ 985 ACC_ObsTarget10Type 100;
BA_ "GenSigStartValue" SG_ 985 ACC_ObsTarget10LatRange 1023;
BA_ "GenSigCycleTime" SG_ 985 ACC_ObsTarget10LatRange 100;
BA_ "GenSigStartValue" SG_ 985 ACC_ObsTarget10LngRange 2047;
BA_ "GenSigCycleTime" SG_ 985 ACC_ObsTarget10LngRange 100;
BA_ "GenSigCycleTime" SG_ 985 ACC_ObsTarget9ID 100;
BA_ "GenSigCycleTime" SG_ 985 ACC_ObsTarget9Type 100;
BA_ "GenSigStartValue" SG_ 985 ACC_ObsTarget9LatRange 1023;
BA_ "GenSigCycleTime" SG_ 985 ACC_ObsTarget9LatRange 100;
BA_ "GenSigStartValue" SG_ 985 ACC_ObsTarget9LngRange 2047;
BA_ "GenSigCycleTime" SG_ 985 ACC_ObsTarget9LngRange 100;
BA_ "GenSigCycleTime" SG_ 985 ACC_ObsTarget8ID 100;
BA_ "GenSigCycleTime" SG_ 985 ACC_ObsTarget8Type 100;
BA_ "GenSigStartValue" SG_ 985 ACC_ObsTarget8LatRange 1023;
BA_ "GenSigCycleTime" SG_ 985 ACC_ObsTarget8LatRange 100;
BA_ "GenSigStartValue" SG_ 985 ACC_ObsTarget8LngRange 2047;
BA_ "GenSigCycleTime" SG_ 985 ACC_ObsTarget8LngRange 100;
BA_ "GenSigCycleTime" SG_ 985 ACC_ObsTarget7ID 100;
BA_ "GenSigCycleTime" SG_ 985 ACC_ObsTarget7Type 100;
BA_ "GenSigStartValue" SG_ 985 ACC_ObsTarget7LatRange 1023;
BA_ "GenSigCycleTime" SG_ 985 ACC_ObsTarget7LatRange 100;
BA_ "GenSigStartValue" SG_ 985 ACC_ObsTarget7LngRange 2047;
BA_ "GenSigCycleTime" SG_ 985 ACC_ObsTarget7LngRange 100;
BA_ "GenSigCycleTime" SG_ 985 ACC_ObsTarget6ID 100;
BA_ "GenSigCycleTime" SG_ 985 ACC_ObsTarget6Type 100;
BA_ "GenSigStartValue" SG_ 985 ACC_ObsTarget6LatRange 1023;
BA_ "GenSigCycleTime" SG_ 985 ACC_ObsTarget6LatRange 100;
BA_ "GenSigStartValue" SG_ 985 ACC_ObsTarget6LngRange 2047;
BA_ "GenSigCycleTime" SG_ 985 ACC_ObsTarget6LngRange 100;
BA_ "GenSigCycleTime" SG_ 985 ACC_ObsTarget5ID 100;
BA_ "GenSigCycleTime" SG_ 985 ACC_ObsTarget5Type 100;
BA_ "GenSigStartValue" SG_ 985 ACC_ObsTarget5LatRange 1023;
BA_ "GenSigCycleTime" SG_ 985 ACC_ObsTarget5LatRange 100;
BA_ "GenSigStartValue" SG_ 985 ACC_ObsTarget5LngRange 2047;
BA_ "GenSigCycleTime" SG_ 985 ACC_ObsTarget5LngRange 100;
BA_ "GenSigCycleTime" SG_ 985 ACC_ObsTarget4ID 100;
BA_ "GenSigCycleTime" SG_ 985 ACC_ObsTarget4Type 100;
BA_ "GenSigStartValue" SG_ 985 ACC_ObsTarget4LatRange 1023;
BA_ "GenSigCycleTime" SG_ 985 ACC_ObsTarget4LatRange 100;
BA_ "GenSigStartValue" SG_ 985 ACC_ObsTarget4LngRange 2047;
BA_ "GenSigCycleTime" SG_ 985 ACC_ObsTarget4LngRange 100;
BA_ "GenSigCycleTime" SG_ 985 ACC_ObsTarget3ID 100;
BA_ "GenSigCycleTime" SG_ 985 ACC_ObsTarget3Type 100;
BA_ "GenSigStartValue" SG_ 985 ACC_ObsTarget3LatRange 1023;
BA_ "GenSigCycleTime" SG_ 985 ACC_ObsTarget3LatRange 100;
BA_ "GenSigStartValue" SG_ 985 ACC_ObsTarget3LngRange 2047;
BA_ "GenSigCycleTime" SG_ 985 ACC_ObsTarget3LngRange 100;
BA_ "GenSigCycleTime" SG_ 985 ACC_ObsTarget2ID 100;
BA_ "GenSigCycleTime" SG_ 985 ACC_ObsTarget2Type 100;
BA_ "GenSigStartValue" SG_ 985 ACC_ObsTarget2LatRange 1023;
BA_ "GenSigCycleTime" SG_ 985 ACC_ObsTarget2LatRange 100;
BA_ "GenSigStartValue" SG_ 985 ACC_ObsTarget2LngRange 2047;
BA_ "GenSigCycleTime" SG_ 985 ACC_ObsTarget2LngRange 100;
BA_ "GenSigCycleTime" SG_ 985 ACC_ObsTarget1ID 100;
BA_ "GenSigCycleTime" SG_ 985 ACC_ObsTarget1Type 100;
BA_ "GenSigStartValue" SG_ 985 ACC_ObsTarget1LatRange 1023;
BA_ "GenSigCycleTime" SG_ 985 ACC_ObsTarget1LatRange 100;
BA_ "GenSigStartValue" SG_ 985 ACC_ObsTarget1LngRange 2047;
BA_ "GenSigCycleTime" SG_ 985 ACC_ObsTarget1LngRange 100;
BA_ "GenSigCycleTime" SG_ 987 ACC_ObsTarget20ID 100;
BA_ "GenSigCycleTime" SG_ 987 ACC_ObsTarget20Type 100;
BA_ "GenSigStartValue" SG_ 987 ACC_ObsTarget20LatRange 1023;
BA_ "GenSigCycleTime" SG_ 987 ACC_ObsTarget20LatRange 100;
BA_ "GenSigStartValue" SG_ 987 ACC_ObsTarget20LngRange 2047;
BA_ "GenSigCycleTime" SG_ 987 ACC_ObsTarget20LngRange 100;
BA_ "GenSigCycleTime" SG_ 987 ACC_ObsTarget19ID 100;
BA_ "GenSigCycleTime" SG_ 987 ACC_ObsTarget19Type 100;
BA_ "GenSigStartValue" SG_ 987 ACC_ObsTarget19LatRange 1023;
BA_ "GenSigCycleTime" SG_ 987 ACC_ObsTarget19LatRange 100;
BA_ "GenSigStartValue" SG_ 987 ACC_ObsTarget19LngRange 2047;
BA_ "GenSigCycleTime" SG_ 987 ACC_ObsTarget19LngRange 100;
BA_ "GenSigCycleTime" SG_ 987 ACC_ObsTarget18ID 100;
BA_ "GenSigCycleTime" SG_ 987 ACC_ObsTarget18Type 100;
BA_ "GenSigStartValue" SG_ 987 ACC_ObsTarget18LatRange 1023;
BA_ "GenSigCycleTime" SG_ 987 ACC_ObsTarget18LatRange 100;
BA_ "GenSigStartValue" SG_ 987 ACC_ObsTarget18LngRange 2047;
BA_ "GenSigCycleTime" SG_ 987 ACC_ObsTarget18LngRange 100;
BA_ "GenSigCycleTime" SG_ 987 ACC_ObsTarget17ID 100;
BA_ "GenSigCycleTime" SG_ 987 ACC_ObsTarget17Type 100;
BA_ "GenSigStartValue" SG_ 987 ACC_ObsTarget17LatRange 1023;
BA_ "GenSigCycleTime" SG_ 987 ACC_ObsTarget17LatRange 100;
BA_ "GenSigStartValue" SG_ 987 ACC_ObsTarget17LngRange 2047;
BA_ "GenSigCycleTime" SG_ 987 ACC_ObsTarget17LngRange 100;
BA_ "GenSigCycleTime" SG_ 987 ACC_ObsTarget16ID 100;
BA_ "GenSigCycleTime" SG_ 987 ACC_ObsTarget16Type 100;
BA_ "GenSigStartValue" SG_ 987 ACC_ObsTarget16LatRange 1023;
BA_ "GenSigCycleTime" SG_ 987 ACC_ObsTarget16LatRange 100;
BA_ "GenSigStartValue" SG_ 987 ACC_ObsTarget16LngRange 2047;
BA_ "GenSigCycleTime" SG_ 987 ACC_ObsTarget16LngRange 100;
BA_ "GenSigCycleTime" SG_ 987 ACC_ObsTarget15ID 100;
BA_ "GenSigCycleTime" SG_ 987 ACC_ObsTarget15Type 100;
BA_ "GenSigStartValue" SG_ 987 ACC_ObsTarget15LatRange 1023;
BA_ "GenSigCycleTime" SG_ 987 ACC_ObsTarget15LatRange 100;
BA_ "GenSigStartValue" SG_ 987 ACC_ObsTarget15LngRange 2047;
BA_ "GenSigCycleTime" SG_ 987 ACC_ObsTarget15LngRange 100;
BA_ "GenSigCycleTime" SG_ 987 ACC_ObsTarget14ID 100;
BA_ "GenSigCycleTime" SG_ 987 ACC_ObsTarget14Type 100;
BA_ "GenSigStartValue" SG_ 987 ACC_ObsTarget14LatRange 1023;
BA_ "GenSigCycleTime" SG_ 987 ACC_ObsTarget14LatRange 100;
BA_ "GenSigStartValue" SG_ 987 ACC_ObsTarget14LngRange 2047;
BA_ "GenSigCycleTime" SG_ 987 ACC_ObsTarget14LngRange 100;
BA_ "GenSigCycleTime" SG_ 987 ACC_ObsTarget13ID 100;
BA_ "GenSigCycleTime" SG_ 987 ACC_ObsTarget13Type 100;
BA_ "GenSigStartValue" SG_ 987 ACC_ObsTarget13LatRange 1023;
BA_ "GenSigCycleTime" SG_ 987 ACC_ObsTarget13LatRange 100;
BA_ "GenSigStartValue" SG_ 987 ACC_ObsTarget13LngRange 2047;
BA_ "GenSigCycleTime" SG_ 987 ACC_ObsTarget13LngRange 100;
BA_ "GenSigCycleTime" SG_ 987 ACC_ObsTarget12ID 100;
BA_ "GenSigCycleTime" SG_ 987 ACC_ObsTarget12Type 100;
BA_ "GenSigStartValue" SG_ 987 ACC_ObsTarget12LatRange 1023;
BA_ "GenSigCycleTime" SG_ 987 ACC_ObsTarget12LatRange 100;
BA_ "GenSigStartValue" SG_ 987 ACC_ObsTarget12LngRange 2047;
BA_ "GenSigCycleTime" SG_ 987 ACC_ObsTarget12LngRange 100;
BA_ "GenSigCycleTime" SG_ 987 ACC_ObsTarget11ID 100;
BA_ "GenSigCycleTime" SG_ 987 ACC_ObsTarget11Type 100;
BA_ "GenSigStartValue" SG_ 987 ACC_ObsTarget11LatRange 1023;
BA_ "GenSigCycleTime" SG_ 987 ACC_ObsTarget11LatRange 100;
BA_ "GenSigStartValue" SG_ 987 ACC_ObsTarget11LngRange 2047;
BA_ "GenSigCycleTime" SG_ 987 ACC_ObsTarget11LngRange 100;
BA_ "GenSigCycleTime" SG_ 881 PCU_DrvMod2 100;
BA_ "GenSigCycleTime" SG_ 881 PCU_SpecialModeSetFB 100;
BA_ "GenSigInvalidValue" SG_ 796 PCU_VcuRdySts "NA";
BA_ "GenSigCycleTime" SG_ 796 PCU_VcuRdySts 100;
BA_ "GenSigCycleTime" SG_ 796 PCU_PowerOutputSts 100;
BA_ "GenSigCycleTime" SG_ 266 EPB_RollingCounter_10A 10;
BA_ "GenSigCycleTime" SG_ 266 EPB_CRCCheck_10A 10;
BA_ "GenSigCycleTime" SG_ 266 ESP_RWU_ParkingAvailForACC 10;
BA_ "GenSigStartValue" SG_ 266 ESP_RWU_ParkingActiveForACC 1;
BA_ "GenSigCycleTime" SG_ 266 ESP_RWU_ParkingActiveForACC 10;
BA_ "GenSigInvalidValue" SG_ 266 EPB_SwitchPositionValid "1";
BA_ "GenSigStartValue" SG_ 266 EPB_SwitchPositionValid 1;
BA_ "GenSigCycleTime" SG_ 266 EPB_SwitchPositionValid 10;
BA_ "GenSigInvalidValue" SG_ 266 EPB_SwitchPosition "3";
BA_ "GenSigCycleTime" SG_ 266 EPB_SwitchPosition 10;
BA_ "GenSigCycleTime" SG_ 266 EPB_Status 10;
BA_ "GenSigCycleTime" SG_ 266 EPB_FailStatus 10;
BA_ "GenSigCycleTime" SG_ 266 EPB_APArequest_Available 10;
BA_ "GenSigInvalidValue" SG_ 266 EPB_AchievedClampForce "31";
BA_ "GenSigStartValue" SG_ 266 EPB_AchievedClampForce 29;
BA_ "GenSigCycleTime" SG_ 266 EPB_AchievedClampForce 10;
BA_ "GenSigSendType" SG_ 1024 NM_message400 1;
BA_ "GenSigSendType" SG_ 1107 NM_message453 1;
BA_ "GenSigSendType" SG_ 2015 Diagnose_message7DF 1;
BA_ "GenSigCycleTime" SG_ 349 ESP_IMUCalibrated 20;
BA_ "GenSigCycleTime" SG_ 349 ESP_RollingCounter_278 20;
BA_ "GenSigCycleTime" SG_ 349 ESP_CRCCheck_278 20;
BA_ "GenSigCycleTime" SG_ 271 IBCU_sOutputRodAct_Q 20;
BA_ "GenSigCycleTime" SG_ 271 IBCU_sOutputRodAct 20;
BA_ "GenSigCycleTime" SG_ 271 IBCU_sOutputRodDriver_Q 20;
BA_ "GenSigCycleTime" SG_ 271 IBCU_sOutputRodDriver 20;
BA_ "GenSigInvalidValue" SG_ 810 TRM_ConnectSts "NA";
BA_ "GenSigCycleTime" SG_ 810 TRM_ConnectSts 100;
BA_ "GenSigCycleTime" SG_ 958 ATS_CurrentDrivingMode 100;
BA_ "GenSigCycleTime" SG_ 890 VMC_RollingCounter_37A 100;
BA_ "GenSigCycleTime" SG_ 890 VMC_CRCCheck_37A 100;
BA_ "GenSigInvalidValue" SG_ 890 VMC_CtrlLevelRRValid "0";
BA_ "GenSigCycleTime" SG_ 890 VMC_CtrlLevelRRValid 100;
BA_ "GenSigInvalidValue" SG_ 890 VMC_CtrlLevelRLyValid "0";
BA_ "GenSigCycleTime" SG_ 890 VMC_CtrlLevelRLyValid 100;
BA_ "GenSigInvalidValue" SG_ 890 VMC_CtrlLevelFRValid "0";
BA_ "GenSigCycleTime" SG_ 890 VMC_CtrlLevelFRValid 100;
BA_ "GenSigInvalidValue" SG_ 890 VMC_CtrlLevelFLValid "0";
BA_ "GenSigCycleTime" SG_ 890 VMC_CtrlLevelFLValid 100;
BA_ "GenSigInvalidValue" SG_ 890 VMC_LvlTarRR "0";
BA_ "GenSigCycleTime" SG_ 890 VMC_LvlTarRR 100;
BA_ "GenSigInvalidValue" SG_ 890 VMC_LvlTarRL "0";
BA_ "GenSigCycleTime" SG_ 890 VMC_LvlTarRL 100;
BA_ "GenSigInvalidValue" SG_ 890 VMC_LvlTarFR "0";
BA_ "GenSigCycleTime" SG_ 890 VMC_LvlTarFR 100;
BA_ "GenSigInvalidValue" SG_ 890 VMC_LvlTarFL "0";
BA_ "GenSigCycleTime" SG_ 890 VMC_LvlTarFL 100;
BA_ "GenSigCycleTime" SG_ 890 VMC_EcasModeRELSts 100;
BA_ "GenSigCycleTime" SG_ 890 VMC_EcasModeFRTSts 100;
BA_ "GenSigCycleTime" SG_ 890 VMC_EcasModeCHASts 100;
BA_ "GenSigInvalidValue" SG_ 890 VMC_CtrlLevelRR "32767";
BA_ "GenSigCycleTime" SG_ 890 VMC_CtrlLevelRR 100;
BA_ "GenSigInvalidValue" SG_ 890 VMC_CtrlLevelRL "32767";
BA_ "GenSigCycleTime" SG_ 890 VMC_CtrlLevelRL 100;
BA_ "GenSigInvalidValue" SG_ 890 VMC_CtrlLevelFR "32767";
BA_ "GenSigCycleTime" SG_ 890 VMC_CtrlLevelFR 100;
BA_ "GenSigInvalidValue" SG_ 890 VMC_CtrlLevelFL "32767";
BA_ "GenSigCycleTime" SG_ 890 VMC_CtrlLevelFL 100;
BA_ "GenSigCycleTime" SG_ 890 VMC_EcasModeVal 100;
BA_ "GenSigCycleTime" SG_ 890 VMC_EcdcMode 100;
BA_ "GenSigCycleTime" SG_ 890 VMC_EcasMode 100;
VAL_ 652 GW_MFS_HODCalibratedStatus 0 "Not Calibrated" 1 "Calibrated" ;
VAL_ 652 GW_MFS_HODLinStatus 0 "no fault" 1 "fault" ;
VAL_ 652 GW_MFS_HODAppStatus 0 "no fault" 1 "fault" ;
VAL_ 652 GW_MFS_HODSenserStatus 0 "no fault" 1 "fault" ;
VAL_ 652 GW_MFS_HODSystemStatus 0 "no fault" 1 "fault" 2 "block" 3 "reserved" ;
VAL_ 652 GW_MFS_handsoffAbilityDetect 0 " hands off" 1 " hands on without takeover ability" 2 " hands on with takeover ability" 3 " unkown" 4 "reserved" ;
VAL_ 652 GW_MFS_handsoffDetectResult 0 "no Touch" 1 "Left Wheel Touch" 2 "Right Wheel Touch" 3 "Rear Wheel Touch" 4 "Left Wheel Grip" 5 "Right Wheel Grip" 6 "Both side touch" 7 " Both side Grip" ;
VAL_ 652 GW_MFS_DiagInfoSW_28C 0 "复位" 1 "变种信息错误" 2 "电源高于16V" 3 "电源低于9V" 4 "reversed" 7 "invalid" ;
VAL_ 652 GW_MFS_GearshiftReduce_switch 0 "按键未按下" 1 "按键按下" 2 "假按键" 3 "Error" ;
VAL_ 652 GW_MFS_GearshiftPlus_switch 0 "按键未按下" 1 "按键按下" 2 "假按键" 3 "Error" ;
VAL_ 652 GW_MFS_EPS_switch 0 "按键未按下" 1 "按键按下" 2 "假按键" 3 "Error" ;
VAL_ 652 GW_MFS_ERSReduce_switch 0 "按键未按下" 1 "按键按下" 2 "假按键" 3 "Error" ;
VAL_ 652 GW_MFS_ERSPlus_switch 0 "按键未按下" 1 "按键按下" 2 "假按键" 3 "Error" ;
VAL_ 652 GW_MFS_IACCenable_switch_signal 0 "按键未按下" 1 "按键按下" 2 "假按键" 3 "Error" ;
VAL_ 652 GW_MFS_LIM_switch_signal 0 "按键未按下" 1 "按键按下" 2 "假按键" 3 "Error" ;
VAL_ 652 GW_MFS_DIST_switch_signal 0 "按键未按下" 1 "按键按下" 2 "假按键" 3 "Error" ;
VAL_ 652 GW_MFS_SETReduce_switch_signal 0 "按键未按下" 1 "按键按下" 2 "假按键" 3 "Error" ;
VAL_ 652 GW_MFS_RESPlus_switch_signal 0 "按键未按下" 1 "按键按下" 2 "假按键" 3 "Error" ;
VAL_ 652 GW_MFS_Cancle_switch_signal 0 "按键未按下" 1 "按键按下" 2 "假按键" 3 "Error" ;
VAL_ 652 GW_MFS_Crusie_switch_signal 0 "按键未按下" 1 "按键按下" 2 "假按键" 3 "Error" ;
VAL_ 652 GW_MFS_DISTReduce_switch_signal 0 "按键未按下" 1 "按键按下" 2 "假按键" 3 "Error" ;
VAL_ 652 GW_MFS_DISTPlus_switch_signal 0 "按键未按下" 1 "按键按下" 2 "假按键" 3 "Error" ;
VAL_ 817 TCU_TransTempWarning 0 "No warning request" 1 "Transmission hot" 2 "Transmission overheat" 3 "Transmission cold" ;
VAL_ 817 TCU_TransFaultLevel 0 "Normal" 1 "Fault level1(just store DTC)" 2 "Fault level2(store DTC&warning)" 3 "Fault level3(Limphome)" 4 "Fault level4(No DCT Shaft)" 5 "Fault level5(Drive open)" ;
VAL_ 817 TCU_PowerplantStatusIPReq 0 "No Display request" 1 "shift lever after powerplant status is running" ;
VAL_ 817 TCU_ParkSelectIPReq 0 "No Display request" 1 "Only Shift to Park when vehicle is stationary" ;
VAL_ 817 TCU_ParkRelMPosnIPReq 0 "No Display request" 1 "Move Shift Lever to right" ;
VAL_ 817 TCU_ParkRelAPosnIPReq 0 "No Display request" 1 "Press Brake to release park" 2 "Press Unlock Button to release  park" 3 "slow speed down to shift lever" ;
VAL_ 817 TCU_GearForDisplay 0 "Initial value" 1 "1st gear" 2 "2nd gear" 3 "3rd gear" 4 "4th gear" 5 "5th gear" 6 "6th gear" 7 "Parking" 8 "Reverse" 9 "Neutral" 10 "D range" 11 "S range" 12 "7th gear" 13 "8th gear" 14 "Unavailable" 15 "Invalid" ;
VAL_ 817 TCU_FailureLamp 0 "OFF" 1 "ON" ;
VAL_ 817 TCU_ESLFaultIPReq 0 "No Display request" 1 "Shift Lever malfunction, Service Required" ;
VAL_ 817 TCU_ARCFaultIPReq 0 "No Display request" 1 "Park  Actuator Fault, Service Required." ;
VAL_ 431 TCU_TipSwitchSignal 0 "Not Active" 1 "Tip plus active" 2 "Tip minus active" 3 "Invalid" ;
VAL_ 431 TCU_THOState 0 "initial value" 1 "prepare phase" 2 "speed phase" 3 "torque phase" 4 "reinstatement " 5 "THO not active" 6 "reserved" 7 "invalid" ;
VAL_ 431 TCU_STLKfailure 0 "normal" 1 "error" ;
VAL_ 431 TCU_ShiftPostionValid 0 "valid" 1 "invalid" ;
VAL_ 431 TCU_GearShiftPosition 0 "Parking" 1 "Reverse" 2 "Neutral" 3 "D" 4 "D3" 5 "D2" 6 "L" 7 "M/S" 8 "Reserved" 13 " Initial value" 14 " Unreliable" 15 " Invalid" ;
VAL_ 431 TCU_ActualPreselectGear 0 "Initial" 1 "1st gear" 2 "2nd gear" 3 "3rd gear" 4 "4th gear" 5 "5th gear" 6 "6th gear" 7 "7th gear" 8 "8th gear" 9 "Reverse" 10 "Neutral" 11 "Reserved" 15 "Invalid" ;
VAL_ 431 TCU_ActualDrivingGearValid 0 "valid" 1 "invalid" ;
VAL_ 431 TCU_ActualDrivingGear 0 "Neutral" 1 "1st gear" 2 "2nd gear" 3 "3rd gear" 4 "4th gear" 5 "5th gear" 6 "6th gear" 7 "7th gear" 8 "8th gear" 9 "Reverse" 10 "Parking" 11 "Reserved" 13 "Reserved" 14 "Reserved" 15 "Invalid" ;
VAL_ 800 GW_ADSSecOCVerifyFailureFlag 0 "Not Failure" 1 "Failure" ;
VAL_ 800 GW_DCANDiagSts 0 "DCAN无诊断报文" 1 "DCAN有诊断报文" ;
VAL_ 800 GW_GatewayFailureFlag 0 "Not Failure" 1 "Failure" ;
VAL_ 800 GW_OTAmode 0 "OTAinactive" 1 "OTAmode1-车内升级安全执行中" 2 " OTAmode2-车外升级安全执行中" 3 "OTAmode3-Reserved" 4 "OTAmode4-车内升级非安全执行中" 5 "OTAmode5-车外升级非安全执行中" 6 "OTAmode6-车内升级条件检测中" 7 "OTAmode7-车外升级条件检测中" 7 "Reserved" ;
VAL_ 800 GW_ResetReq 0 "Valid" 1 "THU" 2 " AMP" 3 "ADS/ADC" 4 " FC/LAS" 5 "FR/ACC" 6 "FLR" 7 "FRR" 8 "RLR/LCDAL" 9 "RRR/LCDAR" 10 "LVSM" 11 "INS" 12 "APA" 13 "BCML/BCM" 14 "GW/BCMR" 15 "EMS" 16 "PCU" 17 "BMS" 18 "PEU" 19 "OBC" 20 "TCU" 21 "IPUMP" 22 "ACM" 23 "ESL" 24 "PTS" 25 "ESCL" 26 "TMS/AC" 27 "DKC/RFBT/BLEM" 28 "WLCM" 29 "EPBI" 30 "IBCU" 31 "RBM" 32 "EPS" 33 "EPS2" 34 "DSM" 35 "IP" 36 "SLCM" 37 "HUD" 38 "GPEU" 39 "PDU" 40 "RPEU" 41 "VMC" 43 "DPEU" 44 "NFC-Enter" 45 "PATC" 46 "VMC2" 47 "RCCS" 48 "TRM" 49 "PDCU" 50 "BDCR" 51 "mADC" 52 "EPB" 53 "Reserve" 127 "Invalid" ;
VAL_ 922 LAS_RoadFeature 0 " No Object (无目标)" 1 " Speed Bump  (减速带)" 2 "  Reserved" 3 "  Reserved" 4 "  Reserved" 5 "  Reserved" 6 "  Reserved" 15 " Invalid" ;
VAL_ 922 LAS_RD4LongDistence 0 "0-250m" 251 "Reserved" 255 "Out of Range" ;
VAL_ 922 LAS_RD3LongDistence 0 "0-250m" 251 "Reserved" 255 "Out of Range" ;
VAL_ 922 LAS_RD2LongDistence 0 "0-250m" 251 "Reserved" 255 "Out of Range" ;
VAL_ 922 LAS_RD1LongDistence 0 "0-250m" 251 "Reserved" 255 "Out of Range" ;
VAL_ 922 LAS_RD4RoadInforAvailable 0 " Not Available" 1 " Available Measured" 2 " Predicted" 3 " Predicted close-range outside FOV" ;
VAL_ 922 LAS_RD3RoadInforAvailable 0 " Not Available" 1 " Available Measured" 2 " Predicted" 3 " Predicted close-range outside FOV" ;
VAL_ 922 LAS_RD2RoadInforAvailable 0 " Not Available" 1 " Available Measured" 2 " Predicted" 3 " Predicted close-range outside FOV" ;
VAL_ 922 LAS_RD1RoadInforAvailable 0 " Not Available" 1 " Available Measured" 2 " Predicted" 3 " Predicted close-range outside FOV" ;
VAL_ 922 LAS_TSRSpeedLimitType 0 "Unknown" 1 "Speed-Limit Sign" 2 "Road Camera" 3 "Interval Velocity" ;
VAL_ 922 LAS_OverspeedSoundWarningEnSt 0 "Off" 1 "On" ;
VAL_ 922 LAS_TSREnable 0 "off" 1 "on" ;
VAL_ 922 LAS_HMAEnableStatus 0 "off" 1 "on" ;
VAL_ 922 LAS_HMALightDistribution 0 " High beam not recommended" 1 " High beam recommended" ;
VAL_ 922 LAS_HMAStatus 0 " Off" 1 " Standby" 2 " Active" 3 " Failure" ;
VAL_ 922 LAS_TSRHostSpdLimitUnits 0 "no display" 1 "unit kph" 2 "unit mph" 3 "reserved" ;
VAL_ 922 LAS_TSRHostSpdLimit 0 "no speed limit detected" 1 "SL5" 2 "SL10" 3 "SL15" 4 "SL20" 5 "SL25" 6 "SL30" 7 "SL35" 8 "SL40" 9 "SL45" 10 "SL50" 11 "SL55" 12 "SL60" 13 "SL65" 14 "SL70" 15 "SL75" 16 "SL80" 17 "SL85" 18 "SL90" 19 "SL95" 20 "SL100" 21 "SL105" 22 "SL110" 23 "SL115" 24 "SL120" 25 "SL125" 26 "SL130" 27 "SL135" 28 "SL140" 29 "SL145" 30 "SL150" 31 "SL155" 32 "SL160" 33 " Reserved" 254 " Unlimited" 255 " SLEND" ;
VAL_ 922 LAS_TSRStatus 0 "off" 1 "fusion mode" 2 "vision only mode" 3 "navigation only mode" 4 "Failure" 5 "reserved" 6 "reserved" 7 "Invalid" ;
VAL_ 922 LAS_FrontCameraCalibrationStatus 0 "Calibration is ok" 1 "Calibration In Process" 2 "Calibration never done" 3 "Calibration Failed" ;
VAL_ 922 LAS_FrontCameraFailureStatus 0 "No Error" 1 "camera blocked" 2 "temporary failure" 3 "permanent failure" ;
VAL_ 922 LAS_OverspeedWarningOffset 0 "-10~20km/h" 31 "Reserved" 47 "Invalid" ;
VAL_ 922 LAS_OverspeedWarningEnableStatus 0 "OFF" 1 "ON" ;
VAL_ 922 LAS_OverspeedSoundWarning 0 " No Warning" 1 " Warning" ;
VAL_ 922 LAS_OverspeedVisualWarning 0 " No Warning" 1 " Warning" ;
VAL_ 922 LAS_CrosswalkLngRange_HLane 0 "0-250m" 251 "Reserved" 255 "Out of Range" ;
VAL_ 784 AMP_VOLSpeedLevSETStatus 0 "Inactive" 1 "关闭" 2 "L1" 3 "L2" 4 "L3" 5 "reserved" ;
VAL_ 784 AMP_VOLSpeedEnableSETStatus 0 "Inactive" 1 "关闭" 2 "打开" 3 "reserved" ;
VAL_ 784 AMP_AllAlarmFailureStatus 0 "No Failure" 1 "Failure" ;
VAL_ 784 AMP_IPEnableAlarmFailureStatus 0 "No Failure" 1 "Failure" ;
VAL_ 784 AMP_MUTESETStatus 0 "Inactive" 1 "非静音" 2 "静音" 3 "reserved" ;
VAL_ 784 AMP_SPKChannelSETStatus 0 "Inactive" 1 "头枕模式（只有头枕发音，其余扬声器不发音）" 2 "全部扬声器发音" 3 "头枕关闭（头枕不发音，其余扬声器发音）" 4 "reserved" ;
VAL_ 784 AMP_TouchVolSETStatus 0 "Inactive" 1 "低" 2 "中" 3 "高" 4 "关" 5 "reserved" ;
VAL_ 784 AMP_AlarmStyleSETStatus 0 "Inactive" 1 "类型1" 2 "类型2" 3 "类型3" 4 "reserved" ;
VAL_ 784 AMP_LRHeadSPKBalanceSETStatus 0 "Inactive" 1 "-15（最左面）" 2 "-14" 16 "0（中间位置）" 30 "14" 31 "15（最右面）" ;
VAL_ 784 AMP_AlarmVolSETStatus 0 "Inactive" 1 "低" 2 "中" 3 "高" ;
VAL_ 784 AMP_HeadSPKVolSETStatus 0 "Inactive" 1 "0（MUTE）" 2 "Step1" 40 "Step39" 41 "Step40" 42 "reserved" ;
VAL_ 784 AMP_HeadSPKMediaSETStatus 0 "Inactive" 1 "OFF" 2 "ON" 3 "reserved" ;
VAL_ 784 AMP_HeadSPKTelSETStatus 0 "Inactive" 1 "OFF" 2 "ON" 3 "reserved" ;
VAL_ 784 AMP_HeadSPKNIVISETStatus 0 "Inactive" 1 "OFF" 2 "ON" 3 "reserved" ;
VAL_ 1000 BCM_SOF_t_STATE 0 "deviation > 15%" 1 "deviation <15%" 2 "deviation < 10%" 3 "invalid" ;
VAL_ 1000 BCM_SOF_V2_STATE 0 "deviation > 15%" 1 "deviation <15%" 2 "deviation < 10%" 3 "invalid" ;
VAL_ 1000 BCM_SOF_V1_STATE 0 "deviation 800mV" 1 "deviation 400mV" 2 "deviation 400mV" 3 "invalid" ;
VAL_ 1000 BCM_SOF_Q_STATE 0 "deviation > 15%" 1 "deviation <15%" 2 "deviation < 10%" 3 "invalid" ;
VAL_ 1000 BCM_SOC_STATE 0 "deviation > 15%" 1 "deviation <15%" 2 "deviation < 10%" 3 "invalid" ;
VAL_ 1000 BCM_SOF_t 1023 "Invalid" ;
VAL_ 1000 BCM_SOF_V2 255 "Invalid" ;
VAL_ 1000 BCM_SOF_V1 255 "Invalid" ;
VAL_ 1000 BCM_SOF_Q 255 "Invalid" ;
VAL_ 1000 BCM_SOC 101 "reserved" 255 "Invalid" ;
VAL_ 999 BCM_Resp_Error 0 "No error" 1 "Error" ;
VAL_ 999 BCM_FLAG_INCONSISTENCY 0 "no battery inconsistency" 1 "battery inconsistency" ;
VAL_ 999 BCM_Status_Current 0 "No error" 1 "Error Open circuit" 2 "HW defect (ADC defect)" 3 "LIN saturation (no HW defect)" ;
VAL_ 999 BCM_Status_Voltage 0 "No error" 1 "Error Open circuit" 2 "HW defect (ADC defect)" 3 "LIN saturation (no HW  defect)" ;
VAL_ 999 BCM_Status_Temp 0 "No error" 1 "not used" 2 "HW defect (ADC defect)" 3 "LIN saturation (no HW  defect)" ;
VAL_ 999 BCM_ERROR_Calib 0 "No error" 1 "Error" ;
VAL_ 999 BCM_ERROR_IDENT 0 "No error" 1 "Error" ;
VAL_ 999 BCM_IBATT_QUIESCENT 253 "Overflow" 254 "Out of bounds" 255 "Invalid" ;
VAL_ 999 BCM_T_BATT 146 "reserved" 255 "Invalid" ;
VAL_ 999 BCM_U_BATT 15361 "reserved" 16383 "Invalid" ;
VAL_ 999 BCM_I_RANGE 0 "current Range [-1, 1A]" 1 "current Range [-200, 200A]" 2 "current Range [-1500,
1500A]" 3 "unsigned" ;
VAL_ 906 GW_MFS_WeChat_switch_signal 0 "按键未按下" 1 "按键按下" 2 "假按键" 3 "Error" ;
VAL_ 906 GW_MFS_AVM_switch 0 "按键未按下" 1 "按键按下" 2 "假按键" 3 "Error" ;
VAL_ 906 GW_MFS_DiagInfoSW_38A 0 "复位" 1 "变种信息错误" 2 "电源高于16V" 3 "电源低于9V" 4 "reversed" 7 "invalid" ;
VAL_ 906 GW_MFS_Cust_switch 0 "按键未按下" 1 "按键按下" 2 "假按键" 3 "Error" ;
VAL_ 906 GW_MFS_DVR_switch 0 "按键未按下" 1 "按键按下" 2 "假按键" 3 "Error" ;
VAL_ 906 GW_MFS_Mode_switch 0 "按键未按下" 1 "按键按下" 2 "假按键" 3 "Error" ;
VAL_ 906 GW_MFS_VolReduce_switch 0 "按键未按下" 1 "按键按下" 2 "假按键" 3 "Error" ;
VAL_ 906 GW_MFS_VolPlus_switch 0 "按键未按下" 1 "按键按下" 2 "假按键" 3 "Error" ;
VAL_ 906 GW_MFS_UP_switch 0 "按键未按下" 1 "按键按下" 2 "假按键" 3 "Error" ;
VAL_ 906 GW_MFS_Speech_switch 0 "按键未按下" 1 "按键按下" 2 "假按键" 3 "Error" ;
VAL_ 906 GW_MFS_SeekPlus_switch 0 "按键未按下" 1 "按键按下" 2 "假按键" 3 "Error" ;
VAL_ 906 GW_MFS_Right_switch 0 "按键未按下" 1 "按键按下" 2 "假按键" 3 "Error" ;
VAL_ 906 GW_MFS_OK_switch 0 "按键未按下" 1 "按键按下" 2 "假按键" 3 "Error" ;
VAL_ 906 GW_MFS_Mute_switch 0 "按键未按下" 1 "按键按下" 2 "假按键" 3 "Error" ;
VAL_ 906 GW_MFS_Left_switch 0 "按键未按下" 1 "按键按下" 2 "假按键" 3 "Error" ;
VAL_ 906 GW_MFS_Hungup_switch_signal 0 "按键未按下" 1 "按键按下" 2 "假按键" 3 "Error" ;
VAL_ 906 GW_MFS_Down_switch 0 "按键未按下" 1 "按键按下" 2 "假按键" 3 "Error" ;
VAL_ 906 GW_MFS_Answer_switch_signal 0 "按键未按下" 1 "按键按下" 2 "假按键" 3 "Error" ;
VAL_ 906 GW_MFS_SeekReduce_switch 0 "按键未按下" 1 "按键按下" 2 "假按键" 3 "Error" ;
VAL_ 610 PEPS_RemoteStartKeyStatus 0 "invalid" 1 " pressed" 2 "not pressed " 3 "reserve" ;
VAL_ 610 PEPS_APA_PowerMirrorFoldFeedback 0 "InActive " 1 "Fold" 2 "Open" 3 "Reserved" ;
VAL_ 610 PEPS_APARemoteParkingOff 0 " Not Pressed" 1 " Pressed" ;
VAL_ 610 PEPS_KeyStandbyPositionIndicator 0 "Inactive" 1 "ON" ;
VAL_ 610 PEPS_PEPSFailStatus 0 "No Error" 1 "Error" ;
VAL_ 610 PEPS_PowerDistributionFaultBit 0 "No Error" 1 "Error" ;
VAL_ 610 PEPS_IMMOFeedback 0 "Inactive非认证状态" 1 "Authenticating认证中
0x2=Success成功" 3 "Failed失败" ;
VAL_ 610 PEPS_EngineStartupInhibitFB 0 "inactive " 1 "Inhibit succes" ;
VAL_ 610 PEPS_RemoteStartFeedback 0 " 无反馈" 1 " 启动成功" 2 " 连续启动次数过多" 3 " 整车电量不足" 4 " 车门或引擎盖或行李箱未关闭" 5 " 遥控钥匙在车内" 6 " 防盗激活" 7 " 紧急报警灯光激活" 8 " 整车不在P档" 9 " 车速不为0" 10 " 发动机已经运行" 11 " 电子手刹未夹紧" 12 " 油量不足" 13 " 启动系统故障" 14 " 发动机机油压力过低" 15 " 发动机冷却液温度过高" 16 " 电喷系统故障" 17 " 运行时间到正常熄火" 18 " 环境温度过低" 19 "周边防盗未处于设防状态" 20 "远程/遥控熄火成功" 21 "启动时间已达30min 上限" 22 " Reserved" ;
VAL_ 610 PEPS_EngineStartupInhibitSts 0 "Not inhibit " 1 "Inhibit" ;
VAL_ 610 PEPS_PowerDistributionStatus 0 " OFF" 1 " ACC" 2 " ON" 3 " Start." ;
VAL_ 610 PEPS_UnallowStartSignal_Not_PN 0 "Inactive" 1 "未在P/N档" ;
VAL_ 610 PEPS_IMMOFailedAlarmsignal 0 "Inactive" 1 "IMMO与EMS认证失败" ;
VAL_ 610 PEPS_UnallowStart_ESCL_LOCK 0 "Inactive" 1 "ESCL未解锁" ;
VAL_ 610 PEPS_UnallowStart_ESCL_Error 0 "Inactive" 1 "ESCL故障" ;
VAL_ 610 PEPS_StartIndicatorSignal 0 "Inactive" 1 "请踩下制动踏板提示" ;
VAL_ 610 PEPS_StartupButtonSignal 0 " OFF" 1 " ON" 2 " Error" 3 " 不可用" ;
VAL_ 610 PEPS_APA_CloseWinFeedback 0 "InActive " 1 "Success " 2 "Failed " 3 "Reserved" ;
VAL_ 610 PEPS_RemoteControlACReq 0 "No Request" 1 "AC Start" 2 "Reserved" ;
VAL_ 610 PEPS_RemoteAPADoneKeyOffReq 0 " invalid" 1 " request" 2 " not request" 3 " reserved" ;
VAL_ 610 PEPS_APA_Engine0ffFeedback 0 "InActive " 1 "Success " 2 "Failed " 3 "Reserved" ;
VAL_ 610 PEPS_APA_LockFeedback 0 "InActive " 1 "Success " 2 "Failed " 3 "Reserved" ;
VAL_ 610 PEPS_APARemoteParkingOn 0 " Not Pressed" 1 " Pressed" ;
VAL_ 820 DSM_RightMirrorUpDownSts 0 "Inactive" 1 "0%~100%" 204 "Reserved" 255 "Invalid" ;
VAL_ 820 DSM_RightMirrorLeftRightSts 0 "Inactive" 1 "0%~100%" 204 "Reserved" 255 "Invalid" ;
VAL_ 820 DSM_LeftMirrorLeftRightSts 0 "Inactive" 1 "0%~100%" 204 "Reserved" 255 "Invalid" ;
VAL_ 820 DSM_LeftMirrorUpDownSts 0 "Inactive" 1 "0%~100%" 204 "Reserved" 255 "Invalid" ;
VAL_ 917 TBOX_EseUpdataHUWakeUpReq 0 " No Request" 1 "EseUpdataHUWakeUpReq" ;
VAL_ 917 TBOX_RemoteInstallReq 0 " 无请求" 1 " 预约刷写" 2 " 远程刷写" 3 "静默升级" ;
VAL_ 917 TBOX_RemotePaVentilatieReq 0 " No Request" 1 "Wind_level1" 2 " Wind_level2" 3 " Wind_level3" 4 " Reserved" 6 "close" 7 "Reserved" ;
VAL_ 917 TBOX_RemoteDrVentilatieReq 0 " No Request" 1 "Wind_level1" 2 " Wind_level2" 3 " Wind_level3" 4 " Reserved" 6 "close" 7 "Reserved" ;
VAL_ 917 TBOX_BCallStatus 0 "  IDLE" 1 " On the phone" 2 " Calling" 3 " being Called(somebody call)" 4 "Call Ended" 5 " Reserved" 7 " Invalid" ;
VAL_ 917 TBOX_AudioRequest 0 " No Request" 1 "Ecall request" 2 "Becall request" 3 " Invalid" ;
VAL_ 917 TBOX_ChangePartStatus 0 "NotChange" 1 "Changed" ;
VAL_ 917 TBOX_CallStatus 0 "  IDLE" 1 " On the phone" 2 " Calling" 3 " being Called(somebody call)" 4 "Call Ended" 5 " Reserved" 7 " Invalid" ;
VAL_ 917 TBOX_RemoteAirCleanReq 0 " No Request" 1 "AC clean open" 2 " AC clean close" 3 " Invalid" ;
VAL_ 917 TBOX_RemoteAirQualityInquire 0 " No Request" 1 "Request
0x2 = Reserved" 3 " Invalid" ;
VAL_ 917 TBOX_RemoteSteerWheelHotReq 0 " No Request" 1 "Hot_Request" 2 " close " 3 " Reserved " ;
VAL_ 917 TBOX_RemoteDriverSeatHotReq 0 " No Request" 1 "Hot_level1" 2 " Hot_level2" 3 "Hot_level3" 4 " Reserved" 6 "close" 7 "Reserved" ;
VAL_ 917 TBOX_RemotePassangerSeatHotReq 0 " No Request" 1 "Hot_level1" 2 " Hot_level2" 3 " Hot_level3" 4 " Reserved" 6 "close" 7 "Reserved" ;
VAL_ 917 TBOX_SearchCarReq 0 " No Request" 1 "Light" 2 "Horn" 3 "Light And Horn" ;
VAL_ 917 TBOX_RmoteTrunk 0 " No Request" 1 "Close" 2 "Open" 3 " Reserved" ;
VAL_ 917 TBOX_RmoteRoof 0 " No Request" 1 "Close" 2 "Open" 3 " Reserved." ;
VAL_ 917 TBOX_RemoteACStartupReq 0 " No Request" 1 "AC Start" 2 " AC Stop" 3 " Invalid" ;
VAL_ 917 TBOX_VehicleStatusDemandReq 0 " No Request" 1 "Request" ;
VAL_ 917 TBOX_RemoteStartRunTime 0 "NoReq" 1 "10min" 2 "15min" 3 "20min" 4 "25min" 5 "30min" 6 "Reserved" 7 "Invalid" ;
VAL_ 917 TBOX_VINMatchStatus 0 "Not matched" 1 "matched" 2 "matched unsuccess" 3 "Invalid" ;
VAL_ 917 TBOX_VINReq 0 " No Request" 1 "Request
0x2 = Reserved" 3 " Invalid" ;
VAL_ 917 TBOX_ACTempValueReq 0 "0x00=No Req" 1 "LO" 2 "18~32℃" 31 "HI （步长0.5，偏移量17）
电动空调=0x00=No Req" 2 "Cold level3" 4 "Cold level2" 6 "Cold level1" 16 "Hot level1" 18 "Hot level2" 20 "Hot level3" ;
VAL_ 917 TBOX_CarRemind 0 " inactive" 1 " active" ;
VAL_ 917 TBOX_RemoteEngineStartupReq 0 " No Request" 1 "Engine Start" 2 " Engine Stop" 3 " Invalid" ;
VAL_ 917 TBOX_EngineStartupInhibit 0 " No Inhibit" 1 " Inhibit Engine Start" 2 " Reserved" 3 " Invalid" ;
VAL_ 917 TBOX_LockCommand 0 " No Request" 1 " Remote Lock" 2 " Remote Unlock" 3 " Invalid" ;
VAL_ 917 TBOX_APARemoteDriveReq 0 "No Request" 1 "Forward" 2 "Backward" 3 "Turnleft" 4 "Turnright" 5 "SteeringReturn" 7 "Reserved" ;
VAL_ 917 TBOX_HZPFunctionReq 0 "inactive" 1 "parkin" 2 "parkout" 3 "rma" 4 "reserved" ;
VAL_ 917 TBOX_HZPControlEnable 0 "inactive" 1 "start" 2 "end" 3 "cancel" 4 "suspend" 5 "recover" 6 "disconnect(reserved)" 7 "reserved" ;
VAL_ 917 TBOX_SignalStrength 0 "No Signal" 1 "1st Level" 2 "2nd Level" 3 "3rd Level" 4 "4th Level" 5 "Reserved" ;
VAL_ 917 TBOX_SignalType 0 "No Signal" 1 "2G" 2 "3G" 3 "4G" 4 "5G" 5 "Reserved" ;
VAL_ 917 TBOX_APA_SignalDelay 0 "Inactive" 1 "Lessthan500ms" 1 "500ms-1s" 2 "1s-1.5s" 3 "1.5s-2s" 4 "2s-2.5s" 5 "2.5s-3s" 6 "3s-3.5s" 7 "3.5s-4s" 8 "4s-4.5s" 9 "4.5s-5s" 10 "Reserved" ;
VAL_ 917 TBOX_APA_VideoDelay 0 "Inactive" 1 "Lessthan500ms" 1 "500ms-1s" 2 "1s-1.5s" 3 "1.5s-2s" 4 "2s-2.5s" 5 "2.5s-3s" 6 "3s-3.5s" 7 "3.5s-4s" 8 "4s-4.5s" 9 "4.5s-5s" 10 "Reserved" ;
VAL_ 917 TBOX_AVM_DisplayForm 0 "No Request" 1 "All+Front" 2 "All+Left" 3 "All+Right" 4 "All+rear" 5 "Reserved" ;
VAL_ 917 TBOX_TurnRight 0 " Not Pressed" 1 " Pressed" ;
VAL_ 917 TBOX_TurnLeft 0 " Not Pressed" 1 " Pressed" ;
VAL_ 917 TBOX_Verticalforward 0 " Not Pressed" 1 " Pressed" ;
VAL_ 917 TBOX_Verticalbackward 0 " Not Pressed" 1 " Pressed" ;
VAL_ 917 TBOX_APAPOCModeSelect 0 "No Request" 1 "Left Park Out" 2 "Right Park Out" 3 "No Slot Available" 4 "Reserved" 7 "Invalid" ;
VAL_ 917 TBOX_APAFuctionSelection 0 " Not Select" 1 " Parking Out" 2 "Vertical In&Out" 3 "ParkHoming" ;
VAL_ 917 TBOX_APAManeuverSuspend 0 " Not Pressed" 1 " Pressed" ;
VAL_ 917 TBOX_APAManeuverStart 0 " Not Pressed" 1 " Pressed" ;
VAL_ 917 TBOX_APAManeuverCancel 0 " Not Pressed" 1 " Pressed" ;
VAL_ 917 TBOX_APAmoduleEnable 0 "Off" 1 "Inactive" 2 "On" 3 "Reserved" ;
VAL_ 917 TBOX_RemoteDisReq 0 "Inactive" 1 "Active" ;
VAL_ 917 TBOX_VehicleVedioDetectReq 0 " No Request" 1 "Request" 2 " Reserved" 3 "Invalid" ;
VAL_ 917 TBOX_RemoteDetectReq 0 " InActive" 1 "Active" 2 " Reserved" 3 " Invalid" ;
VAL_ 394 TCU_APAShiftGearRequestEnable 0 "No Request Received" 1 "Control enabled" 2 "Control disable(预留)" 3 "invalid" ;
VAL_ 394 TCU_APAdriverInterruption 0 "No Interruption" 1 "Interruption" 2 "Reserved" 3 "invalid" ;
VAL_ 586 ESL_HALLStatus 0 "default" 1 "Reserved" 63 "M/S~M-" 127 "M-" 159 "M/S~M+" 187 "Auto~M/S" 191 "M/S" 223 "M+" 231 "Down1~Down2" 239 "Down2" 243 "Auto~Down1" 247 "Down1" 249 "Auto~UP1" 251 "Auto" 252 "UP1~UP2" 253 "UP1" 254 "UP2" ;
VAL_ 586 ESL_DriveModeFaultStatus 0 "normal" 1 "Degraded" 2 "Fault" 3 "Reserved" ;
VAL_ 586 ESL_UnLockButtonFaultStatus 0 "normal" 1 "Reserve" 2 "Fault" 3 "Reserved" ;
VAL_ 586 ESL_EPBButton_FaultStatus 0 "normal" 1 "Reserve" 2 "Fault" 3 "Reserved" ;
VAL_ 586 ESL_UnLockButtonPositionStatus 0 "Not Pressed" 1 "Pressed" 2 "Reserved" 3 "Invalid" ;
VAL_ 586 ESL_EPBButton_PositionStatus 0 "Not Pressed" 1 "Pressed" 2 "Reserved" 3 "Invalid" ;
VAL_ 586 ESL_ResetSts 0 "Valid" 1 "GW请求复位" 2 "自身判断复位" 3 "不满足复位条件" 4 "Reserve" 7 "Invalid" ;
VAL_ 586 ESL_TcugearRef 0 " unknow" 1 "Parking" 2 "Reverse" 3 "Neutral" 4 "D" 5 "D3" 6 "D2" 7 "L" 8 "M_or_S" 9 "Reserved" 10 "Reserved" 11 "Reserved" 12 "Reserved" 13 "Reserved" 14 "Reserved" ;
VAL_ 586 ESL_DriveModeRequest 0 " Auto" 1 " Manual/Sport" 2 " Reserved" 15 " Invalid" ;
VAL_ 586 ESL_DriverParkButtonFaultStatus 0 "normal" 1 "Reserved" 2 "Fault" 3 "Reserved" ;
VAL_ 586 ESL_DriverParkRequest 0 " Driver Park Not Requested" 1 " Driver Park Requested" 2 "Reserved" 3 "Invalid" ;
VAL_ 586 ESL_ShiftLeverPositionrequest 0 " Center" 1 " Up" 2 " Down" 3 " Up, Up" 4 " Down, Down" 5 " Reserved" 15 " Invalid" ;
VAL_ 586 ESL_ShiftLeverPositionFaultSts 0 "normal" 1 "Degraded" 2 "Limphome" 3 "Fault" ;
VAL_ 727 HU_DVRDrivingPlaySwitchStatus 0 "Not Active" 1 "Open" 2 "Close" 3 "Invalid" ;
VAL_ 727 HU_ScreenOperateStatus 0 "released" 1 "pressed" 3 " Reserved" ;
VAL_ 727 HU_3DHorAngleReq 0 "inactive" 1 "0~360°" 362 "reserved" 511 "invalid" ;
VAL_ 727 HU_DVRMode 0 "Inactive" 1 "RealTimeMode" 2 "ReplayMode" 3 "SettingMode" ;
VAL_ 727 HU_AVMswitch 0 "no request " 1 "request" ;
VAL_ 727 HU_DVRDisplayVision 0 "No Request" 1 "Front" 2 "Rear" 3 "Left" 4 "Right" 5 "All" 6 "Reserved" 7 "Invalid" ;
VAL_ 727 HU_AVMTriggermethod 0 "no request" 1 "硬按键触发" 2 "语音触发" 3 "软开关触发" 4 "坡道触发" 5 "reserved" ;
VAL_ 833 PCU_PwrTqWhMinVld 0 "invalid" 1 "valid" ;
VAL_ 833 PCU_PwrTqWhMaxVld 0 "invalid" 1 "valid" ;
VAL_ 833 PCU_AccPedShield 0 "Not Shield" 1 "Shield" ;
VAL_ 982 SLCM_RRWindowStatus 255 "Invalid" ;
VAL_ 982 SLCM_FRWindowStatus 255 "Invalid" ;
VAL_ 984 SLCM_RLWinMotor 0 "Stopped" 1 "Window close" 2 "Window open" 3 "Reserved" ;
VAL_ 984 SLCM_DriverWinMotor 0 "Stopped" 1 "Window close" 2 "Window open" 3 "Reserved" ;
VAL_ 984 SLCM_FailStatus 0 "No error" 1 "Error" ;
VAL_ 984 SLCM_RLWindowSwitch 0 "No input" 1 "Manual Up" 2 "Manual Down" 3 "Reserved" 5 "Auto Up" 6 "Auto Down" 7 "Reserved" ;
VAL_ 984 SLCM_DriverWindowSwitch 0 "No input" 1 "Manual Up" 2 "Manual Down" 3 "Reserved" 5 "Auto Up" 6 "Auto Down" 7 "Reserved" ;
VAL_ 984 SLCM_RLWindowAPActice 0 "Inactive" 1 "Active" ;
VAL_ 984 SLCM_DriverWindowAPActice 0 "Inactive" 1 "Active" ;
VAL_ 984 SLCM_RLWindowInitializedSts 0 "De-Initialized" 1 "Initialized" ;
VAL_ 984 SLCM_DriverWindowInitializedSts 0 "De-Initialized" 1 "Initialized" ;
VAL_ 984 SLCM_RLWindowStatus 255 "Invalid" ;
VAL_ 984 SLCM_DriverWindowStatus 255 "Invalid" ;
VAL_ 990 DSM_DSMBackrestPositionSts 0 "Inactive" 1 "0%~100%" 204 "Reserved" 255 "Invalid" ;
VAL_ 990 DSM_DSMVerticalPositionSts 0 "Inactive" 1 "0%~100%" 204 "Reserved" 255 "Invalid" ;
VAL_ 990 DSM_DSMFrontEndPositionSts 0 "Inactive" 1 "0%~100%" 204 "Reserved" 255 "Invalid" ;
VAL_ 990 DSM_DSMHorizontalPositionSts 0 "Inactive" 1 "0%~100%" 204 "Reserved" 255 "Invalid" ;
VAL_ 1006 GW_SafCertSts 0 "Inactive 非认证状态" 1 "Success成功" 2 "failed失败" 3 "无效值" ;
VAL_ 723 ACC_CRCCheck_283 0 "0xFF，XOR value=0xFF，input data reflected=No，Result data reflected=No，check=0x48，Magic check=0xC4）" ;
VAL_ 723 ACC_AEBTargetLatRange_for_SRS 0 "-50-50m" 1001 "reserved" ;
VAL_ 723 ACC_CRCCheckr_282 0 "0xFF，XOR value=0xFF，input data reflected=No，Result data reflected=No，check=0x48，Magic check=0xC4）" ;
VAL_ 723 ACC_AEBTargetType_for_SRS 0 "no display" 1 "sedan" 2 "motorcycle" 3 "pedestrian" 4 "Bicycle" 5 "Bus" 6 "reserved" 7 "truck" 8 "reserved" 15 "other" ;
VAL_ 723 ACC_AEBTargetTTC_for_SRS 0 "0.01~2.50" 250 "Time to Impact more than 2.5s and valid" 251 "Timeout" 252 "reserve" 254 "Invaild" ;
VAL_ 723 ACC_AEBTargetRelSpeed_for_SRS 0 "-250-250" 501 "reserved" ;
VAL_ 723 ACC_AEBTargetLngRange_for_SRS 0 "-70~180" 501 "reserved" 511 "no display" ;
VAL_ 723 ACC_AEBActive_for_SRS 0 "not Active" 1 "Active." ;
VAL_ 723 ACC_AEBStatus_for_SRS 0 "off" 1 "on" 2 " reserved" 3 "failure" ;
VAL_ 769 ACC_ResetSts 0 "Valid" 1 "GW请求复位" 2 "自身判断复位" 3 "不满足复位条件" 4 "Reserve" 7 "Invalid" ;
VAL_ 780 LAS_ResetSts 0 "Valid" 1 "GW请求复位" 2 "自身判断复位" 3 "不满足复位条件" 4 "Reserve" 7 "Invalid" ;
VAL_ 738 RLR_ElkOBJ2_Measured 0 "unknown" 1 "Measured" 2 "Predicted" 3 "Reserved" ;
VAL_ 738 RLR_ElkOBJ2_Location 0 "unknown" 1 "Left Lane" 2 "Right  Lane" 3 "Ego Lane" ;
VAL_ 738 RLR_ElkOBJ2_Type 0 "Not Detected" 1 "car" 2 "truck" 3 "bicycle/motorbike" 4 "pedestrian" 5 "general" 6 "animal" 7 "uncertain" ;
VAL_ 738 RLR_ElkOBJ1_Measured 0 "unknown" 1 "Measured" 2 "Predicted" 3 "Reserved" ;
VAL_ 738 RLR_ElkOBJ1_Location 0 "unknown" 1 "Left Lane" 2 "Right  Lane" 3 "Ego Lane" ;
VAL_ 738 RLR_ElkOBJ1_Type 0 "Not Detected" 1 "car" 2 "truck" 3 "bicycle/motorbike" 4 "pedestrian" 5 "general" 6 "animal" 7 "uncertain" ;
VAL_ 739 RLR_ElkOBJ4_Measured 0 "unknown" 1 "Measured" 2 "Predicted" 3 "Reserved" ;
VAL_ 739 RLR_ElkOBJ4_Location 0 "unknown" 1 "Left Lane" 2 "Right  Lane" 3 "Ego Lane" ;
VAL_ 739 RLR_ElkOBJ4_Type 0 "Not Detected" 1 "car" 2 "truck" 3 "bicycle/motorbike" 4 "pedestrian" 5 "general" 6 "animal" 7 "uncertain" ;
VAL_ 739 RLR_ElkOBJ3_Measured 0 "unknown" 1 "Measured" 2 "Predicted" 3 "Reserved" ;
VAL_ 739 RLR_ElkOBJ3_Location 0 "unknown" 1 "Left Lane" 2 "Right  Lane" 3 "Ego Lane" ;
VAL_ 739 RLR_ElkOBJ3_Type 0 "Not Detected" 1 "car" 2 "truck" 3 "bicycle/motorbike" 4 "pedestrian" 5 "general" 6 "animal" 7 "uncertain" ;
VAL_ 713 HU_Novice_Response 0 "inactive" 1 "确认" 2 "取消" ;
VAL_ 713 HU_InterfaceChangeSingnal 0 "Still" 1 "Press" 2 "Left" 3 "Right" 4 "Up" 5 "Down" 6 "TwoSides" 7 "reserved" ;
VAL_ 1405 HU_APAOnOff 0 "invalid" 1 "OFF" 2 "ON" 3 "reserved" ;
VAL_ 1304 BCM_CarMode 0 "车辆处于用户模式 " 1 " 车辆处于工厂模式" 2 "车辆处于运输模式" 3 " Reserved" ;
VAL_ 686 LCDAL_SystemStatus 0 "Reserved" 1 "StartUp" 2 "Running" 3 "Blocked" 4 "Calibration" 5 "ShutDown" 6 "Hot" 7 "Failure" ;
VAL_ 985 ACC_ObsTarget10ID 0 "not detect" 1 "1~30" 31 "invalid" ;
VAL_ 985 ACC_ObsTarget10Type 0 "no display" 1 "Cone Consideration" 2 "Warning Column" 3 "Water Horse" 4 "Anti-Collision Bucket" 5 "Emergancy Triangles" 6 "others" 7 "reserved" ;
VAL_ 985 ACC_ObsTarget10LatRange 0 "-50~50" 1001 "reserved" ;
VAL_ 985 ACC_ObsTarget10LngRange 0 "-20~120" 1401 "reserved" ;
VAL_ 985 ACC_ObsTarget9ID 0 "not detect" 1 "1~30" 31 "invalid" ;
VAL_ 985 ACC_ObsTarget9Type 0 "no display" 1 "Cone Consideration" 2 "Warning Column" 3 "Water Horse" 4 "Anti-Collision Bucket" 5 "Emergancy Triangles" 6 "others" 7 "reserved" ;
VAL_ 985 ACC_ObsTarget9LatRange 0 "-50~50" 1001 "reserved" ;
VAL_ 985 ACC_ObsTarget9LngRange 0 "-20~120" 1401 "reserved" ;
VAL_ 985 ACC_ObsTarget8ID 0 "not detect" 1 "1~30" 31 "invalid" ;
VAL_ 985 ACC_ObsTarget8Type 0 "no display" 1 "Cone Consideration" 2 "Warning Column" 3 "Water Horse" 4 "Anti-Collision Bucket" 5 "Emergancy Triangles" 6 "others" 7 "reserved" ;
VAL_ 985 ACC_ObsTarget8LatRange 0 "-50~50" 1001 "reserved" ;
VAL_ 985 ACC_ObsTarget8LngRange 0 "-20~120" 1401 "reserved" ;
VAL_ 985 ACC_ObsTarget7ID 0 "not detect" 1 "1~30" 31 "invalid" ;
VAL_ 985 ACC_ObsTarget7Type 0 "no display" 1 "Cone Consideration" 2 "Warning Column" 3 "Water Horse" 4 "Anti-Collision Bucket" 5 "Emergancy Triangles" 6 "others" 7 "reserved" ;
VAL_ 985 ACC_ObsTarget7LatRange 0 "-50~50" 1001 "reserved" ;
VAL_ 985 ACC_ObsTarget7LngRange 0 "-20~120" 1401 "reserved" ;
VAL_ 985 ACC_ObsTarget6ID 0 "not detect" 1 "1~30" 31 "invalid" ;
VAL_ 985 ACC_ObsTarget6Type 0 "no display" 1 "Cone Consideration" 2 "Warning Column" 3 "Water Horse" 4 "Anti-Collision Bucket" 5 "Emergancy Triangles" 6 "others" 7 "reserved" ;
VAL_ 985 ACC_ObsTarget6LatRange 0 "-50~50" 1001 "reserved" ;
VAL_ 985 ACC_ObsTarget6LngRange 0 "-20~120" 1401 "reserved" ;
VAL_ 985 ACC_ObsTarget5ID 0 "not detect" 1 "1~30" 31 "invalid" ;
VAL_ 985 ACC_ObsTarget5Type 0 "no display" 1 "Cone Consideration" 2 "Warning Column" 3 "Water Horse" 4 "Anti-Collision Bucket" 5 "Emergancy Triangles" 6 "others" 7 "reserved" ;
VAL_ 985 ACC_ObsTarget5LatRange 0 "-50~50" 1001 "reserved" ;
VAL_ 985 ACC_ObsTarget5LngRange 0 "-20~120" 1401 "reserved" ;
VAL_ 985 ACC_ObsTarget4ID 0 "not detect" 1 "1~30" 31 "invalid" ;
VAL_ 985 ACC_ObsTarget4Type 0 "no display" 1 "Cone Consideration" 2 "Warning Column" 3 "Water Horse" 4 "Anti-Collision Bucket" 5 "Emergancy Triangles" 6 "others" 7 "reserved" ;
VAL_ 985 ACC_ObsTarget4LatRange 0 "-50~50" 1001 "reserved" ;
VAL_ 985 ACC_ObsTarget4LngRange 0 "-20~120" 1401 "reserved" ;
VAL_ 985 ACC_ObsTarget3ID 0 "not detect" 1 "1~30" 31 "invalid" ;
VAL_ 985 ACC_ObsTarget3Type 0 "no display" 1 "Cone Consideration" 2 "Warning Column" 3 "Water Horse" 4 "Anti-Collision Bucket" 5 "Emergancy Triangles" 6 "others" 7 "reserved" ;
VAL_ 985 ACC_ObsTarget3LatRange 0 "-50~50" 1001 "reserved" ;
VAL_ 985 ACC_ObsTarget3LngRange 0 "-20~120" 1401 "reserved" ;
VAL_ 985 ACC_ObsTarget2ID 0 "not detect" 1 "1~30" 31 "invalid" ;
VAL_ 985 ACC_ObsTarget2Type 0 "no display" 1 "Cone Consideration" 2 "Warning Column" 3 "Water Horse" 4 "Anti-Collision Bucket" 5 "Emergancy Triangles" 6 "others" 7 "reserved" ;
VAL_ 985 ACC_ObsTarget2LatRange 0 "-50~50" 1001 "reserved" ;
VAL_ 985 ACC_ObsTarget2LngRange 0 "-20~120" 1401 "reserved" ;
VAL_ 985 ACC_ObsTarget1ID 0 "not detect" 1 "1~30" 31 "invalid" ;
VAL_ 985 ACC_ObsTarget1Type 0 "no display" 1 "Cone Consideration" 2 "Warning Column" 3 "Water Horse" 4 "Anti-Collision Bucket" 5 "Emergancy Triangles" 6 "others" 7 "reserved" ;
VAL_ 985 ACC_ObsTarget1LatRange 0 "-50~50" 1001 "reserved" ;
VAL_ 985 ACC_ObsTarget1LngRange 0 "-20~120" 1401 "reserved" ;
VAL_ 987 ACC_ObsTarget20ID 0 "not detect" 1 "1~30" 31 "invalid" ;
VAL_ 987 ACC_ObsTarget20Type 0 "no display" 1 "Cone Consideration" 2 "Warning Column" 3 "Water Horse" 4 "Anti-Collision Bucket" 5 "Emergancy Triangles" 6 "others" 7 "reserved" ;
VAL_ 987 ACC_ObsTarget20LatRange 0 "-50~50" 1001 "reserved" ;
VAL_ 987 ACC_ObsTarget20LngRange 0 "-20~120" 1401 "reserved" ;
VAL_ 987 ACC_ObsTarget19ID 0 "not detect" 1 "1~30" 31 "invalid" ;
VAL_ 987 ACC_ObsTarget19Type 0 "no display" 1 "Cone Consideration" 2 "Warning Column" 3 "Water Horse" 4 "Anti-Collision Bucket" 5 "Emergancy Triangles" 6 "others" 7 "reserved" ;
VAL_ 987 ACC_ObsTarget19LatRange 0 "-50~50" 1001 "reserved" ;
VAL_ 987 ACC_ObsTarget19LngRange 0 "-20~120" 1401 "reserved" ;
VAL_ 987 ACC_ObsTarget18ID 0 "not detect" 1 "1~30" 31 "invalid" ;
VAL_ 987 ACC_ObsTarget18Type 0 "no display" 1 "Cone Consideration" 2 "Warning Column" 3 "Water Horse" 4 "Anti-Collision Bucket" 5 "Emergancy Triangles" 6 "others" 7 "reserved" ;
VAL_ 987 ACC_ObsTarget18LatRange 0 "-50~50" 1001 "reserved" ;
VAL_ 987 ACC_ObsTarget18LngRange 0 "-20~120" 1401 "reserved" ;
VAL_ 987 ACC_ObsTarget17ID 0 "not detect" 1 "1~30" 31 "invalid" ;
VAL_ 987 ACC_ObsTarget17Type 0 "no display" 1 "Cone Consideration" 2 "Warning Column" 3 "Water Horse" 4 "Anti-Collision Bucket" 5 "Emergancy Triangles" 6 "others" 7 "reserved" ;
VAL_ 987 ACC_ObsTarget17LatRange 0 "-50~50" 1001 "reserved" ;
VAL_ 987 ACC_ObsTarget17LngRange 0 "-20~120" 1401 "reserved" ;
VAL_ 987 ACC_ObsTarget16ID 0 "not detect" 1 "1~30" 31 "invalid" ;
VAL_ 987 ACC_ObsTarget16Type 0 "no display" 1 "Cone Consideration" 2 "Warning Column" 3 "Water Horse" 4 "Anti-Collision Bucket" 5 "Emergancy Triangles" 6 "others" 7 "reserved" ;
VAL_ 987 ACC_ObsTarget16LatRange 0 "-50~50" 1001 "reserved" ;
VAL_ 987 ACC_ObsTarget16LngRange 0 "-20~120" 1401 "reserved" ;
VAL_ 987 ACC_ObsTarget15ID 0 "not detect" 1 "1~30" 31 "invalid" ;
VAL_ 987 ACC_ObsTarget15Type 0 "no display" 1 "Cone Consideration" 2 "Warning Column" 3 "Water Horse" 4 "Anti-Collision Bucket" 5 "Emergancy Triangles" 6 "others" 7 "reserved" ;
VAL_ 987 ACC_ObsTarget15LatRange 0 "-50~50" 1001 "reserved" ;
VAL_ 987 ACC_ObsTarget15LngRange 0 "-20~120" 1401 "reserved" ;
VAL_ 987 ACC_ObsTarget14ID 0 "not detect" 1 "1~30" 31 "invalid" ;
VAL_ 987 ACC_ObsTarget14Type 0 "no display" 1 "Cone Consideration" 2 "Warning Column" 3 "Water Horse" 4 "Anti-Collision Bucket" 5 "Emergancy Triangles" 6 "others" 7 "reserved" ;
VAL_ 987 ACC_ObsTarget14LatRange 0 "-50~50" 1001 "reserved" ;
VAL_ 987 ACC_ObsTarget14LngRange 0 "-20~120" 1401 "reserved" ;
VAL_ 987 ACC_ObsTarget13ID 0 "not detect" 1 "1~30" 31 "invalid" ;
VAL_ 987 ACC_ObsTarget13Type 0 "no display" 1 "Cone Consideration" 2 "Warning Column" 3 "Water Horse" 4 "Anti-Collision Bucket" 5 "Emergancy Triangles" 6 "others" 7 "reserved" ;
VAL_ 987 ACC_ObsTarget13LatRange 0 "-50~50" 1001 "reserved" ;
VAL_ 987 ACC_ObsTarget13LngRange 0 "-20~120" 1401 "reserved" ;
VAL_ 987 ACC_ObsTarget12ID 0 "not detect" 1 "1~30" 31 "invalid" ;
VAL_ 987 ACC_ObsTarget12Type 0 "no display" 1 "Cone Consideration" 2 "Warning Column" 3 "Water Horse" 4 "Anti-Collision Bucket" 5 "Emergancy Triangles" 6 "others" 7 "reserved" ;
VAL_ 987 ACC_ObsTarget12LatRange 0 "-50~50" 1001 "reserved" ;
VAL_ 987 ACC_ObsTarget12LngRange 0 "-20~120" 1401 "reserved" ;
VAL_ 987 ACC_ObsTarget11ID 0 "not detect" 1 "1~30" 31 "invalid" ;
VAL_ 987 ACC_ObsTarget11Type 0 "no display" 1 "Cone Consideration" 2 "Warning Column" 3 "Water Horse" 4 "Anti-Collision Bucket" 5 "Emergancy Triangles" 6 "others" 7 "reserved" ;
VAL_ 987 ACC_ObsTarget11LatRange 0 "-50~50" 1001 "reserved" ;
VAL_ 987 ACC_ObsTarget11LngRange 0 "-20~120" 1401 "reserved" ;
VAL_ 881 PCU_DrvMod2 0 "Inactive" 1 "ECO" 2 "normal" 3 "sport" 4 "自定义1" 5 "专属模式" 6 "Reserved" ;
VAL_ 881 PCU_SpecialModeSetFB 0 "reserved" 1 "reserved" 2 "长途模式" 3 "山地模式" 4 "应急模式" 5 "驻车模式" 6 "Super Race" ;
VAL_ 796 PCU_VcuRdySts 0 "no Ready" 1 "Ready" ;
VAL_ 796 PCU_PowerOutputSts 0 "inactive" 1 "佛系" 2 "普通" 3 "激进" 4 "Reserved（保留）" 7 "Invalid" ;
VAL_ 266 ESP_RWU_ParkingAvailForACC 0 "Available" 1 "not available" ;
VAL_ 266 ESP_RWU_ParkingActiveForACC 0 "Active" 1 "not Active" ;
VAL_ 266 EPB_SwitchPositionValid 0 "valid _full function" 1 "error, init or substitute value (no function)" ;
VAL_ 266 EPB_SwitchPosition 0 "no request" 1 "Release request" 2 "Apply request" 3 "Error" ;
VAL_ 266 EPB_Status 0 "both brakes released" 1 "both brakes applied" 2 "both brakes in operation (applying/releasing)" 3 "unknown" ;
VAL_ 266 EPB_FailStatus 0 "no error in EPB – external apply available" 1 "not defined" 2 "not defined" 3 "error in EPB – no external apply allowed" ;
VAL_ 266 EPB_APArequest_Available 0 "notavailable" 1 "available" ;
VAL_ 266 EPB_AchievedClampForce 0 "ClampForce" 30 "Reserved" 31 "Error" ;
VAL_ 349 ESP_IMUCalibrated 0 "Calibrated" 1 "Not Calibrated" ;
VAL_ 271 IBCU_sOutputRodAct_Q 0 "SoutputRodAct_NotInitialized" 1 "SoutputRodAct_Normal" 2 "SoutputRodAct_Faulty" ;
VAL_ 271 IBCU_sOutputRodDriver_Q 0 "soutputRodDriver_NotInitialized未初始化" 1 "soutputRodDriver_Normal正常" 2 "soutputRodDriver_Faulty错误" ;
VAL_ 810 TRM_ConnectSts 0 "NoConnected" 1 "Connected" ;
VAL_ 958 ATS_CurrentDrivingMode 0 " normal" 1 " snow（冰雪）" 2 " mud（泥地）" 3 " sand（沙地）" 4 " rock（岩石）" 5 " wade（涉水）" 6 " protect" ;
VAL_ 890 VMC_CtrlLevelRRValid 0 "Valid" 1 "Invalid" ;
VAL_ 890 VMC_CtrlLevelRLyValid 0 "Valid" 1 "Invalid" ;
VAL_ 890 VMC_CtrlLevelFRValid 0 "Valid" 1 "Invalid" ;
VAL_ 890 VMC_CtrlLevelFLValid 0 "Valid" 1 "Invalid" ;
VAL_ 890 VMC_EcasModeRELSts 0 "idle" 1 "up" 2 "down" ;
VAL_ 890 VMC_EcasModeFRTSts 0 "idle" 1 "up" 2 "down" ;
VAL_ 890 VMC_EcasModeCHASts 0 "no Switch request" 1 "Switching" 2 "Switch fail" 3 "reading to Switch " ;
VAL_ 890 VMC_EcasModeVal 0 "Disable" 1 "Enable" ;
VAL_ 890 VMC_EcdcMode 0 "inactive" 1 "Comfort" 2 "Normal" 3 "Sport" 4 "Auto" ;
VAL_ 890 VMC_EcasMode 0 "inactive" 1 "Normal" 2 "sport" 3 "Off road " 4 "Auto " ;
